VERSION ""

NS_ :

BS_:

BU_: ETH

BO_ 1469 IBST_alertLog: 8 Vector__XXX
 SG_ IBST_alertID : 0|8@1+ (1,0) [0|0] "" Vector__XXX
 SG_ IBST_alertState : 15|1@1+ (1,0) [0|0] "" Vector__XXX

BO_ 1481 APS_alertLog: 8 Vector__XXX
 SG_ APS_alertID M : 0|14@1+ (1,0) [0|0] "" Vector__XXX
 SG_ APS_alertSource : 14|1@1+ (1,0) [0|0] "" Vector__XXX
 SG_ APS_alertState : 15|1@1+ (1,0) [0|0] "" Vector__XXX
 SG_ APS_sw001_APS_alertDataW0 m1 : 16|16@1+ (1,0) [0|0] "" Vector__XXX
 SG_ APS_sw004_radIssue m4 : 16|1@1+ (1,0) [0|0] "" Vector__XXX
 SG_ APS_sw005_AutofixOutOfCalib m5 : 16|1@1+ (1,0) [0|0] "" Vector__XXX
 SG_ APS_sw006_RadarLowVisibility m6 : 16|1@1+ (1,0) [0|0] "" Vector__XXX
 SG_ APS_sw009_DIaebState_fault m9 : 16|1@1+ (1,0) [0|0] "" Vector__XXX
 SG_ APS_sw010_a04calibNotDone m10 : 16|1@1+ (1,0) [0|0] "" Vector__XXX
 SG_ APS_sw011_scaState m11 : 16|3@1+ (1,0) [0|0] "" Vector__XXX
 SG_ APS_sw012_bootTestResults m12 : 16|16@1+ (1,0) [0|0] "" Vector__XXX
 SG_ APS_sw013_stateBeforeWatchdog m13 : 16|5@1+ (1,0) [0|0] "" Vector__XXX
 SG_ APS_sw014_fileNameHash m14 : 16|16@1+ (1,0) [0|0] "" Vector__XXX
 SG_ APS_sw015_RadarLowVisibility m15 : 16|2@1+ (1,0) [0|0] "" Vector__XXX
 SG_ APS_sw016_targetDist m16 : 16|9@1+ (0.2,0) [0|0] "" Vector__XXX
 SG_ APS_sw017_Camera_Msg_Lanes_MIA m17 : 16|1@1+ (1,0) [0|0] "" Vector__XXX
 SG_ APS_sw018_minThreshold m18 : 16|13@1+ (1,0) [0|0] "" Vector__XXX
 SG_ APS_sw019_taskId m19 : 16|8@1+ (1,0) [0|0] "" Vector__XXX
 SG_ APS_sw020_unusedW0 m20 : 16|16@1+ (1,0) [0|0] "" Vector__XXX
 SG_ APS_sw021_tempSensorId m21 : 16|8@1+ (1,0) [0|0] "" Vector__XXX
 SG_ APS_sw022_operation m22 : 16|4@1+ (1,0) [0|0] "" Vector__XXX
 SG_ APS_sw024_Task_ID m24 : 16|4@1+ (1,0) [0|0] "" Vector__XXX
 SG_ APS_sw025_state_before_override m25 : 16|4@1+ (1,0) [0|0] "" Vector__XXX
 SG_ APS_sw026_task_id m26 : 16|2@1+ (1,0) [0|0] "" Vector__XXX
 SG_ APS_sw027_JTAG_Reset m27 : 16|1@1+ (1,0) [0|0] "" Vector__XXX
 SG_ APS_sw028_rx_buffer_full m28 : 16|1@1+ (1,0) [0|0] "" Vector__XXX
 SG_ APS_sw029_tx_buffer_full m29 : 16|1@1+ (1,0) [0|0] "" Vector__XXX
 SG_ APS_sw030_heaterState m30 : 16|8@1+ (1,0) [0|0] "" Vector__XXX
 SG_ APS_sw031_canBus m31 : 16|4@1+ (1,0) [0|0] "" Vector__XXX
 SG_ APS_sw032_canBus m32 : 16|4@1+ (1,0) [0|0] "" Vector__XXX
 SG_ APS_sw033_carConfig m33 : 16|1@1+ (1,0) [0|0] "" Vector__XXX
 SG_ APS_sw034_sccmMia m34 : 16|8@1+ (1,0) [0|0] "" Vector__XXX
 SG_ APS_sw035_wheelSpeeds m35 : 16|1@1+ (1,0) [0|0] "" Vector__XXX
 SG_ APS_sw036_bdyMia m36 : 16|8@1+ (1,0) [0|0] "" Vector__XXX
 SG_ APS_sw037_camera m37 : 16|8@1+ (1,0) [0|0] "" Vector__XXX
 SG_ APS_sw038_RadarMisalignment m38 : 16|1@1+ (1,0) [0|0] "" Vector__XXX
 SG_ APS_sw039_sdm_rcm_Mia m39 : 16|8@1+ (1,0) [0|0] "" Vector__XXX
 SG_ APS_sw040_accel_pedal_pos m40 : 16|8@1+ (0.5,0) [0|0] "" Vector__XXX
 SG_ APS_sw041_rate m41 : 16|10@1- (1,0) [0|0] "" Vector__XXX
 SG_ APS_sw042_health_state m42 : 16|3@1+ (1,0) [0|0] "" Vector__XXX
 SG_ APS_sw043_mobileye_status m43 : 16|16@1+ (1,0) [0|0] "" Vector__XXX
 SG_ APS_sw044_countLSB m44 : 16|8@1+ (1,0) [0|0] "" Vector__XXX
 SG_ APS_sw045_radMia m45 : 16|8@1+ (1,0) [0|0] "" Vector__XXX
 SG_ APS_sw046_recordId m46 : 16|16@1+ (1,0) [0|0] "" Vector__XXX
 SG_ APS_sw047_edrStatus m47 : 16|4@1+ (1,0) [0|0] "" Vector__XXX
 SG_ APS_sw048_swAssert m48 : 16|1@1+ (1,0) [0|0] "" Vector__XXX
 SG_ APS_sw049_boot_version_msw m49 : 16|16@1+ (1,0) [0|0] "" Vector__XXX
 SG_ APS_sw050_targetDist m50 : 16|9@1+ (0.2,0) [0|0] "" Vector__XXX
 SG_ APS_sw051_a01ecuInternalPerf m51 : 16|1@1+ (1,0) [0|0] "" Vector__XXX
 SG_ APS_sw052_a07sensorBlinded m52 : 16|1@1+ (1,0) [0|0] "" Vector__XXX
 SG_ APS_sw053_a10canBusOff m53 : 16|1@1+ (1,0) [0|0] "" Vector__XXX
 SG_ APS_sw054_Autofix_cnvrgnceStatus m54 : 16|8@1+ (1,0) [0|0] "" Vector__XXX
 SG_ APS_sw055_detectedRadcVersion m55 : 16|32@1+ (1,0) [0|0] "" Vector__XXX
 SG_ APS_sw056_diMia m56 : 16|8@1+ (1,0) [0|0] "" Vector__XXX
 SG_ APS_sw057_driverAssistMapData m57 : 16|1@1+ (1,0) [0|0] "" Vector__XXX
 SG_ APS_sw058_epbMia m58 : 16|8@1+ (1,0) [0|0] "" Vector__XXX
 SG_ APS_sw059_sdiFront m59 : 16|1@1+ (1,0) [0|0] "" Vector__XXX
 SG_ APS_sw060_targetDist m60 : 16|9@1+ (0.2,0) [0|0] "" Vector__XXX
 SG_ APS_sw061_states m61 : 16|1@1+ (1,0) [0|0] "" Vector__XXX
 SG_ APS_sw062_HorizontalMisalignment m62 : 16|16@1+ (0.00137332,-45) [0|0] "" Vector__XXX
 SG_ APS_sw063_expectedMajorVer m63 : 16|8@1+ (1,0) [0|0] "" Vector__XXX
 SG_ APS_sw064_sysStatus m64 : 16|1@1+ (1,0) [0|0] "" Vector__XXX
 SG_ APS_sw065_app_mobileye_status m65 : 16|8@1+ (1,0) [0|0] "" Vector__XXX
 SG_ APS_sw066_app_mobileye_status m66 : 16|8@1+ (1,0) [0|0] "" Vector__XXX
 SG_ APS_sw067_sccmSTW m67 : 16|14@1+ (0.1,-819.2) [0|0] "" Vector__XXX
 SG_ APS_sw068_percentConsistency m68 : 16|10@1+ (0.1,0) [0|0] "" Vector__XXX
 SG_ APS_sw069_epasMia m69 : 16|1@1+ (1,0) [0|0] "" Vector__XXX
 SG_ APS_sw070_currTireFitment m70 : 16|3@1+ (1,0) [0|0] "" Vector__XXX
 SG_ APS_sw071_selfParkType m71 : 16|4@1+ (1,0) [0|0] "" Vector__XXX
 SG_ APS_sw072_vehicleX m72 : 16|10@1+ (0.05,-25.6) [0|0] "" Vector__XXX
 SG_ APS_sw073_escalateLDWs m73 : 16|1@1+ (1,0) [0|0] "" Vector__XXX
 SG_ APS_sw074_ipsoDx m74 : 16|6@1+ (2,0) [0|0] "" Vector__XXX
 SG_ APS_sw075_scMia m75 : 16|8@1+ (1,0) [0|0] "" Vector__XXX
 SG_ APS_sw076_targetDist m76 : 16|9@1+ (0.2,0) [0|0] "" Vector__XXX
 SG_ APS_sw077_oocDistance m77 : 16|9@1+ (1,0) [0|0] "" Vector__XXX
 SG_ APS_sw078_camCipv_dx m78 : 16|8@1+ (0.2,0) [0|0] "" Vector__XXX
 SG_ APS_sw080_sensors_healty_check m80 : 16|1@1+ (1,0) [0|0] "" Vector__XXX
 SG_ APS_sw081_radarDistance m81 : 16|8@1+ (0.0625,0) [0|0] "" Vector__XXX
 SG_ APS_sw082_L_VL m82 : 16|8@1+ (0.05,-6.4) [0|0] "" Vector__XXX
 SG_ APS_sw083_Targ5_RCS m83 : 16|16@1+ (0.0039063096,0) [0|0] "" Vector__XXX
 SG_ APS_sw084_ipsoTTC m84 : 16|8@1+ (0.02,0) [0|0] "" Vector__XXX
 SG_ APS_sw085_radarDistance m85 : 16|8@1+ (0.0625,0) [0|0] "" Vector__XXX
 SG_ APS_sw086_distanceException m86 : 16|8@1+ (1,90) [0|0] "" Vector__XXX
 SG_ APS_sw103_objectDx m103 : 16|8@1+ (0.5,0) [0|0] "" Vector__XXX
 SG_ APS_sw106_torsionBarOffset m106 : 16|8@1+ (0.005,-0.64) [0|0] "" Vector__XXX
 SG_ APS_sw129_currentVoltage m129 : 16|14@1+ (1,0) [0|0] "" Vector__XXX
 SG_ APS_sw130_currentTemperature m130 : 16|8@1- (1,0) [0|0] "" Vector__XXX
 SG_ APS_sw131_trapAddr m131 : 16|32@1+ (1,0) [0|0] "" Vector__XXX
 SG_ APS_sw132_mismatchType m132 : 16|1@1+ (1,0) [0|0] "" Vector__XXX
 SG_ APS_sw133_failedInitStep m133 : 16|8@1+ (1,0) [0|0] "" Vector__XXX
 SG_ APS_sw134_appCamCalibStatus m134 : 16|1@1+ (1,0) [0|0] "" Vector__XXX
 SG_ APS_sw135_appCriticalReason m135 : 16|4@1+ (1,0) [0|0] "" Vector__XXX
 SG_ APS_sw136_gpsCommIrrecoverable m136 : 16|1@1+ (1,0) [0|0] "" Vector__XXX
 SG_ APS_sw137_gpsCommMissing m137 : 16|1@1+ (1,0) [0|0] "" Vector__XXX
 SG_ APS_sw138_cfgBufNull m138 : 16|1@1+ (1,0) [0|0] "" Vector__XXX
 SG_ APS_sw139_numMessagesRx m139 : 16|8@1+ (1,0) [0|0] "" Vector__XXX
 SG_ APS_sw140_lvPowerState m140 : 16|1@1+ (1,0) [0|0] "" Vector__XXX
 SG_ APS_sw141_inertial1 m141 : 16|1@1+ (1,0) [0|0] "" Vector__XXX
 SG_ APS_sw142_speed m142 : 16|1@1+ (1,0) [0|0] "" Vector__XXX
 SG_ APS_sw143_status m143 : 16|1@1+ (1,0) [0|0] "" Vector__XXX
 SG_ APS_sw144_restraintStatus m144 : 16|1@1+ (1,0) [0|0] "" Vector__XXX
 SG_ APS_sw145_restraintStatus m145 : 16|1@1+ (1,0) [0|0] "" Vector__XXX
 SG_ APS_sw146_sysStatus m146 : 16|1@1+ (1,0) [0|0] "" Vector__XXX
 SG_ APS_sw147_doorStatus m147 : 16|1@1+ (1,0) [0|0] "" Vector__XXX
 SG_ APS_sw148_doorStatus m148 : 16|1@1+ (1,0) [0|0] "" Vector__XXX
 SG_ APS_sw149_status m149 : 16|1@1+ (1,0) [0|0] "" Vector__XXX
 SG_ APS_sw150_steeringAngleSensor m150 : 16|1@1+ (1,0) [0|0] "" Vector__XXX
 SG_ APS_sw151_apGpioState m151 : 16|2@1+ (1,0) [0|0] "" Vector__XXX
 SG_ APS_sw152_fusionStatus m152 : 16|2@1+ (1,0) [0|0] "" Vector__XXX
 SG_ APS_sw153_eacInhibitReason m153 : 16|4@1+ (1,0) [0|0] "" Vector__XXX
 SG_ APS_sw155_InUnicastError m155 : 16|1@1+ (1,0) [0|0] "" Vector__XXX
 SG_ APS_sw156_LWIPAssertLine m156 : 16|16@1+ (1,0) [0|0] "" Vector__XXX
 SG_ APS_sw158_apbInfo m158 : 16|1@1+ (1,0) [0|0] "" Vector__XXX
 SG_ APS_sw159_apbCriticalReason m159 : 16|4@1+ (1,0) [0|0] "" Vector__XXX
 SG_ APS_sw160_mismatchType m160 : 16|1@1+ (1,0) [0|0] "" Vector__XXX
 SG_ APS_sw161_antennaDisconnected m161 : 16|1@1+ (1,0) [0|0] "" Vector__XXX
 SG_ APS_sw162_disRegPgoodFail m162 : 16|1@1+ (1,0) [0|0] "" Vector__XXX
 SG_ APS_sw171_1HzTask m171 : 16|1@1+ (1,0) [0|0] "" Vector__XXX
 SG_ APS_sw172_prolongedUiMia m172 : 16|1@1+ (1,0) [0|0] "" Vector__XXX
 SG_ APS_sw187_1HzTask m187 : 16|1@1+ (1,0) [0|0] "" Vector__XXX
 SG_ APS_sw188_otherTurbo m188 : 16|2@1+ (1,0) [0|0] "" Vector__XXX
 SG_ APS_sw189_AP_vehicleState10Hz m189 : 16|1@1+ (1,0) [0|0] "" Vector__XXX
 SG_ APS_sw190_IBST_status m190 : 16|1@1+ (1,0) [0|0] "" Vector__XXX
 SG_ APS_sw191_a72Uninitialized m191 : 16|1@1+ (1,0) [0|0] "" Vector__XXX
 SG_ APS_sw192_CANbus m192 : 16|3@1+ (1,0) [0|0] "" Vector__XXX
 SG_ APS_sw193_blurredImage m193 : 16|1@1+ (1,0) [0|0] "" Vector__XXX
 SG_ APS_sw194_leadAx m194 : 16|6@1- (0.2,0) [0|0] "" Vector__XXX
 SG_ APS_sw195_s1Blocked m195 : 16|1@1+ (1,0) [0|0] "" Vector__XXX
 SG_ APS_sw198_fullBlockage m198 : 16|1@1+ (1,0) [0|0] "" Vector__XXX
 SG_ APS_sw199_abortCodeDas m199 : 16|6@1+ (1,0) [0|0] "" Vector__XXX
 SG_ APS_sw200_autopilotIntState m200 : 16|4@1+ (1,0) [0|0] "" Vector__XXX
 SG_ APS_sw201_virtualLaneInputOAL m201 : 16|3@1+ (1,0) [0|0] "" Vector__XXX
 SG_ APS_sw202_s1Blocked m202 : 16|1@1+ (1,0) [0|0] "" Vector__XXX
 SG_ APS_sw203_controlType m203 : 16|4@1+ (1,0) [0|0] "" Vector__XXX
 SG_ APS_sw204_frLeft m204 : 16|8@1+ (1,0) [0|0] "" Vector__XXX
 SG_ APS_sw205_oocDistance m205 : 16|8@1+ (1,0) [0|0] "" Vector__XXX
 SG_ APS_sw207_appMobileyeStatus m207 : 16|8@1+ (1,0) [0|0] "" Vector__XXX
 SG_ APS_sw213_autopilotIntState m213 : 16|4@1+ (1,0) [0|0] "" Vector__XXX
 SG_ APS_sw218_cipvDist m218 : 16|8@1+ (0.2,0) [0|0] "" Vector__XXX
 SG_ APS_sw219_controlledAccess m219 : 16|1@1+ (1,0) [0|0] "" Vector__XXX
 SG_ APS_sw220_controlledAccess m220 : 16|1@1+ (1,0) [0|0] "" Vector__XXX
 SG_ APS_sw227_sensorSide m227 : 16|1@1+ (1,0) [0|0] "" Vector__XXX
 SG_ APS_sw230_sensor1Blocked m230 : 16|1@1+ (1,0) [0|0] "" Vector__XXX
 SG_ APS_sw231_timeToImpact m231 : 16|9@1+ (1,0) [0|0] "" Vector__XXX
 SG_ APS_sw235_resetOrigin m235 : 16|2@1+ (1,0) [0|0] "" Vector__XXX
 SG_ APS_sw236_fifoSizeInvalid m236 : 16|1@1+ (1,0) [0|0] "" Vector__XXX
 SG_ APS_sw237_faultSource m237 : 16|7@1+ (1,0) [0|0] "" Vector__XXX
 SG_ APS_sw238_shutdownPin m238 : 16|1@1+ (1,0) [0|0] "" Vector__XXX
 SG_ APS_sw241_unknownVendorOnResume m241 : 16|1@1+ (1,0) [0|0] "" Vector__XXX
 SG_ APS_sw242_instance m242 : 16|3@1+ (1,0) [0|0] "" Vector__XXX
 SG_ APS_sw243_instance m243 : 16|3@1+ (1,0) [0|0] "" Vector__XXX
 SG_ APS_sw244_instance m244 : 16|3@1+ (1,0) [0|0] "" Vector__XXX
 SG_ APS_sw245_unknownMACAddrByte0 m245 : 16|8@1+ (1,0) [0|0] "" Vector__XXX
 SG_ APS_sw246_ethloopSwitchPort0 m246 : 16|1@1+ (1,0) [0|0] "" Vector__XXX
 SG_ APS_sw247_crcError m247 : 16|1@1+ (1,0) [0|0] "" Vector__XXX
 SG_ APS_sw248_ethloopSwitchPort2Sqi m248 : 16|3@1+ (1,0) [0|0] "" Vector__XXX
 SG_ APS_sw249_ufsInitFailureReason m249 : 16|3@1+ (1,0) [0|0] "" Vector__XXX
 SG_ APS_sw250_rxPacketDrop m250 : 16|12@1+ (1,0) [0|0] "" Vector__XXX
 SG_ APS_sw251_rxPacketDrop m251 : 16|12@1+ (1,0) [0|0] "" Vector__XXX
 SG_ APS_sw252_ethSwitchPort2 m252 : 16|1@1+ (1,0) [0|0] "" Vector__XXX
 SG_ APS_sw253_apWaitForShutdownTimeout m253 : 16|1@1+ (1,0) [0|0] "" Vector__XXX
 SG_ APS_sw254_waitForBusSilenceTimeout m254 : 16|1@1+ (1,0) [0|0] "" Vector__XXX
 SG_ APS_sw255_unknownBootError m255 : 16|1@1+ (1,0) [0|0] "" Vector__XXX
 SG_ APS_sw257_assertAddress m257 : 16|32@1+ (1,0) [0|0] "" Vector__XXX
 SG_ APS_sw258_actualValue m258 : 16|32@1+ (1,0) [0|0] "" Vector__XXX
 SG_ APS_sw259_qspiProgramError m259 : 16|1@1+ (1,0) [0|0] "" Vector__XXX
 SG_ APS_sw260_pgoodTripSramStatus m260 : 16|8@1+ (1,0) [0|0] "" Vector__XXX
 SG_ APS_sw261_vrmPublicFaultValues m261 : 16|16@1+ (1,0) [0|0] "" Vector__XXX
 SG_ APS_sw262_vrmPublicFaultValues m262 : 16|16@1+ (1,0) [0|0] "" Vector__XXX
 SG_ APS_sw263_vrmPublicFaultValues m263 : 16|16@1+ (1,0) [0|0] "" Vector__XXX
 SG_ APS_sw264_rdlvl_bitlock m264 : 16|1@1+ (1,0) [0|0] "" Vector__XXX
 SG_ APS_sw265_rdlvl_bitlock m265 : 16|1@1+ (1,0) [0|0] "" Vector__XXX
 SG_ APS_sw266_rdlvl_bitlock m266 : 16|1@1+ (1,0) [0|0] "" Vector__XXX
 SG_ APS_sw267_rdlvl_bitlock m267 : 16|1@1+ (1,0) [0|0] "" Vector__XXX
 SG_ APS_sw268_rd_uncorrectable_crc0 m268 : 16|1@1+ (1,0) [0|0] "" Vector__XXX
 SG_ APS_sw269_RxPageCountPort0 m269 : 16|12@1+ (1,0) [0|0] "" Vector__XXX
 SG_ APS_sw270_RxPageCountPort4 m270 : 16|12@1+ (1,0) [0|0] "" Vector__XXX
 SG_ APS_sw271_wrUncorrectableErrInBufferToDram m271 : 16|1@1+ (1,0) [0|0] "" Vector__XXX
 SG_ APS_sw272_wrUncorrectableErrInBufferToDram m272 : 16|1@1+ (1,0) [0|0] "" Vector__XXX
 SG_ APS_sw273_wrUncorrectableErrInBufferToDram m273 : 16|1@1+ (1,0) [0|0] "" Vector__XXX
 SG_ APS_sw274_wrUncorrectableErrInBufferToDram m274 : 16|1@1+ (1,0) [0|0] "" Vector__XXX
 SG_ APS_sw275_wrUncorrectableErrInBufferToDram m275 : 16|1@1+ (1,0) [0|0] "" Vector__XXX
 SG_ APS_sw276_wrUncorrectableErrInBufferToDram m276 : 16|1@1+ (1,0) [0|0] "" Vector__XXX
 SG_ APS_sw277_wrUncorrectableErrInBufferToDram m277 : 16|1@1+ (1,0) [0|0] "" Vector__XXX
 SG_ APS_sw278_wrUncorrectableErrInBufferToDram m278 : 16|1@1+ (1,0) [0|0] "" Vector__XXX
 SG_ APS_sw279_corruptDirectorySource m279 : 16|3@1+ (1,0) [0|0] "" Vector__XXX
 SG_ APS_sw280_pepsStatus m280 : 16|1@1+ (1,0) [0|0] "" Vector__XXX
 SG_ APS_sw281_rearSteerStatus m281 : 16|1@1+ (1,0) [0|0] "" Vector__XXX
 SG_ APS_sw282_smmuErrorId m282 : 16|3@1+ (1,0) [0|0] "" Vector__XXX
 SG_ APS_sw283_psfaStatus m283 : 16|1@1+ (1,0) [0|0] "" Vector__XXX
 SG_ APS_sw288_status m288 : 16|1@1+ (1,0) [0|0] "" Vector__XXX
 SG_ APS_sw289_turboTemperature m289 : 16|8@1- (1,0) [0|0] "" Vector__XXX
 SG_ APS_sw291_fifoError m291 : 16|1@1+ (1,0) [0|0] "" Vector__XXX
 SG_ APS_sw292_warningErrorCount m292 : 16|8@1+ (1,0) [0|0] "" Vector__XXX
 SG_ APS_sw293_warningErrorCount m293 : 16|8@1+ (1,0) [0|0] "" Vector__XXX
 SG_ APS_sw294_warningErrorCount m294 : 16|8@1+ (1,0) [0|0] "" Vector__XXX
 SG_ APS_sw295_warningErrorCount m295 : 16|8@1+ (1,0) [0|0] "" Vector__XXX
 SG_ APS_sw296_wdogMonTaskID m296 : 16|5@1+ (1,0) [0|0] "" Vector__XXX
 SG_ APS_sw297_earlyWDog m297 : 16|1@1+ (1,0) [0|0] "" Vector__XXX
 SG_ APS_sw298_cpuToApFailedCount m298 : 16|8@1+ (1,0) [0|0] "" Vector__XXX
 SG_ APS_sw299_apToCpuFailedCount m299 : 16|8@1+ (1,0) [0|0] "" Vector__XXX
 SG_ APS_sw300_messageRingMagicValue m300 : 16|32@1+ (1,0) [0|0] "" Vector__XXX
 SG_ APS_sw301_nocType m301 : 16|4@1+ (1,0) [0|0] "" Vector__XXX
 SG_ APS_sw302_cpuToApFifoFullCount m302 : 16|8@1+ (1,0) [0|0] "" Vector__XXX
 SG_ APS_sw303_apToCpuFifoEmptyCount m303 : 16|8@1+ (1,0) [0|0] "" Vector__XXX
 SG_ APS_sw304_exceptionCode m304 : 16|5@1+ (1,0) [0|0] "" Vector__XXX
 SG_ APS_sw307_secEvent m307 : 16|8@1+ (1,0) [0|0] "" Vector__XXX
 SG_ APS_sw308_pmicWatchDogFeedError m308 : 16|1@1+ (1,0) [0|0] "" Vector__XXX
 SG_ APS_sw310_sysStatus m310 : 16|1@1+ (1,0) [0|0] "" Vector__XXX
 SG_ APS_sw311_dasAutonomyControl m311 : 16|1@1+ (1,0) [0|0] "" Vector__XXX
 SG_ APS_sw312_appStatus m312 : 16|1@1+ (1,0) [0|0] "" Vector__XXX
 SG_ APS_sw313_warningErrorCount m313 : 16|8@1+ (1,0) [0|0] "" Vector__XXX
 SG_ APS_sw315_sysStatus m315 : 16|1@1+ (1,0) [0|0] "" Vector__XXX
 SG_ APS_sw316_powerCameraTimeout m316 : 16|1@1+ (1,0) [0|0] "" Vector__XXX
 SG_ APS_sw004_radHWFailure m4 : 17|1@1+ (1,0) [0|0] "" Vector__XXX
 SG_ APS_sw005_AutofixOutOfCalibYaw m5 : 17|1@1+ (1,0) [0|0] "" Vector__XXX
 SG_ APS_sw006_RadarMisaligned m6 : 17|1@1+ (1,0) [0|0] "" Vector__XXX
 SG_ APS_sw009_DI_aeb_unresponsive m9 : 17|1@1+ (1,0) [0|0] "" Vector__XXX
 SG_ APS_sw010_a05calibReqd m10 : 17|1@1+ (1,0) [0|0] "" Vector__XXX
 SG_ APS_sw017_Camera_Msg_Objects_MIA m17 : 17|1@1+ (1,0) [0|0] "" Vector__XXX
 SG_ APS_sw027_Core_Reset m27 : 17|1@1+ (1,0) [0|0] "" Vector__XXX
 SG_ APS_sw028_rx_inv_len m28 : 17|1@1+ (1,0) [0|0] "" Vector__XXX
 SG_ APS_sw029_unusedBits m29 : 17|15@1+ (1,0) [0|0] "" Vector__XXX
 SG_ APS_sw033_chNm m33 : 17|1@1+ (1,0) [0|0] "" Vector__XXX
 SG_ APS_sw035_status m35 : 17|1@1+ (1,0) [0|0] "" Vector__XXX
 SG_ APS_sw038_OutOfFocusImage m38 : 17|1@1+ (1,0) [0|0] "" Vector__XXX
 SG_ APS_sw048_thermalIssue m48 : 17|1@1+ (1,0) [0|0] "" Vector__XXX
 SG_ APS_sw051_a02flashPerformance m51 : 17|1@1+ (1,0) [0|0] "" Vector__XXX
 SG_ APS_sw052_sensorDirty m52 : 17|1@1+ (1,0) [0|0] "" Vector__XXX
 SG_ APS_sw053_a11bdyMIA m53 : 17|1@1+ (1,0) [0|0] "" Vector__XXX
 SG_ APS_sw057_locationStatus m57 : 17|1@1+ (1,0) [0|0] "" Vector__XXX
 SG_ APS_sw059_sdiRear m59 : 17|1@1+ (1,0) [0|0] "" Vector__XXX
 SG_ APS_sw064_status m64 : 17|1@1+ (1,0) [0|0] "" Vector__XXX
 SG_ APS_sw069_espMia m69 : 17|1@1+ (1,0) [0|0] "" Vector__XXX
 SG_ APS_sw073_silentEscalatedLDW m73 : 17|1@1+ (1,0) [0|0] "" Vector__XXX
 SG_ APS_sw080_dist_travelled_check m80 : 17|1@1+ (1,0) [0|0] "" Vector__XXX
 SG_ APS_sw134_appCameraLux m134 : 17|1@1+ (1,0) [0|0] "" Vector__XXX
 SG_ APS_sw136_fusionIrrecoverable m136 : 17|1@1+ (1,0) [0|0] "" Vector__XXX
 SG_ APS_sw137_gpsJunkData m137 : 17|1@1+ (1,0) [0|0] "" Vector__XXX
 SG_ APS_sw138_invalidID m138 : 17|1@1+ (1,0) [0|0] "" Vector__XXX
 SG_ APS_sw140_vehicleStatus m140 : 17|1@1+ (1,0) [0|0] "" Vector__XXX
 SG_ APS_sw141_inertial2 m141 : 17|1@1+ (1,0) [0|0] "" Vector__XXX
 SG_ APS_sw142_locStatus m142 : 17|1@1+ (1,0) [0|0] "" Vector__XXX
 SG_ APS_sw143_wheelRotation m143 : 17|1@1+ (1,0) [0|0] "" Vector__XXX
 SG_ APS_sw146_status m146 : 17|1@1+ (1,0) [0|0] "" Vector__XXX
 SG_ APS_sw147_switchStatus m147 : 17|1@1+ (1,0) [0|0] "" Vector__XXX
 SG_ APS_sw148_hvacStatus m148 : 17|1@1+ (1,0) [0|0] "" Vector__XXX
 SG_ APS_sw150_rightStalk m150 : 17|1@1+ (1,0) [0|0] "" Vector__XXX
 SG_ APS_sw155_UDPRecvError m155 : 17|1@1+ (1,0) [0|0] "" Vector__XXX
 SG_ APS_sw158_apbStatus m158 : 17|1@1+ (1,0) [0|0] "" Vector__XXX
 SG_ APS_sw162_disRegPgoodDbnFail m162 : 17|1@1+ (1,0) [0|0] "" Vector__XXX
 SG_ APS_sw171_1kHzTask m171 : 17|1@1+ (1,0) [0|0] "" Vector__XXX
 SG_ APS_sw172_uiMiaAtBootup m172 : 17|1@1+ (1,0) [0|0] "" Vector__XXX
 SG_ APS_sw187_1kHzTask m187 : 17|1@1+ (1,0) [0|0] "" Vector__XXX
 SG_ APS_sw189_AP_vehicleState1Hz m189 : 17|1@1+ (1,0) [0|0] "" Vector__XXX
 SG_ APS_sw191_a72PhaseError m191 : 17|1@1+ (1,0) [0|0] "" Vector__XXX
 SG_ APS_sw193_fullBlockage m193 : 17|1@1+ (1,0) [0|0] "" Vector__XXX
 SG_ APS_sw195_s6Blocked m195 : 17|1@1+ (1,0) [0|0] "" Vector__XXX
 SG_ APS_sw198_partialBlockage m198 : 17|1@1+ (1,0) [0|0] "" Vector__XXX
 SG_ APS_sw202_s6Blocked m202 : 17|1@1+ (1,0) [0|0] "" Vector__XXX
 SG_ APS_sw219_roadClass m219 : 17|3@1+ (1,0) [0|0] "" Vector__XXX
 SG_ APS_sw220_roadClass m220 : 17|3@1+ (1,0) [0|0] "" Vector__XXX
 SG_ APS_sw227_sensorNumber m227 : 17|1@1+ (1,0) [0|0] "" Vector__XXX
 SG_ APS_sw230_sensor2Blocked m230 : 17|1@1+ (1,0) [0|0] "" Vector__XXX
 SG_ APS_sw236_nocRemapInvalid m236 : 17|1@1+ (1,0) [0|0] "" Vector__XXX
 SG_ APS_sw238_externalWatchdog m238 : 17|1@1+ (1,0) [0|0] "" Vector__XXX
 SG_ APS_sw241_unknownVendorOnNonResume m241 : 17|1@1+ (1,0) [0|0] "" Vector__XXX
 SG_ APS_sw246_ethloopSwitchPort1 m246 : 17|1@1+ (1,0) [0|0] "" Vector__XXX
 SG_ APS_sw247_dribbleError m247 : 17|1@1+ (1,0) [0|0] "" Vector__XXX
 SG_ APS_sw253_apOffPrepareTimeout m253 : 17|1@1+ (1,0) [0|0] "" Vector__XXX
 SG_ APS_sw254_sleepReadyTimeout m254 : 17|1@1+ (1,0) [0|0] "" Vector__XXX
 SG_ APS_sw255_adcWrapperInitBootError m255 : 17|1@1+ (1,0) [0|0] "" Vector__XXX
 SG_ APS_sw259_qspiEraseError m259 : 17|1@1+ (1,0) [0|0] "" Vector__XXX
 SG_ APS_sw264_rdlvl_vref_not_in_range m264 : 17|1@1+ (1,0) [0|0] "" Vector__XXX
 SG_ APS_sw265_rdlvl_vref_not_in_range m265 : 17|1@1+ (1,0) [0|0] "" Vector__XXX
 SG_ APS_sw266_rdlvl_vref_not_in_range m266 : 17|1@1+ (1,0) [0|0] "" Vector__XXX
 SG_ APS_sw267_rdlvl_vref_not_in_range m267 : 17|1@1+ (1,0) [0|0] "" Vector__XXX
 SG_ APS_sw268_rd_correctable_crc0 m268 : 17|1@1+ (1,0) [0|0] "" Vector__XXX
 SG_ APS_sw271_rdUncorrectableErrFromBuffer m271 : 17|1@1+ (1,0) [0|0] "" Vector__XXX
 SG_ APS_sw272_rdUncorrectableErrFromBuffer m272 : 17|1@1+ (1,0) [0|0] "" Vector__XXX
 SG_ APS_sw273_rdUncorrectableErrFromBuffer m273 : 17|1@1+ (1,0) [0|0] "" Vector__XXX
 SG_ APS_sw274_rdUncorrectableErrFromBuffer m274 : 17|1@1+ (1,0) [0|0] "" Vector__XXX
 SG_ APS_sw275_rdUncorrectableErrFromBuffer m275 : 17|1@1+ (1,0) [0|0] "" Vector__XXX
 SG_ APS_sw276_rdUncorrectableErrFromBuffer m276 : 17|1@1+ (1,0) [0|0] "" Vector__XXX
 SG_ APS_sw277_rdUncorrectableErrFromBuffer m277 : 17|1@1+ (1,0) [0|0] "" Vector__XXX
 SG_ APS_sw278_rdUncorrectableErrFromBuffer m278 : 17|1@1+ (1,0) [0|0] "" Vector__XXX
 SG_ APS_sw291_crcError m291 : 17|1@1+ (1,0) [0|0] "" Vector__XXX
 SG_ APS_sw297_wdogMonStatus m297 : 17|4@1+ (1,0) [0|0] "" Vector__XXX
 SG_ APS_sw310_status m310 : 17|1@1+ (1,0) [0|0] "" Vector__XXX
 SG_ APS_sw311_dasControl m311 : 17|1@1+ (1,0) [0|0] "" Vector__XXX
 SG_ APS_sw312_apbStatus m312 : 17|1@1+ (1,0) [0|0] "" Vector__XXX
 SG_ APS_sw315_status m315 : 17|1@1+ (1,0) [0|0] "" Vector__XXX
 SG_ APS_sw004_radSensorBlind m4 : 18|1@1+ (1,0) [0|0] "" Vector__XXX
 SG_ APS_sw005_RadarMisalignment m5 : 18|1@1+ (1,0) [0|0] "" Vector__XXX
 SG_ APS_sw006_radCalibration m6 : 18|1@1+ (1,0) [0|0] "" Vector__XXX
 SG_ APS_sw009_DI_MIA m9 : 18|1@1+ (1,0) [0|0] "" Vector__XXX
 SG_ APS_sw010_a06calibNotOK m10 : 18|1@1+ (1,0) [0|0] "" Vector__XXX
 SG_ APS_sw015_RadarMisalignment m15 : 18|2@1+ (1,0) [0|0] "" Vector__XXX
 SG_ APS_sw017_Camera_Msg_Tsr_MIA m17 : 18|1@1+ (1,0) [0|0] "" Vector__XXX
 SG_ APS_sw026_tardiness m26 : 18|9@1+ (0.25,0) [0|0] "" Vector__XXX
 SG_ APS_sw027_Unused_Bit_0 m27 : 18|1@1+ (1,0) [0|0] "" Vector__XXX
 SG_ APS_sw028_inv_multifrm_1st m28 : 18|1@1+ (1,0) [0|0] "" Vector__XXX
 SG_ APS_sw033_vin m33 : 18|1@1+ (1,0) [0|0] "" Vector__XXX
 SG_ APS_sw035_wheelRotation m35 : 18|1@1+ (1,0) [0|0] "" Vector__XXX
 SG_ APS_sw038_AutofixOutOfCalib m38 : 18|1@1+ (1,0) [0|0] "" Vector__XXX
 SG_ APS_sw048_powerIssue m48 : 18|1@1+ (1,0) [0|0] "" Vector__XXX
 SG_ APS_sw051_a03vBatHigh m51 : 18|1@1+ (1,0) [0|0] "" Vector__XXX
 SG_ APS_sw052_HWFail m52 : 18|1@1+ (1,0) [0|0] "" Vector__XXX
 SG_ APS_sw053_a12espMIA m53 : 18|1@1+ (1,0) [0|0] "" Vector__XXX
 SG_ APS_sw057_gpsVehicleSpeed m57 : 18|1@1+ (1,0) [0|0] "" Vector__XXX
 SG_ APS_sw059_status m59 : 18|1@1+ (1,0) [0|0] "" Vector__XXX
 SG_ APS_sw069_parkMia m69 : 18|1@1+ (1,0) [0|0] "" Vector__XXX
 SG_ APS_sw073_escalateLDWreason m73 : 18|3@1+ (1,0) [0|0] "" Vector__XXX
 SG_ APS_sw080_road_class_check m80 : 18|1@1+ (1,0) [0|0] "" Vector__XXX
 SG_ APS_sw134_appInfo m134 : 18|1@1+ (1,0) [0|0] "" Vector__XXX
 SG_ APS_sw136_antennaUnplugged m136 : 18|1@1+ (1,0) [0|0] "" Vector__XXX
 SG_ APS_sw137_gpsNMEAmissing m137 : 18|1@1+ (1,0) [0|0] "" Vector__XXX
 SG_ APS_sw138_gpsBufferOverflow m138 : 18|1@1+ (1,0) [0|0] "" Vector__XXX
 SG_ APS_sw140_status m140 : 18|1@1+ (1,0) [0|0] "" Vector__XXX
 SG_ APS_sw142_locStatus2 m142 : 18|1@1+ (1,0) [0|0] "" Vector__XXX
 SG_ APS_sw143_wheelSpeeds m143 : 18|1@1+ (1,0) [0|0] "" Vector__XXX
 SG_ APS_sw150_leftStalk m150 : 18|1@1+ (1,0) [0|0] "" Vector__XXX
 SG_ APS_sw151_apWatchDogState m151 : 18|3@1+ (1,0) [0|0] "" Vector__XXX
 SG_ APS_sw155_UDPMiscError m155 : 18|1@1+ (1,0) [0|0] "" Vector__XXX
 SG_ APS_sw158_dasAutonomyControlParty m158 : 18|1@1+ (1,0) [0|0] "" Vector__XXX
 SG_ APS_sw162_pwrPgoodFail m162 : 18|1@1+ (1,0) [0|0] "" Vector__XXX
 SG_ APS_sw188_arbUartMiaState m188 : 18|1@1+ (1,0) [0|0] "" Vector__XXX
 SG_ APS_sw191_smsPhaseError m191 : 18|1@1+ (1,0) [0|0] "" Vector__XXX
 SG_ APS_sw193_impairedVD m193 : 18|1@1+ (1,0) [0|0] "" Vector__XXX
 SG_ APS_sw195_s7Blocked m195 : 18|1@1+ (1,0) [0|0] "" Vector__XXX
 SG_ APS_sw198_tflMsgInvalid m198 : 18|1@1+ (1,0) [0|0] "" Vector__XXX
 SG_ APS_sw202_s7Blocked m202 : 18|1@1+ (1,0) [0|0] "" Vector__XXX
 SG_ APS_sw227_vehicleSpeed m227 : 18|12@1+ (0.05,-25) [0|0] "" Vector__XXX
 SG_ APS_sw230_sensor3Blocked m230 : 18|1@1+ (1,0) [0|0] "" Vector__XXX
 SG_ APS_sw235_generalUnrecoverable m235 : 18|1@1+ (1,0) [0|0] "" Vector__XXX
 SG_ APS_sw236_txFifoInvalid m236 : 18|1@1+ (1,0) [0|0] "" Vector__XXX
 SG_ APS_sw238_hardReset m238 : 18|1@1+ (1,0) [0|0] "" Vector__XXX
 SG_ APS_sw241_phyReinitFailedOnResume m241 : 18|1@1+ (1,0) [0|0] "" Vector__XXX
 SG_ APS_sw246_ethloopSwitchPort2 m246 : 18|1@1+ (1,0) [0|0] "" Vector__XXX
 SG_ APS_sw247_receiveError m247 : 18|1@1+ (1,0) [0|0] "" Vector__XXX
 SG_ APS_sw253_apSuspendedTimeout m253 : 18|1@1+ (1,0) [0|0] "" Vector__XXX
 SG_ APS_sw254_sleepingTimeout m254 : 18|1@1+ (1,0) [0|0] "" Vector__XXX
 SG_ APS_sw255_boardRevisionInitBootError m255 : 18|1@1+ (1,0) [0|0] "" Vector__XXX
 SG_ APS_sw264_rdlvl_vref_training m264 : 18|1@1+ (1,0) [0|0] "" Vector__XXX
 SG_ APS_sw265_rdlvl_vref_training m265 : 18|1@1+ (1,0) [0|0] "" Vector__XXX
 SG_ APS_sw266_rdlvl_vref_training m266 : 18|1@1+ (1,0) [0|0] "" Vector__XXX
 SG_ APS_sw267_rdlvl_vref_training m267 : 18|1@1+ (1,0) [0|0] "" Vector__XXX
 SG_ APS_sw268_wr_uncorrectable_crc0 m268 : 18|1@1+ (1,0) [0|0] "" Vector__XXX
 SG_ APS_sw271_rdCorrectableErrFromMemory m271 : 18|1@1+ (1,0) [0|0] "" Vector__XXX
 SG_ APS_sw272_rdCorrectableErrFromMemory m272 : 18|1@1+ (1,0) [0|0] "" Vector__XXX
 SG_ APS_sw273_rdCorrectableErrFromMemory m273 : 18|1@1+ (1,0) [0|0] "" Vector__XXX
 SG_ APS_sw274_rdCorrectableErrFromMemory m274 : 18|1@1+ (1,0) [0|0] "" Vector__XXX
 SG_ APS_sw275_rdCorrectableErrFromMemory m275 : 18|1@1+ (1,0) [0|0] "" Vector__XXX
 SG_ APS_sw276_rdCorrectableErrFromMemory m276 : 18|1@1+ (1,0) [0|0] "" Vector__XXX
 SG_ APS_sw277_rdCorrectableErrFromMemory m277 : 18|1@1+ (1,0) [0|0] "" Vector__XXX
 SG_ APS_sw278_rdCorrectableErrFromMemory m278 : 18|1@1+ (1,0) [0|0] "" Vector__XXX
 SG_ APS_sw291_invalidDiscretizationTime m291 : 18|1@1+ (1,0) [0|0] "" Vector__XXX
 SG_ APS_sw311_dasLongControl m311 : 18|1@1+ (1,0) [0|0] "" Vector__XXX
 SG_ APS_sw004_radSGUFailure m4 : 19|1@1+ (1,0) [0|0] "" Vector__XXX
 SG_ APS_sw005_partialBlockage m5 : 19|1@1+ (1,0) [0|0] "" Vector__XXX
 SG_ APS_sw006_OutOfFocusImage m6 : 19|1@1+ (1,0) [0|0] "" Vector__XXX
 SG_ APS_sw010_a08PlantMode m10 : 19|1@1+ (1,0) [0|0] "" Vector__XXX
 SG_ APS_sw011_scaLeft m11 : 19|1@1+ (1,0) [0|0] "" Vector__XXX
 SG_ APS_sw017_Camera_Msg_Hlb_MIA m17 : 19|1@1+ (1,0) [0|0] "" Vector__XXX
 SG_ APS_sw027_CPU_Checkstop_Error m27 : 19|1@1+ (1,0) [0|0] "" Vector__XXX
 SG_ APS_sw028_inv_multifrm_id m28 : 19|1@1+ (1,0) [0|0] "" Vector__XXX
 SG_ APS_sw033_carState m33 : 19|1@1+ (1,0) [0|0] "" Vector__XXX
 SG_ APS_sw035_redundantBrakingStatus m35 : 19|1@1+ (1,0) [0|0] "" Vector__XXX
 SG_ APS_sw038_AutofixOutOfCalibHorzn m38 : 19|1@1+ (1,0) [0|0] "" Vector__XXX
 SG_ APS_sw042_abort_reason m42 : 19|5@1+ (1,0) [0|0] "" Vector__XXX
 SG_ APS_sw048_stackOverflow m48 : 19|1@1+ (1,0) [0|0] "" Vector__XXX
 SG_ APS_sw051_a09configMismatch m51 : 19|1@1+ (1,0) [0|0] "" Vector__XXX
 SG_ APS_sw052_overTemperature m52 : 19|1@1+ (1,0) [0|0] "" Vector__XXX
 SG_ APS_sw053_a13gtwMIA m53 : 19|1@1+ (1,0) [0|0] "" Vector__XXX
 SG_ APS_sw057_autopilotControl m57 : 19|1@1+ (1,0) [0|0] "" Vector__XXX
 SG_ APS_sw059_sensorStatusFront m59 : 19|1@1+ (1,0) [0|0] "" Vector__XXX
 SG_ APS_sw069_sccmMia m69 : 19|1@1+ (1,0) [0|0] "" Vector__XXX
 SG_ APS_sw070_lastTireFitment m70 : 19|3@1+ (1,0) [0|0] "" Vector__XXX
 SG_ APS_sw080_stw_angle_check m80 : 19|1@1+ (1,0) [0|0] "" Vector__XXX
 SG_ APS_sw134_appStatus m134 : 19|1@1+ (1,0) [0|0] "" Vector__XXX
 SG_ APS_sw136_badgpsfix m136 : 19|1@1+ (1,0) [0|0] "" Vector__XXX
 SG_ APS_sw137_gpsUBXmissing m137 : 19|1@1+ (1,0) [0|0] "" Vector__XXX
 SG_ APS_sw138_navx5CfgFailed m138 : 19|1@1+ (1,0) [0|0] "" Vector__XXX
 SG_ APS_sw140_lighting m140 : 19|1@1+ (1,0) [0|0] "" Vector__XXX
 SG_ APS_sw142_systemStatus m142 : 19|1@1+ (1,0) [0|0] "" Vector__XXX
 SG_ APS_sw143_redundantBrakingStatus m143 : 19|1@1+ (1,0) [0|0] "" Vector__XXX
 SG_ APS_sw155_UDPRTEError m155 : 19|1@1+ (1,0) [0|0] "" Vector__XXX
 SG_ APS_sw158_dasAutonomyControlVeh m158 : 19|1@1+ (1,0) [0|0] "" Vector__XXX
 SG_ APS_sw162_pwrPgoodDbnFail m162 : 19|1@1+ (1,0) [0|0] "" Vector__XXX
 SG_ APS_sw188_powerUartMiaState m188 : 19|1@1+ (1,0) [0|0] "" Vector__XXX
 SG_ APS_sw191_a72Timeout m191 : 19|1@1+ (1,0) [0|0] "" Vector__XXX
 SG_ APS_sw192_SWTxQueueFull m192 : 19|1@1+ (1,0) [0|0] "" Vector__XXX
 SG_ APS_sw193_outOfFocusImage m193 : 19|1@1+ (1,0) [0|0] "" Vector__XXX
 SG_ APS_sw195_s8Blocked m195 : 19|1@1+ (1,0) [0|0] "" Vector__XXX
 SG_ APS_sw198_tsrMsgInvalid m198 : 19|1@1+ (1,0) [0|0] "" Vector__XXX
 SG_ APS_sw201_steeringErrorOAL m201 : 19|3@1+ (1,0) [0|0] "" Vector__XXX
 SG_ APS_sw202_s8Blocked m202 : 19|1@1+ (1,0) [0|0] "" Vector__XXX
 SG_ APS_sw230_sensor4Blocked m230 : 19|1@1+ (1,0) [0|0] "" Vector__XXX
 SG_ APS_sw235_pgoodUnrecoverable m235 : 19|1@1+ (1,0) [0|0] "" Vector__XXX
 SG_ APS_sw236_rxFifoInvalid m236 : 19|1@1+ (1,0) [0|0] "" Vector__XXX
 SG_ APS_sw238_junctionTemperature m238 : 19|1@1+ (1,0) [0|0] "" Vector__XXX
 SG_ APS_sw241_phyReinitFailedOnNonResume m241 : 19|1@1+ (1,0) [0|0] "" Vector__XXX
 SG_ APS_sw242_clusterSRAMMBISTFailed m242 : 19|1@1+ (1,0) [0|0] "" Vector__XXX
 SG_ APS_sw246_ethloopSwitchPort3 m246 : 19|1@1+ (1,0) [0|0] "" Vector__XXX
 SG_ APS_sw247_wdogTimeout m247 : 19|1@1+ (1,0) [0|0] "" Vector__XXX
 SG_ APS_sw248_ethloopSwitchPort3Sqi m248 : 19|3@1+ (1,0) [0|0] "" Vector__XXX
 SG_ APS_sw253_socOffReadyTimeout m253 : 19|1@1+ (1,0) [0|0] "" Vector__XXX
 SG_ APS_sw255_i2cInitBootError m255 : 19|1@1+ (1,0) [0|0] "" Vector__XXX
 SG_ APS_sw264_rdlvl_byte_misalignment m264 : 19|1@1+ (1,0) [0|0] "" Vector__XXX
 SG_ APS_sw265_rdlvl_byte_misalignment m265 : 19|1@1+ (1,0) [0|0] "" Vector__XXX
 SG_ APS_sw266_rdlvl_byte_misalignment m266 : 19|1@1+ (1,0) [0|0] "" Vector__XXX
 SG_ APS_sw267_rdlvl_byte_misalignment m267 : 19|1@1+ (1,0) [0|0] "" Vector__XXX
 SG_ APS_sw268_wr_correctable_crc0 m268 : 19|1@1+ (1,0) [0|0] "" Vector__XXX
 SG_ APS_sw271_ddrRdCorrectableErrThreshold m271 : 19|1@1+ (1,0) [0|0] "" Vector__XXX
 SG_ APS_sw272_ddrRdCorrectableErrThreshold m272 : 19|1@1+ (1,0) [0|0] "" Vector__XXX
 SG_ APS_sw273_ddrRdCorrectableErrThreshold m273 : 19|1@1+ (1,0) [0|0] "" Vector__XXX
 SG_ APS_sw274_ddrRdCorrectableErrThreshold m274 : 19|1@1+ (1,0) [0|0] "" Vector__XXX
 SG_ APS_sw275_ddrRdCorrectableErrThreshold m275 : 19|1@1+ (1,0) [0|0] "" Vector__XXX
 SG_ APS_sw276_ddrRdCorrectableErrThreshold m276 : 19|1@1+ (1,0) [0|0] "" Vector__XXX
 SG_ APS_sw277_ddrRdCorrectableErrThreshold m277 : 19|1@1+ (1,0) [0|0] "" Vector__XXX
 SG_ APS_sw278_ddrRdCorrectableErrThreshold m278 : 19|1@1+ (1,0) [0|0] "" Vector__XXX
 SG_ APS_sw291_pingPongBufferError m291 : 19|1@1+ (1,0) [0|0] "" Vector__XXX
 SG_ APS_sw311_dasSmartShift m311 : 19|1@1+ (1,0) [0|0] "" Vector__XXX
 SG_ APS_sw004_radMia m4 : 20|1@1+ (1,0) [0|0] "" Vector__XXX
 SG_ APS_sw005_fullBlockage m5 : 20|1@1+ (1,0) [0|0] "" Vector__XXX
 SG_ APS_sw006_SunRay m6 : 20|1@1+ (1,0) [0|0] "" Vector__XXX
 SG_ APS_sw010_HorizontalMisalignment m10 : 20|16@1+ (0.00137332,-45) [0|0] "" Vector__XXX
 SG_ APS_sw011_scaRight m11 : 20|1@1+ (1,0) [0|0] "" Vector__XXX
 SG_ APS_sw015_LowSun m15 : 20|2@1+ (1,0) [0|0] "" Vector__XXX
 SG_ APS_sw017_Camera_Msg_Common_MIA m17 : 20|1@1+ (1,0) [0|0] "" Vector__XXX
 SG_ APS_sw022_recordId m22 : 20|12@1+ (1,0) [0|0] "" Vector__XXX
 SG_ APS_sw024_numVirtualLaneVeh m24 : 20|4@1+ (1,0) [0|0] "" Vector__XXX
 SG_ APS_sw025_road_class m25 : 20|3@1+ (1,0) [0|0] "" Vector__XXX
 SG_ APS_sw027_PLL_0_Failure m27 : 20|1@1+ (1,0) [0|0] "" Vector__XXX
 SG_ APS_sw028_inv_multifrm_next m28 : 20|1@1+ (1,0) [0|0] "" Vector__XXX
 SG_ APS_sw038_AutofixOutOfCalibYaw m38 : 20|1@1+ (1,0) [0|0] "" Vector__XXX
 SG_ APS_sw047_roadClass m47 : 20|3@1+ (1,0) [0|0] "" Vector__XXX
 SG_ APS_sw048_checkStop m48 : 20|1@1+ (1,0) [0|0] "" Vector__XXX
 SG_ APS_sw051_a52radomeHtrInop m51 : 20|1@1+ (1,0) [0|0] "" Vector__XXX
 SG_ APS_sw052_underTemperature m52 : 20|1@1+ (1,0) [0|0] "" Vector__XXX
 SG_ APS_sw053_a14sccmMIA m53 : 20|1@1+ (1,0) [0|0] "" Vector__XXX
 SG_ APS_sw057_driverAssistControl m57 : 20|1@1+ (1,0) [0|0] "" Vector__XXX
 SG_ APS_sw059_pasFrontMiddle m59 : 20|1@1+ (1,0) [0|0] "" Vector__XXX
 SG_ APS_sw069_parkMismatch m69 : 20|1@1+ (1,0) [0|0] "" Vector__XXX
 SG_ APS_sw071_endPosX m71 : 20|10@1+ (0.05,-25.6) [0|0] "" Vector__XXX
 SG_ APS_sw080_rad_tar_5_check m80 : 20|1@1+ (1,0) [0|0] "" Vector__XXX
 SG_ APS_sw134_dasAutonomyControlParty m134 : 20|1@1+ (1,0) [0|0] "" Vector__XXX
 SG_ APS_sw137_fusionModeDisabled m137 : 20|1@1+ (1,0) [0|0] "" Vector__XXX
 SG_ APS_sw138_mcuNMEAmsgUDPinvalid m138 : 20|1@1+ (1,0) [0|0] "" Vector__XXX
 SG_ APS_sw140_sensors m140 : 20|1@1+ (1,0) [0|0] "" Vector__XXX
 SG_ APS_sw142_chassisControl m142 : 20|1@1+ (1,0) [0|0] "" Vector__XXX
 SG_ APS_sw153_eacInternalState m153 : 20|3@1+ (1,0) [0|0] "" Vector__XXX
 SG_ APS_sw155_UDPCheckError m155 : 20|1@1+ (1,0) [0|0] "" Vector__XXX
 SG_ APS_sw158_dasBodyControlsVEH m158 : 20|1@1+ (1,0) [0|0] "" Vector__XXX
 SG_ APS_sw188_faultsUartMiaState m188 : 20|1@1+ (1,0) [0|0] "" Vector__XXX
 SG_ APS_sw191_smsPeerMissing m191 : 20|1@1+ (1,0) [0|0] "" Vector__XXX
 SG_ APS_sw192_Busoff m192 : 20|1@1+ (1,0) [0|0] "" Vector__XXX
 SG_ APS_sw193_partialBlockage m193 : 20|1@1+ (1,0) [0|0] "" Vector__XXX
 SG_ APS_sw195_s11Blocked m195 : 20|1@1+ (1,0) [0|0] "" Vector__XXX
 SG_ APS_sw200_autopilotRestricted m200 : 20|1@1+ (1,0) [0|0] "" Vector__XXX
 SG_ APS_sw202_s11Blocked m202 : 20|1@1+ (1,0) [0|0] "" Vector__XXX
 SG_ APS_sw203_curbType m203 : 20|2@1+ (1,0) [0|0] "" Vector__XXX
 SG_ APS_sw213_autopilotRestricted m213 : 20|1@1+ (1,0) [0|0] "" Vector__XXX
 SG_ APS_sw219_vehicleSpeed m219 : 20|12@1+ (0.05,-25) [0|0] "" Vector__XXX
 SG_ APS_sw220_vehicleSpeed m220 : 20|12@1+ (0.05,-25) [0|0] "" Vector__XXX
 SG_ APS_sw230_sensor5Blocked m230 : 20|1@1+ (1,0) [0|0] "" Vector__XXX
 SG_ APS_sw235_faultUnrecoverable m235 : 20|1@1+ (1,0) [0|0] "" Vector__XXX
 SG_ APS_sw238_overVoltage m238 : 20|1@1+ (1,0) [0|0] "" Vector__XXX
 SG_ APS_sw241_illTestFailed m241 : 20|1@1+ (1,0) [0|0] "" Vector__XXX
 SG_ APS_sw242_SRAMBankMBISTFailed m242 : 20|1@1+ (1,0) [0|0] "" Vector__XXX
 SG_ APS_sw246_ethloopSwitchPort4 m246 : 20|1@1+ (1,0) [0|0] "" Vector__XXX
 SG_ APS_sw247_overflowError m247 : 20|1@1+ (1,0) [0|0] "" Vector__XXX
 SG_ APS_sw253_apInLinuxTimeout m253 : 20|1@1+ (1,0) [0|0] "" Vector__XXX
 SG_ APS_sw255_provisionInitBootError m255 : 20|1@1+ (1,0) [0|0] "" Vector__XXX
 SG_ APS_sw264_rdlvl_read_gate_offset_filter m264 : 20|1@1+ (1,0) [0|0] "" Vector__XXX
 SG_ APS_sw265_rdlvl_read_gate_offset_filter m265 : 20|1@1+ (1,0) [0|0] "" Vector__XXX
 SG_ APS_sw266_rdlvl_read_gate_offset_filter m266 : 20|1@1+ (1,0) [0|0] "" Vector__XXX
 SG_ APS_sw267_rdlvl_read_gate_offset_filter m267 : 20|1@1+ (1,0) [0|0] "" Vector__XXX
 SG_ APS_sw268_vendorIdMismatchMIF0 m268 : 20|1@1+ (1,0) [0|0] "" Vector__XXX
 SG_ APS_sw271_bufferRdCorrectableErrThreshold m271 : 20|1@1+ (1,0) [0|0] "" Vector__XXX
 SG_ APS_sw272_bufferRdCorrectableErrThreshold m272 : 20|1@1+ (1,0) [0|0] "" Vector__XXX
 SG_ APS_sw273_bufferRdCorrectableErrThreshold m273 : 20|1@1+ (1,0) [0|0] "" Vector__XXX
 SG_ APS_sw274_bufferRdCorrectableErrThreshold m274 : 20|1@1+ (1,0) [0|0] "" Vector__XXX
 SG_ APS_sw275_bufferRdCorrectableErrThreshold m275 : 20|1@1+ (1,0) [0|0] "" Vector__XXX
 SG_ APS_sw276_bufferRdCorrectableErrThreshold m276 : 20|1@1+ (1,0) [0|0] "" Vector__XXX
 SG_ APS_sw277_bufferRdCorrectableErrThreshold m277 : 20|1@1+ (1,0) [0|0] "" Vector__XXX
 SG_ APS_sw278_bufferRdCorrectableErrThreshold m278 : 20|1@1+ (1,0) [0|0] "" Vector__XXX
 SG_ APS_sw301_nocIrqId m301 : 20|9@1+ (1,0) [0|0] "" Vector__XXX
 SG_ APS_sw311_dasStatus m311 : 20|1@1+ (1,0) [0|0] "" Vector__XXX
 SG_ APS_sw004_radDynamicsError m4 : 21|1@1+ (1,0) [0|0] "" Vector__XXX
 SG_ APS_sw005_camObjHeader m5 : 21|1@1+ (1,0) [0|0] "" Vector__XXX
 SG_ APS_sw006_Splashes m6 : 21|1@1+ (1,0) [0|0] "" Vector__XXX
 SG_ APS_sw011_scaBlinker m11 : 21|2@1+ (1,0) [0|0] "" Vector__XXX
 SG_ APS_sw013_numEyeqResets m13 : 21|3@1+ (1,0) [0|0] "" Vector__XXX
 SG_ APS_sw017_Camera_Msg_FCW_PCW_MIA m17 : 21|1@1+ (1,0) [0|0] "" Vector__XXX
 SG_ APS_sw027_Clock_Monitor_0_Low m27 : 21|1@1+ (1,0) [0|0] "" Vector__XXX
 SG_ APS_sw028_unusedBits m28 : 21|11@1+ (1,0) [0|0] "" Vector__XXX
 SG_ APS_sw038_FullBlockage m38 : 21|1@1+ (1,0) [0|0] "" Vector__XXX
 SG_ APS_sw048_ecuWatchdog m48 : 21|1@1+ (1,0) [0|0] "" Vector__XXX
 SG_ APS_sw051_unused m51 : 21|3@1+ (1,0) [0|0] "" Vector__XXX
 SG_ APS_sw052_chirpError m52 : 21|1@1+ (1,0) [0|0] "" Vector__XXX
 SG_ APS_sw053_a15adasMIA m53 : 21|1@1+ (1,0) [0|0] "" Vector__XXX
 SG_ APS_sw057_telemetryControl m57 : 21|1@1+ (1,0) [0|0] "" Vector__XXX
 SG_ APS_sw059_sensorStatusRear m59 : 21|1@1+ (1,0) [0|0] "" Vector__XXX
 SG_ APS_sw069_eacStatus m69 : 21|4@1+ (1,0) [0|0] "" Vector__XXX
 SG_ APS_sw073_rawMobileyeLDW m73 : 21|2@1+ (1,0) [0|0] "" Vector__XXX
 SG_ APS_sw080_ultrasonic_obs_check m80 : 21|1@1+ (1,0) [0|0] "" Vector__XXX
 SG_ APS_sw134_dasAutonomyControlVeh m134 : 21|1@1+ (1,0) [0|0] "" Vector__XXX
 SG_ APS_sw137_gpsCfgFail m137 : 21|1@1+ (1,0) [0|0] "" Vector__XXX
 SG_ APS_sw138_mcuDbgMsgInvalid m138 : 21|1@1+ (1,0) [0|0] "" Vector__XXX
 SG_ APS_sw140_coolant m140 : 21|1@1+ (1,0) [0|0] "" Vector__XXX
 SG_ APS_sw151_diGear m151 : 21|3@1+ (1,0) [0|0] "" Vector__XXX
 SG_ APS_sw155_UDPDropError m155 : 21|1@1+ (1,0) [0|0] "" Vector__XXX
 SG_ APS_sw158_dasControl m158 : 21|1@1+ (1,0) [0|0] "" Vector__XXX
 SG_ APS_sw188_sleepUartMiaState m188 : 21|1@1+ (1,0) [0|0] "" Vector__XXX
 SG_ APS_sw192_UncorrectedBitError m192 : 21|1@1+ (1,0) [0|0] "" Vector__XXX
 SG_ APS_sw193_smearedHalos m193 : 21|1@1+ (1,0) [0|0] "" Vector__XXX
 SG_ APS_sw195_s12Blocked m195 : 21|1@1+ (1,0) [0|0] "" Vector__XXX
 SG_ APS_sw200_endSpeed m200 : 21|10@1+ (0.1,-10) [0|0] "" Vector__XXX
 SG_ APS_sw202_s12Blocked m202 : 21|1@1+ (1,0) [0|0] "" Vector__XXX
 SG_ APS_sw213_endSpeed m213 : 21|10@1+ (0.1,-10) [0|0] "" Vector__XXX
 SG_ APS_sw230_sensor6Blocked m230 : 21|1@1+ (1,0) [0|0] "" Vector__XXX
 SG_ APS_sw235_12VFuseUnrecoverable m235 : 21|1@1+ (1,0) [0|0] "" Vector__XXX
 SG_ APS_sw238_underVoltage m238 : 21|1@1+ (1,0) [0|0] "" Vector__XXX
 SG_ APS_sw241_memTestFailed m241 : 21|1@1+ (1,0) [0|0] "" Vector__XXX
 SG_ APS_sw246_ethloopSwitchPort5 m246 : 21|1@1+ (1,0) [0|0] "" Vector__XXX
 SG_ APS_sw247_giantPacket m247 : 21|1@1+ (1,0) [0|0] "" Vector__XXX
 SG_ APS_sw253_apInCorebootTimeout m253 : 21|1@1+ (1,0) [0|0] "" Vector__XXX
 SG_ APS_sw255_rtcInitBootError m255 : 21|1@1+ (1,0) [0|0] "" Vector__XXX
 SG_ APS_sw264_rdlvl_vref_convergence m264 : 21|1@1+ (1,0) [0|0] "" Vector__XXX
 SG_ APS_sw265_rdlvl_vref_convergence m265 : 21|1@1+ (1,0) [0|0] "" Vector__XXX
 SG_ APS_sw266_rdlvl_vref_convergence m266 : 21|1@1+ (1,0) [0|0] "" Vector__XXX
 SG_ APS_sw267_rdlvl_vref_convergence m267 : 21|1@1+ (1,0) [0|0] "" Vector__XXX
 SG_ APS_sw268_rd_uncorrectable_crc1 m268 : 21|1@1+ (1,0) [0|0] "" Vector__XXX
 SG_ APS_sw271_csrParity m271 : 21|1@1+ (1,0) [0|0] "" Vector__XXX
 SG_ APS_sw272_csrParity m272 : 21|1@1+ (1,0) [0|0] "" Vector__XXX
 SG_ APS_sw273_csrParity m273 : 21|1@1+ (1,0) [0|0] "" Vector__XXX
 SG_ APS_sw274_csrParity m274 : 21|1@1+ (1,0) [0|0] "" Vector__XXX
 SG_ APS_sw275_csrParity m275 : 21|1@1+ (1,0) [0|0] "" Vector__XXX
 SG_ APS_sw276_csrParity m276 : 21|1@1+ (1,0) [0|0] "" Vector__XXX
 SG_ APS_sw277_csrParity m277 : 21|1@1+ (1,0) [0|0] "" Vector__XXX
 SG_ APS_sw278_csrParity m278 : 21|1@1+ (1,0) [0|0] "" Vector__XXX
 SG_ APS_sw297_wdogMonTaskID m297 : 21|5@1+ (1,0) [0|0] "" Vector__XXX
 SG_ APS_sw304_addrType m304 : 21|1@1+ (1,0) [0|0] "" Vector__XXX
 SG_ APS_sw311_dasSteeringControl m311 : 21|1@1+ (1,0) [0|0] "" Vector__XXX
 SG_ APS_sw004_espMIA m4 : 22|1@1+ (1,0) [0|0] "" Vector__XXX
 SG_ APS_sw005_camCommonMsg m5 : 22|1@1+ (1,0) [0|0] "" Vector__XXX
 SG_ APS_sw006_BlurredImage m6 : 22|1@1+ (1,0) [0|0] "" Vector__XXX
 SG_ APS_sw015_BlurredImage m15 : 22|2@1+ (1,0) [0|0] "" Vector__XXX
 SG_ APS_sw017_Camera_Msg_TFL_MIA m17 : 22|1@1+ (1,0) [0|0] "" Vector__XXX
 SG_ APS_sw027_Clock_Monitor_0_Off m27 : 22|1@1+ (1,0) [0|0] "" Vector__XXX
 SG_ APS_sw038_TooManyResets m38 : 22|1@1+ (1,0) [0|0] "" Vector__XXX
 SG_ APS_sw048_ecuReset m48 : 22|1@1+ (1,0) [0|0] "" Vector__XXX
 SG_ APS_sw052_rspError m52 : 22|1@1+ (1,0) [0|0] "" Vector__XXX
 SG_ APS_sw053_a16bdyInvalidCount m53 : 22|1@1+ (1,0) [0|0] "" Vector__XXX
 SG_ APS_sw057_chassisControl m57 : 22|1@1+ (1,0) [0|0] "" Vector__XXX
 SG_ APS_sw059_pasRearMiddle m59 : 22|1@1+ (1,0) [0|0] "" Vector__XXX
 SG_ APS_sw080_freespace_check m80 : 22|1@1+ (1,0) [0|0] "" Vector__XXX
 SG_ APS_sw134_dasBodyControlsVEH m134 : 22|1@1+ (1,0) [0|0] "" Vector__XXX
 SG_ APS_sw137_esfStatusMsgMIA m137 : 22|1@1+ (1,0) [0|0] "" Vector__XXX
 SG_ APS_sw138_mcuDbgMsgTooBig m138 : 22|1@1+ (1,0) [0|0] "" Vector__XXX
 SG_ APS_sw140_okToUseHighPower m140 : 22|1@1+ (1,0) [0|0] "" Vector__XXX
 SG_ APS_sw155_UDPMemError m155 : 22|1@1+ (1,0) [0|0] "" Vector__XXX
 SG_ APS_sw158_dasControlPty m158 : 22|1@1+ (1,0) [0|0] "" Vector__XXX
 SG_ APS_sw188_resetUartMiaState m188 : 22|1@1+ (1,0) [0|0] "" Vector__XXX
 SG_ APS_sw192_CorrectedBitError m192 : 22|1@1+ (1,0) [0|0] "" Vector__XXX
 SG_ APS_sw193_smearedSpots m193 : 22|1@1+ (1,0) [0|0] "" Vector__XXX
 SG_ APS_sw194_leadDx m194 : 22|8@1+ (0.1,0) [0|0] "" Vector__XXX
 SG_ APS_sw199_abortCodePARK m199 : 22|5@1+ (1,0) [0|0] "" Vector__XXX
 SG_ APS_sw203_roadClass m203 : 22|3@1+ (1,0) [0|0] "" Vector__XXX
 SG_ APS_sw230_sensor7Blocked m230 : 22|1@1+ (1,0) [0|0] "" Vector__XXX
 SG_ APS_sw235_pgoodLevelUnrcvrble m235 : 22|1@1+ (1,0) [0|0] "" Vector__XXX
 SG_ APS_sw238_resetInput m238 : 22|1@1+ (1,0) [0|0] "" Vector__XXX
 SG_ APS_sw241_dfiInitCompleteTimeout m241 : 22|1@1+ (1,0) [0|0] "" Vector__XXX
 SG_ APS_sw246_ethloopSwitchPort6 m246 : 22|1@1+ (1,0) [0|0] "" Vector__XXX
 SG_ APS_sw247_destAddrFilterFail m247 : 22|1@1+ (1,0) [0|0] "" Vector__XXX
 SG_ APS_sw253_apBootingTimeout m253 : 22|1@1+ (1,0) [0|0] "" Vector__XXX
 SG_ APS_sw255_vrmInitConfigBootError m255 : 22|1@1+ (1,0) [0|0] "" Vector__XXX
 SG_ APS_sw264_rdlvl_cdr_convergence m264 : 22|1@1+ (1,0) [0|0] "" Vector__XXX
 SG_ APS_sw265_rdlvl_cdr_convergence m265 : 22|1@1+ (1,0) [0|0] "" Vector__XXX
 SG_ APS_sw266_rdlvl_cdr_convergence m266 : 22|1@1+ (1,0) [0|0] "" Vector__XXX
 SG_ APS_sw267_rdlvl_cdr_convergence m267 : 22|1@1+ (1,0) [0|0] "" Vector__XXX
 SG_ APS_sw268_rd_correctable_crc1 m268 : 22|1@1+ (1,0) [0|0] "" Vector__XXX
 SG_ APS_sw271_fifoParity0 m271 : 22|1@1+ (1,0) [0|0] "" Vector__XXX
 SG_ APS_sw272_fifoParity0 m272 : 22|1@1+ (1,0) [0|0] "" Vector__XXX
 SG_ APS_sw273_fifoParity0 m273 : 22|1@1+ (1,0) [0|0] "" Vector__XXX
 SG_ APS_sw274_fifoParity0 m274 : 22|1@1+ (1,0) [0|0] "" Vector__XXX
 SG_ APS_sw275_fifoParity0 m275 : 22|1@1+ (1,0) [0|0] "" Vector__XXX
 SG_ APS_sw276_fifoParity0 m276 : 22|1@1+ (1,0) [0|0] "" Vector__XXX
 SG_ APS_sw277_fifoParity0 m277 : 22|1@1+ (1,0) [0|0] "" Vector__XXX
 SG_ APS_sw278_fifoParity0 m278 : 22|1@1+ (1,0) [0|0] "" Vector__XXX
 SG_ APS_sw311_dasRedundantBrakingControl m311 : 22|1@1+ (1,0) [0|0] "" Vector__XXX
 SG_ APS_sw005_camFcwPcwMsg m5 : 23|1@1+ (1,0) [0|0] "" Vector__XXX
 SG_ APS_sw006_LowSun m6 : 23|1@1+ (1,0) [0|0] "" Vector__XXX
 SG_ APS_sw011_scaThreshold m11 : 23|1@1+ (1,0) [0|0] "" Vector__XXX
 SG_ APS_sw017_Any_Lanes_Msg_Recd m17 : 23|1@1+ (1,0) [0|0] "" Vector__XXX
 SG_ APS_sw025_road_match m25 : 23|1@1+ (1,0) [0|0] "" Vector__XXX
 SG_ APS_sw027_LVD_4v5 m27 : 23|1@1+ (1,0) [0|0] "" Vector__XXX
 SG_ APS_sw047_controlledAccess m47 : 23|1@1+ (1,0) [0|0] "" Vector__XXX
 SG_ APS_sw048_radcVersionMismatch m48 : 23|1@1+ (1,0) [0|0] "" Vector__XXX
 SG_ APS_sw052_sensorBlocked m52 : 23|1@1+ (1,0) [0|0] "" Vector__XXX
 SG_ APS_sw053_a17adasInvalidCount m53 : 23|1@1+ (1,0) [0|0] "" Vector__XXX
 SG_ APS_sw057_solarData m57 : 23|1@1+ (1,0) [0|0] "" Vector__XXX
 SG_ APS_sw059_pscStatus m59 : 23|1@1+ (1,0) [0|0] "" Vector__XXX
 SG_ APS_sw080_pedestrian_check m80 : 23|1@1+ (1,0) [0|0] "" Vector__XXX
 SG_ APS_sw134_dasControl m134 : 23|1@1+ (1,0) [0|0] "" Vector__XXX
 SG_ APS_sw137_wheelTickCfgMissmatch m137 : 23|1@1+ (1,0) [0|0] "" Vector__XXX
 SG_ APS_sw138_mcuFwdNMEAfail m138 : 23|1@1+ (1,0) [0|0] "" Vector__XXX
 SG_ APS_sw155_UDPProtoError m155 : 23|1@1+ (1,0) [0|0] "" Vector__XXX
 SG_ APS_sw158_dasIntSafetyFrontPty m158 : 23|1@1+ (1,0) [0|0] "" Vector__XXX
 SG_ APS_sw188_statMonUartMiaState m188 : 23|1@1+ (1,0) [0|0] "" Vector__XXX
 SG_ APS_sw192_ErrorPassive m192 : 23|1@1+ (1,0) [0|0] "" Vector__XXX
 SG_ APS_sw230_sensor8Blocked m230 : 23|1@1+ (1,0) [0|0] "" Vector__XXX
 SG_ APS_sw235_faultLevelUnrcvrble m235 : 23|1@1+ (1,0) [0|0] "" Vector__XXX
 SG_ APS_sw237_peerSoCFaulted m237 : 23|1@1+ (1,0) [0|0] "" Vector__XXX
 SG_ APS_sw241_phy0TimeoutWaitingForInterrupts m241 : 23|1@1+ (1,0) [0|0] "" Vector__XXX
 SG_ APS_sw246_ethloopSwitchPort7 m246 : 23|1@1+ (1,0) [0|0] "" Vector__XXX
 SG_ APS_sw247_saAddressFilterFail m247 : 23|1@1+ (1,0) [0|0] "" Vector__XXX
 SG_ APS_sw253_apOnTimeout m253 : 23|1@1+ (1,0) [0|0] "" Vector__XXX
 SG_ APS_sw255_powerAonIoBootError m255 : 23|1@1+ (1,0) [0|0] "" Vector__XXX
 SG_ APS_sw264_rdlvl_dfe_convergence m264 : 23|1@1+ (1,0) [0|0] "" Vector__XXX
 SG_ APS_sw265_rdlvl_dfe_convergence m265 : 23|1@1+ (1,0) [0|0] "" Vector__XXX
 SG_ APS_sw266_rdlvl_dfe_convergence m266 : 23|1@1+ (1,0) [0|0] "" Vector__XXX
 SG_ APS_sw267_rdlvl_dfe_convergence m267 : 23|1@1+ (1,0) [0|0] "" Vector__XXX
 SG_ APS_sw268_wr_uncorrectable_crc1 m268 : 23|1@1+ (1,0) [0|0] "" Vector__XXX
 SG_ APS_sw271_fifoParity1 m271 : 23|1@1+ (1,0) [0|0] "" Vector__XXX
 SG_ APS_sw272_fifoParity1 m272 : 23|1@1+ (1,0) [0|0] "" Vector__XXX
 SG_ APS_sw273_fifoParity1 m273 : 23|1@1+ (1,0) [0|0] "" Vector__XXX
 SG_ APS_sw274_fifoParity1 m274 : 23|1@1+ (1,0) [0|0] "" Vector__XXX
 SG_ APS_sw275_fifoParity1 m275 : 23|1@1+ (1,0) [0|0] "" Vector__XXX
 SG_ APS_sw276_fifoParity1 m276 : 23|1@1+ (1,0) [0|0] "" Vector__XXX
 SG_ APS_sw277_fifoParity1 m277 : 23|1@1+ (1,0) [0|0] "" Vector__XXX
 SG_ APS_sw278_fifoParity1 m278 : 23|1@1+ (1,0) [0|0] "" Vector__XXX
 SG_ APS_sw004_accState m4 : 24|4@1+ (1,0) [0|0] "" Vector__XXX
 SG_ APS_sw005_radHWFailure m5 : 24|1@1+ (1,0) [0|0] "" Vector__XXX
 SG_ APS_sw006_SmearedSpots m6 : 24|1@1+ (1,0) [0|0] "" Vector__XXX
 SG_ APS_sw011_scaSpeed m11 : 24|7@1+ (1,0) [0|0] "" Vector__XXX
 SG_ APS_sw013_numCrcErrors m13 : 24|8@1+ (1,0) [0|0] "" Vector__XXX
 SG_ APS_sw015_FullBlockage m15 : 24|2@1+ (1,0) [0|0] "" Vector__XXX
 SG_ APS_sw017_Any_Objects_Msg_Recd m17 : 24|1@1+ (1,0) [0|0] "" Vector__XXX
 SG_ APS_sw019_numFreeBytes m19 : 24|8@1+ (1,-191) [0|0] "" Vector__XXX
 SG_ APS_sw021_minThreshold m21 : 24|8@1- (1,0) [0|0] "" Vector__XXX
 SG_ APS_sw024_currentVehicleApp m24 : 24|8@1+ (1,0) [0|0] "" Vector__XXX
 SG_ APS_sw025_controlled_access m25 : 24|1@1+ (1,0) [0|0] "" Vector__XXX
 SG_ APS_sw027_Flash_Fatal_Error m27 : 24|1@1+ (1,0) [0|0] "" Vector__XXX
 SG_ APS_sw030_unusedByte m30 : 24|8@1+ (1,0) [0|0] "" Vector__XXX
 SG_ APS_sw031_errorType m31 : 24|8@1+ (1,0) [0|0] "" Vector__XXX
 SG_ APS_sw032_errorType m32 : 24|8@1+ (1,0) [0|0] "" Vector__XXX
 SG_ APS_sw034_unusedByte m34 : 24|8@1+ (1,0) [0|0] "" Vector__XXX
 SG_ APS_sw036_unusedByte m36 : 24|8@1+ (1,0) [0|0] "" Vector__XXX
 SG_ APS_sw037_issue m37 : 24|8@1+ (1,0) [0|0] "" Vector__XXX
 SG_ APS_sw039_unusedByte m39 : 24|8@1+ (1,0) [0|0] "" Vector__XXX
 SG_ APS_sw040_ego_veh_speed m40 : 24|8@1+ (0.2,0) [0|0] "" Vector__XXX
 SG_ APS_sw042_view_range m42 : 24|8@1+ (1,0) [0|0] "" Vector__XXX
 SG_ APS_sw044_appStatus m44 : 24|4@1+ (1,0) [0|0] "" Vector__XXX
 SG_ APS_sw045_unusedByte m45 : 24|8@1+ (1,0) [0|0] "" Vector__XXX
 SG_ APS_sw047_edrType m47 : 24|6@1+ (1,0) [0|0] "" Vector__XXX
 SG_ APS_sw048_radcCalibration m48 : 24|1@1+ (1,0) [0|0] "" Vector__XXX
 SG_ APS_sw051_SCUTemperature m51 : 24|8@1- (1,0) [0|0] "" Vector__XXX
 SG_ APS_sw053_a18espInvalidCount m53 : 24|1@1+ (1,0) [0|0] "" Vector__XXX
 SG_ APS_sw054_Autofix_horizon m54 : 24|8@1+ (1,0) [0|0] "" Vector__XXX
 SG_ APS_sw056_unusedByte m56 : 24|8@1+ (1,0) [0|0] "" Vector__XXX
 SG_ APS_sw057_vehicleModes m57 : 24|1@1+ (1,0) [0|0] "" Vector__XXX
 SG_ APS_sw058_unusedByte m58 : 24|8@1+ (1,0) [0|0] "" Vector__XXX
 SG_ APS_sw059_pscVehSlot m59 : 24|1@1+ (1,0) [0|0] "" Vector__XXX
 SG_ APS_sw063_detectedMajorVer m63 : 24|8@1+ (1,0) [0|0] "" Vector__XXX
 SG_ APS_sw065_mobileye_main_state m65 : 24|8@1+ (1,0) [0|0] "" Vector__XXX
 SG_ APS_sw066_mobileye_main_state m66 : 24|8@1+ (1,0) [0|0] "" Vector__XXX
 SG_ APS_sw070_diGear m70 : 24|3@1+ (1,0) [0|0] "" Vector__XXX
 SG_ APS_sw073_freespaceLDW m73 : 24|2@1+ (1,0) [0|0] "" Vector__XXX
 SG_ APS_sw074_ipsoDy m74 : 24|6@1+ (0.1,-3.2) [0|0] "" Vector__XXX
 SG_ APS_sw075_unusedByte m75 : 24|8@1+ (1,0) [0|0] "" Vector__XXX
 SG_ APS_sw078_ttc m78 : 24|8@1+ (0.02,0) [0|0] "" Vector__XXX
 SG_ APS_sw080_rad_tar_5_dist m80 : 24|6@1+ (1,0) [0|0] "" Vector__XXX
 SG_ APS_sw081_radarTTC m81 : 24|8@1+ (0.02,0) [0|0] "" Vector__XXX
 SG_ APS_sw082_R_VL m82 : 24|8@1+ (0.05,-6.4) [0|0] "" Vector__XXX
 SG_ APS_sw084_ipsoRCS m84 : 24|8@1+ (1,0) [0|0] "" Vector__XXX
 SG_ APS_sw085_radarTTC m85 : 24|8@1+ (0.02,0) [0|0] "" Vector__XXX
 SG_ APS_sw086_distanceEllipse m86 : 24|8@1+ (0.5,0) [0|0] "" Vector__XXX
 SG_ APS_sw103_objectRCS m103 : 24|8@1+ (1,0) [0|0] "" Vector__XXX
 SG_ APS_sw130_maxThreshold m130 : 24|8@1- (1,0) [0|0] "" Vector__XXX
 SG_ APS_sw132_actualHash m132 : 24|24@1+ (1,0) [0|0] "" Vector__XXX
 SG_ APS_sw133_switchInReset m133 : 24|1@1+ (1,0) [0|0] "" Vector__XXX
 SG_ APS_sw134_dasControlPty m134 : 24|1@1+ (1,0) [0|0] "" Vector__XXX
 SG_ APS_sw135_appTimesyncStatus m135 : 24|32@1+ (1,0) [0|0] "" Vector__XXX
 SG_ APS_sw137_exitTransportMode m137 : 24|1@1+ (1,0) [0|0] "" Vector__XXX
 SG_ APS_sw138_NMEAinvalidChecksum m138 : 24|1@1+ (1,0) [0|0] "" Vector__XXX
 SG_ APS_sw139_numMessagesDropped m139 : 24|8@1+ (1,0) [0|0] "" Vector__XXX
 SG_ APS_sw151_recoveryPathway m151 : 24|2@1+ (1,0) [0|0] "" Vector__XXX
 SG_ APS_sw155_IPRecvError m155 : 24|1@1+ (1,0) [0|0] "" Vector__XXX
 SG_ APS_sw158_dasLanes m158 : 24|1@1+ (1,0) [0|0] "" Vector__XXX
 SG_ APS_sw159_apbTimesyncStatus m159 : 24|32@1+ (1,0) [0|0] "" Vector__XXX
 SG_ APS_sw160_actualHash m160 : 24|24@1+ (1,0) [0|0] "" Vector__XXX
 SG_ APS_sw171_taskUtilizationPercent m171 : 24|8@1+ (1,0) [0|0] "" Vector__XXX
 SG_ APS_sw187_taskUtilizationPercent m187 : 24|8@1+ (1,0) [0|0] "" Vector__XXX
 SG_ APS_sw188_wdogStateUartMiaState m188 : 24|1@1+ (1,0) [0|0] "" Vector__XXX
 SG_ APS_sw192_RamAccessFailed m192 : 24|1@1+ (1,0) [0|0] "" Vector__XXX
 SG_ APS_sw195_sdiFrontCC m195 : 24|5@1+ (1,0) [0|0] "" Vector__XXX
 SG_ APS_sw201_stwAngleReq m201 : 24|8@1- (1,0) [0|0] "" Vector__XXX
 SG_ APS_sw202_sdiFrontCC m202 : 24|5@1+ (1,0) [0|0] "" Vector__XXX
 SG_ APS_sw204_frLeftMiddle m204 : 24|8@1+ (1,0) [0|0] "" Vector__XXX
 SG_ APS_sw205_rrLeft m205 : 24|8@1+ (1,0) [0|0] "" Vector__XXX
 SG_ APS_sw207_eyeq3MainState m207 : 24|8@1+ (1,0) [0|0] "" Vector__XXX
 SG_ APS_sw218_drivingOnHighway m218 : 24|1@1+ (1,0) [0|0] "" Vector__XXX
 SG_ APS_sw230_sensor9Blocked m230 : 24|1@1+ (1,0) [0|0] "" Vector__XXX
 SG_ APS_sw235_12VFuseLvlUnrcvrble m235 : 24|1@1+ (1,0) [0|0] "" Vector__XXX
 SG_ APS_sw236_fifoCurSize m236 : 24|7@1+ (1,0) [0|0] "" Vector__XXX
 SG_ APS_sw238_swResetReason m238 : 24|5@1+ (1,0) [0|0] "" Vector__XXX
 SG_ APS_sw241_phy0Ch0ReadGateOffsetBug m241 : 24|1@1+ (1,0) [0|0] "" Vector__XXX
 SG_ APS_sw243_errorStatus m243 : 24|8@1+ (1,0) [0|0] "" Vector__XXX
 SG_ APS_sw244_exceptionCode m244 : 24|8@1+ (1,0) [0|0] "" Vector__XXX
 SG_ APS_sw245_unknownMACAddrByte1 m245 : 24|8@1+ (1,0) [0|0] "" Vector__XXX
 SG_ APS_sw255_bl1TocInitBootError m255 : 24|1@1+ (1,0) [0|0] "" Vector__XXX
 SG_ APS_sw260_pgoodPmicFaultSd0 m260 : 24|1@1+ (1,0) [0|0] "" Vector__XXX
 SG_ APS_sw264_wdqlvl_phase_margin_error m264 : 24|1@1+ (1,0) [0|0] "" Vector__XXX
 SG_ APS_sw265_rdlvl_reinit_tier1 m265 : 24|1@1+ (1,0) [0|0] "" Vector__XXX
 SG_ APS_sw266_rdlvl_reinit_tier1 m266 : 24|1@1+ (1,0) [0|0] "" Vector__XXX
 SG_ APS_sw267_rdlvl_reinit_tier1 m267 : 24|1@1+ (1,0) [0|0] "" Vector__XXX
 SG_ APS_sw268_wr_correctable_crc1 m268 : 24|1@1+ (1,0) [0|0] "" Vector__XXX
 SG_ APS_sw271_bufferUE m271 : 24|1@1+ (1,0) [0|0] "" Vector__XXX
 SG_ APS_sw272_bufferUE m272 : 24|1@1+ (1,0) [0|0] "" Vector__XXX
 SG_ APS_sw273_bufferUE m273 : 24|1@1+ (1,0) [0|0] "" Vector__XXX
 SG_ APS_sw274_bufferUE m274 : 24|1@1+ (1,0) [0|0] "" Vector__XXX
 SG_ APS_sw275_bufferUE m275 : 24|1@1+ (1,0) [0|0] "" Vector__XXX
 SG_ APS_sw276_bufferUE m276 : 24|1@1+ (1,0) [0|0] "" Vector__XXX
 SG_ APS_sw277_bufferUE m277 : 24|1@1+ (1,0) [0|0] "" Vector__XXX
 SG_ APS_sw278_bufferUE m278 : 24|1@1+ (1,0) [0|0] "" Vector__XXX
 SG_ APS_sw279_errorCode m279 : 24|8@1+ (1,0) [0|0] "" Vector__XXX
 SG_ APS_sw289_turboProbe m289 : 24|6@1+ (1,0) [0|0] "" Vector__XXX
 SG_ APS_sw292_passiveErrorCount m292 : 24|8@1+ (1,0) [0|0] "" Vector__XXX
 SG_ APS_sw293_passiveErrorCount m293 : 24|8@1+ (1,0) [0|0] "" Vector__XXX
 SG_ APS_sw294_passiveErrorCount m294 : 24|8@1+ (1,0) [0|0] "" Vector__XXX
 SG_ APS_sw295_passiveErrorCount m295 : 24|8@1+ (1,0) [0|0] "" Vector__XXX
 SG_ APS_sw296_wdogMonTaskCurrCheckinCount m296 : 24|7@1+ (1,0) [0|0] "" Vector__XXX
 SG_ APS_sw298_cpuToApInvalidAddressCount m298 : 24|8@1+ (1,0) [0|0] "" Vector__XXX
 SG_ APS_sw299_apToCpuInvalidAddressCount m299 : 24|8@1+ (1,0) [0|0] "" Vector__XXX
 SG_ APS_sw304_faultingAddr m304 : 24|32@1+ (1,0) [0|0] "" Vector__XXX
 SG_ APS_sw307_dedEvent m307 : 24|8@1+ (1,0) [0|0] "" Vector__XXX
 SG_ APS_sw313_passiveErrorCount m313 : 24|8@1+ (1,0) [0|0] "" Vector__XXX
 SG_ APS_sw005_radSensorBlind m5 : 25|1@1+ (1,0) [0|0] "" Vector__XXX
 SG_ APS_sw006_PartialBlockage m6 : 25|1@1+ (1,0) [0|0] "" Vector__XXX
 SG_ APS_sw016_targetRelSpeed m16 : 25|9@1+ (0.0625,-31) [0|0] "" Vector__XXX
 SG_ APS_sw017_Any_TFL_Msg_Recd m17 : 25|1@1+ (1,0) [0|0] "" Vector__XXX
 SG_ APS_sw025_leftLaneUsage m25 : 25|2@1+ (1,0) [0|0] "" Vector__XXX
 SG_ APS_sw027_PLL_1_Failure m27 : 25|1@1+ (1,0) [0|0] "" Vector__XXX
 SG_ APS_sw048_radcMia m48 : 25|1@1+ (1,0) [0|0] "" Vector__XXX
 SG_ APS_sw050_targetRelSpeed m50 : 25|9@1+ (0.0625,-31) [0|0] "" Vector__XXX
 SG_ APS_sw053_a19sccmInvalidCount m53 : 25|1@1+ (1,0) [0|0] "" Vector__XXX
 SG_ APS_sw057_cruiseControl m57 : 25|1@1+ (1,0) [0|0] "" Vector__XXX
 SG_ APS_sw059_status2 m59 : 25|1@1+ (1,0) [0|0] "" Vector__XXX
 SG_ APS_sw060_targetRelSpeed m60 : 25|9@1+ (0.0625,-31) [0|0] "" Vector__XXX
 SG_ APS_sw069_diAPState m69 : 25|4@1+ (1,0) [0|0] "" Vector__XXX
 SG_ APS_sw076_targetRelSpeed m76 : 25|9@1+ (0.0625,-31) [0|0] "" Vector__XXX
 SG_ APS_sw077_oocConfidence m77 : 25|7@1+ (1,0) [0|0] "" Vector__XXX
 SG_ APS_sw133_phyIsNotRMIIMode m133 : 25|1@1+ (1,0) [0|0] "" Vector__XXX
 SG_ APS_sw134_dasIntSafetyFrontPty m134 : 25|1@1+ (1,0) [0|0] "" Vector__XXX
 SG_ APS_sw137_satRejectionTimeout m137 : 25|1@1+ (1,0) [0|0] "" Vector__XXX
 SG_ APS_sw138_unexpectedNMEAmsg m138 : 25|1@1+ (1,0) [0|0] "" Vector__XXX
 SG_ APS_sw155_IPMiscError m155 : 25|1@1+ (1,0) [0|0] "" Vector__XXX
 SG_ APS_sw158_dasObject m158 : 25|1@1+ (1,0) [0|0] "" Vector__XXX
 SG_ APS_sw188_critReasUartMiaState m188 : 25|1@1+ (1,0) [0|0] "" Vector__XXX
 SG_ APS_sw192_RxMsgLost m192 : 25|1@1+ (1,0) [0|0] "" Vector__XXX
 SG_ APS_sw203_slotSizeX m203 : 25|8@1+ (4,0) [0|0] "" Vector__XXX
 SG_ APS_sw218_handsOnState m218 : 25|4@1+ (1,0) [0|0] "" Vector__XXX
 SG_ APS_sw230_sensor10Blocked m230 : 25|1@1+ (1,0) [0|0] "" Vector__XXX
 SG_ APS_sw231_predImpactVelocity m231 : 25|7@1+ (0.5,0) [0|0] "" Vector__XXX
 SG_ APS_sw235_localSoftwareFault m235 : 25|1@1+ (1,0) [0|0] "" Vector__XXX
 SG_ APS_sw241_phy0Ch1ReadGateOffsetBug m241 : 25|1@1+ (1,0) [0|0] "" Vector__XXX
 SG_ APS_sw255_tmuInitBootError m255 : 25|1@1+ (1,0) [0|0] "" Vector__XXX
 SG_ APS_sw260_pgoodPmicFaultSd1 m260 : 25|1@1+ (1,0) [0|0] "" Vector__XXX
 SG_ APS_sw264_rdlvl_reinit_tier1 m264 : 25|1@1+ (1,0) [0|0] "" Vector__XXX
 SG_ APS_sw265_rdlvl_reinit_tier2 m265 : 25|1@1+ (1,0) [0|0] "" Vector__XXX
 SG_ APS_sw266_rdlvl_reinit_tier2 m266 : 25|1@1+ (1,0) [0|0] "" Vector__XXX
 SG_ APS_sw267_rdlvl_reinit_tier2 m267 : 25|1@1+ (1,0) [0|0] "" Vector__XXX
 SG_ APS_sw268_vendorIdMismatchMIF1 m268 : 25|1@1+ (1,0) [0|0] "" Vector__XXX
 SG_ APS_sw271_fifoParity3 m271 : 25|1@1+ (1,0) [0|0] "" Vector__XXX
 SG_ APS_sw272_fifoParity3 m272 : 25|1@1+ (1,0) [0|0] "" Vector__XXX
 SG_ APS_sw273_fifoParity3 m273 : 25|1@1+ (1,0) [0|0] "" Vector__XXX
 SG_ APS_sw274_fifoParity3 m274 : 25|1@1+ (1,0) [0|0] "" Vector__XXX
 SG_ APS_sw275_fifoParity3 m275 : 25|1@1+ (1,0) [0|0] "" Vector__XXX
 SG_ APS_sw276_fifoParity3 m276 : 25|1@1+ (1,0) [0|0] "" Vector__XXX
 SG_ APS_sw277_fifoParity3 m277 : 25|1@1+ (1,0) [0|0] "" Vector__XXX
 SG_ APS_sw278_fifoParity3 m278 : 25|1@1+ (1,0) [0|0] "" Vector__XXX
 SG_ APS_sw005_radSGUFailure m5 : 26|1@1+ (1,0) [0|0] "" Vector__XXX
 SG_ APS_sw006_AutofixOutOfCalib m6 : 26|1@1+ (1,0) [0|0] "" Vector__XXX
 SG_ APS_sw015_PartialBlockage m15 : 26|2@1+ (1,0) [0|0] "" Vector__XXX
 SG_ APS_sw017_numCrcErrors m17 : 26|6@1+ (1,0) [0|0] "" Vector__XXX
 SG_ APS_sw027_Unused_Bit_1 m27 : 26|1@1+ (1,0) [0|0] "" Vector__XXX
 SG_ APS_sw041_max_rate m41 : 26|10@1- (1,0) [0|0] "" Vector__XXX
 SG_ APS_sw048_eyeQVersionMismatch m48 : 26|1@1+ (1,0) [0|0] "" Vector__XXX
 SG_ APS_sw053_a20bdyInvalidChkSm m53 : 26|1@1+ (1,0) [0|0] "" Vector__XXX
 SG_ APS_sw057_odo m57 : 26|1@1+ (1,0) [0|0] "" Vector__XXX
 SG_ APS_sw059_oloDict m59 : 26|1@1+ (1,0) [0|0] "" Vector__XXX
 SG_ APS_sw068_virtualLaneSTW m68 : 26|14@1+ (0.1,-819.2) [0|0] "" Vector__XXX
 SG_ APS_sw072_vehicleY m72 : 26|10@1+ (0.05,-25.6) [0|0] "" Vector__XXX
 SG_ APS_sw073_freespaceLeftC0 m73 : 26|7@1+ (0.2,-12.8) [0|0] "" Vector__XXX
 SG_ APS_sw133_phyInterruptStorm m133 : 26|1@1+ (1,0) [0|0] "" Vector__XXX
 SG_ APS_sw134_dasLanes m134 : 26|1@1+ (1,0) [0|0] "" Vector__XXX
 SG_ APS_sw137_gpsPPSMissing m137 : 26|1@1+ (1,0) [0|0] "" Vector__XXX
 SG_ APS_sw138_UARTbusFull m138 : 26|1@1+ (1,0) [0|0] "" Vector__XXX
 SG_ APS_sw151_parkerType m151 : 26|1@1+ (1,0) [0|0] "" Vector__XXX
 SG_ APS_sw155_IPRTEError m155 : 26|1@1+ (1,0) [0|0] "" Vector__XXX
 SG_ APS_sw158_dasPscControl m158 : 26|1@1+ (1,0) [0|0] "" Vector__XXX
 SG_ APS_sw192_msgIo m192 : 26|2@1+ (1,0) [0|0] "" Vector__XXX
 SG_ APS_sw230_sensor11Blocked m230 : 26|1@1+ (1,0) [0|0] "" Vector__XXX
 SG_ APS_sw235_unrecoverableFailReset m235 : 26|1@1+ (1,0) [0|0] "" Vector__XXX
 SG_ APS_sw241_phy0RdlvlReinitTrainingTimeout m241 : 26|1@1+ (1,0) [0|0] "" Vector__XXX
 SG_ APS_sw255_udpInitBootError m255 : 26|1@1+ (1,0) [0|0] "" Vector__XXX
 SG_ APS_sw260_pgoodPmicFaultSd2 m260 : 26|1@1+ (1,0) [0|0] "" Vector__XXX
 SG_ APS_sw264_rdlvl_reinit_tier2 m264 : 26|1@1+ (1,0) [0|0] "" Vector__XXX
 SG_ APS_sw265_rdlvl_reinit_tier3 m265 : 26|1@1+ (1,0) [0|0] "" Vector__XXX
 SG_ APS_sw266_rdlvl_reinit_tier3 m266 : 26|1@1+ (1,0) [0|0] "" Vector__XXX
 SG_ APS_sw267_rdlvl_reinit_tier3 m267 : 26|1@1+ (1,0) [0|0] "" Vector__XXX
 SG_ APS_sw268_rd_uncorrectable_crc2 m268 : 26|1@1+ (1,0) [0|0] "" Vector__XXX
 SG_ APS_sw271_fifoParity4 m271 : 26|1@1+ (1,0) [0|0] "" Vector__XXX
 SG_ APS_sw272_fifoParity4 m272 : 26|1@1+ (1,0) [0|0] "" Vector__XXX
 SG_ APS_sw273_fifoParity4 m273 : 26|1@1+ (1,0) [0|0] "" Vector__XXX
 SG_ APS_sw274_fifoParity4 m274 : 26|1@1+ (1,0) [0|0] "" Vector__XXX
 SG_ APS_sw275_fifoParity4 m275 : 26|1@1+ (1,0) [0|0] "" Vector__XXX
 SG_ APS_sw276_fifoParity4 m276 : 26|1@1+ (1,0) [0|0] "" Vector__XXX
 SG_ APS_sw277_fifoParity4 m277 : 26|1@1+ (1,0) [0|0] "" Vector__XXX
 SG_ APS_sw278_fifoParity4 m278 : 26|1@1+ (1,0) [0|0] "" Vector__XXX
 SG_ APS_sw297_wdogMonTaskCurrCheckinMisses m297 : 26|7@1+ (1,0) [0|0] "" Vector__XXX
 SG_ APS_sw005_radMia m5 : 27|1@1+ (1,0) [0|0] "" Vector__XXX
 SG_ APS_sw006_AutofixOutOfCalibHorzn m6 : 27|1@1+ (1,0) [0|0] "" Vector__XXX
 SG_ APS_sw025_rightLaneUsage m25 : 27|2@1+ (1,0) [0|0] "" Vector__XXX
 SG_ APS_sw026_execution_time m26 : 27|9@1+ (0.125,0) [0|0] "" Vector__XXX
 SG_ APS_sw027_f_PLL_1_Off m27 : 27|1@1+ (1,0) [0|0] "" Vector__XXX
 SG_ APS_sw048_camIssue m48 : 27|1@1+ (1,0) [0|0] "" Vector__XXX
 SG_ APS_sw053_a21espInvalidChkSm m53 : 27|1@1+ (1,0) [0|0] "" Vector__XXX
 SG_ APS_sw057_hvacRequest m57 : 27|1@1+ (1,0) [0|0] "" Vector__XXX
 SG_ APS_sw059_oocStatus m59 : 27|1@1+ (1,0) [0|0] "" Vector__XXX
 SG_ APS_sw070_driveRail m70 : 27|1@1+ (1,0) [0|0] "" Vector__XXX
 SG_ APS_sw133_switchEthernetInterLinkDown m133 : 27|1@1+ (1,0) [0|0] "" Vector__XXX
 SG_ APS_sw134_dasObject m134 : 27|1@1+ (1,0) [0|0] "" Vector__XXX
 SG_ APS_sw138_UARTframeError m138 : 27|1@1+ (1,0) [0|0] "" Vector__XXX
 SG_ APS_sw155_IPCheckError m155 : 27|1@1+ (1,0) [0|0] "" Vector__XXX
 SG_ APS_sw158_dasStatus m158 : 27|1@1+ (1,0) [0|0] "" Vector__XXX
 SG_ APS_sw199_currentSTW m199 : 27|14@1+ (0.1,-819.2) [0|0] "" Vector__XXX
 SG_ APS_sw230_sensor12Blocked m230 : 27|1@1+ (1,0) [0|0] "" Vector__XXX
 SG_ APS_sw235_generalGic m235 : 27|1@1+ (1,0) [0|0] "" Vector__XXX
 SG_ APS_sw241_phy0RdlvlReinitFailed m241 : 27|1@1+ (1,0) [0|0] "" Vector__XXX
 SG_ APS_sw255_gpsInitBootError m255 : 27|1@1+ (1,0) [0|0] "" Vector__XXX
 SG_ APS_sw260_pgoodPmicFaultSd3 m260 : 27|1@1+ (1,0) [0|0] "" Vector__XXX
 SG_ APS_sw264_rdlvl_reinit_tier3 m264 : 27|1@1+ (1,0) [0|0] "" Vector__XXX
 SG_ APS_sw265_wdqlvl_phase_margin_error m265 : 27|1@1+ (1,0) [0|0] "" Vector__XXX
 SG_ APS_sw266_wdqlvl_phase_margin_error m266 : 27|1@1+ (1,0) [0|0] "" Vector__XXX
 SG_ APS_sw267_wdqlvl_phase_margin_error m267 : 27|1@1+ (1,0) [0|0] "" Vector__XXX
 SG_ APS_sw268_rd_correctable_crc2 m268 : 27|1@1+ (1,0) [0|0] "" Vector__XXX
 SG_ APS_sw271_fifoParity5 m271 : 27|1@1+ (1,0) [0|0] "" Vector__XXX
 SG_ APS_sw272_fifoParity5 m272 : 27|1@1+ (1,0) [0|0] "" Vector__XXX
 SG_ APS_sw273_fifoParity5 m273 : 27|1@1+ (1,0) [0|0] "" Vector__XXX
 SG_ APS_sw274_fifoParity5 m274 : 27|1@1+ (1,0) [0|0] "" Vector__XXX
 SG_ APS_sw275_fifoParity5 m275 : 27|1@1+ (1,0) [0|0] "" Vector__XXX
 SG_ APS_sw276_fifoParity5 m276 : 27|1@1+ (1,0) [0|0] "" Vector__XXX
 SG_ APS_sw277_fifoParity5 m277 : 27|1@1+ (1,0) [0|0] "" Vector__XXX
 SG_ APS_sw278_fifoParity5 m278 : 27|1@1+ (1,0) [0|0] "" Vector__XXX
 SG_ APS_sw004_appMobileyeStatus m4 : 28|5@1+ (1,0) [0|0] "" Vector__XXX
 SG_ APS_sw005_radCalibration m5 : 28|1@1+ (1,0) [0|0] "" Vector__XXX
 SG_ APS_sw006_AutofixOutOfCalibYaw m6 : 28|1@1+ (1,0) [0|0] "" Vector__XXX
 SG_ APS_sw015_AutofixOutOfCalib m15 : 28|2@1+ (1,0) [0|0] "" Vector__XXX
 SG_ APS_sw027_Unused_Nibble m27 : 28|4@1+ (1,0) [0|0] "" Vector__XXX
 SG_ APS_sw044_meMainState m44 : 28|4@1+ (1,0) [0|0] "" Vector__XXX
 SG_ APS_sw048_parkerIssue m48 : 28|1@1+ (1,0) [0|0] "" Vector__XXX
 SG_ APS_sw053_a22sccmInvalidChkSm m53 : 28|1@1+ (1,0) [0|0] "" Vector__XXX
 SG_ APS_sw057_phoneLocStatusMia m57 : 28|1@1+ (1,0) [0|0] "" Vector__XXX
 SG_ APS_sw070_accRail m70 : 28|1@1+ (1,0) [0|0] "" Vector__XXX
 SG_ APS_sw133_ethSwitchReadFwVerFailed m133 : 28|1@1+ (1,0) [0|0] "" Vector__XXX
 SG_ APS_sw134_dasPscControl m134 : 28|1@1+ (1,0) [0|0] "" Vector__XXX
 SG_ APS_sw138_UBXrxFrameTooBig m138 : 28|1@1+ (1,0) [0|0] "" Vector__XXX
 SG_ APS_sw155_IPMemError m155 : 28|1@1+ (1,0) [0|0] "" Vector__XXX
 SG_ APS_sw158_dasStatus2 m158 : 28|1@1+ (1,0) [0|0] "" Vector__XXX
 SG_ APS_sw192_queueFailure m192 : 28|2@1+ (1,0) [0|0] "" Vector__XXX
 SG_ APS_sw235_a72WdtTimeout m235 : 28|1@1+ (1,0) [0|0] "" Vector__XXX
 SG_ APS_sw241_phy0WdqlvlReinitTrainingTimeout m241 : 28|1@1+ (1,0) [0|0] "" Vector__XXX
 SG_ APS_sw250_txPacketDrop m250 : 28|12@1+ (1,0) [0|0] "" Vector__XXX
 SG_ APS_sw251_txPacketDrop m251 : 28|12@1+ (1,0) [0|0] "" Vector__XXX
 SG_ APS_sw255_canInitBootError m255 : 28|1@1+ (1,0) [0|0] "" Vector__XXX
 SG_ APS_sw260_pgoodPmicFaultSd4 m260 : 28|1@1+ (1,0) [0|0] "" Vector__XXX
 SG_ APS_sw264_wdqlvl_reinit_tier1 m264 : 28|1@1+ (1,0) [0|0] "" Vector__XXX
 SG_ APS_sw265_wdqlvl_reinit_tier1 m265 : 28|1@1+ (1,0) [0|0] "" Vector__XXX
 SG_ APS_sw266_wdqlvl_reinit_tier1 m266 : 28|1@1+ (1,0) [0|0] "" Vector__XXX
 SG_ APS_sw267_wdqlvl_reinit_tier1 m267 : 28|1@1+ (1,0) [0|0] "" Vector__XXX
 SG_ APS_sw268_wr_uncorrectable_crc2 m268 : 28|1@1+ (1,0) [0|0] "" Vector__XXX
 SG_ APS_sw269_RxPageCountPort1 m269 : 28|12@1+ (1,0) [0|0] "" Vector__XXX
 SG_ APS_sw270_RxPageCountPort5 m270 : 28|12@1+ (1,0) [0|0] "" Vector__XXX
 SG_ APS_sw271_fifoParity6 m271 : 28|1@1+ (1,0) [0|0] "" Vector__XXX
 SG_ APS_sw272_fifoParity6 m272 : 28|1@1+ (1,0) [0|0] "" Vector__XXX
 SG_ APS_sw273_fifoParity6 m273 : 28|1@1+ (1,0) [0|0] "" Vector__XXX
 SG_ APS_sw274_fifoParity6 m274 : 28|1@1+ (1,0) [0|0] "" Vector__XXX
 SG_ APS_sw275_fifoParity6 m275 : 28|1@1+ (1,0) [0|0] "" Vector__XXX
 SG_ APS_sw276_fifoParity6 m276 : 28|1@1+ (1,0) [0|0] "" Vector__XXX
 SG_ APS_sw277_fifoParity6 m277 : 28|1@1+ (1,0) [0|0] "" Vector__XXX
 SG_ APS_sw278_fifoParity6 m278 : 28|1@1+ (1,0) [0|0] "" Vector__XXX
 SG_ APS_sw005_brakePedal m5 : 29|1@1+ (1,0) [0|0] "" Vector__XXX
 SG_ APS_sw006_FullBlockage m6 : 29|1@1+ (1,0) [0|0] "" Vector__XXX
 SG_ APS_sw018_railID m18 : 29|2@1+ (1,0) [0|0] "" Vector__XXX
 SG_ APS_sw025_vehiclesUsage m25 : 29|2@1+ (1,0) [0|0] "" Vector__XXX
 SG_ APS_sw048_prolongedUiMia m48 : 29|1@1+ (1,0) [0|0] "" Vector__XXX
 SG_ APS_sw053_a23sccmInvalidChkSm m53 : 29|1@1+ (1,0) [0|0] "" Vector__XXX
 SG_ APS_sw069_parkCal m69 : 29|1@1+ (1,0) [0|0] "" Vector__XXX
 SG_ APS_sw133_ethSwitchFailedToBoot m133 : 29|1@1+ (1,0) [0|0] "" Vector__XXX
 SG_ APS_sw134_dasStatus m134 : 29|1@1+ (1,0) [0|0] "" Vector__XXX
 SG_ APS_sw138_emptyValidNMEA m138 : 29|1@1+ (1,0) [0|0] "" Vector__XXX
 SG_ APS_sw155_IPDropError m155 : 29|1@1+ (1,0) [0|0] "" Vector__XXX
 SG_ APS_sw158_dasSteeringControl m158 : 29|1@1+ (1,0) [0|0] "" Vector__XXX
 SG_ APS_sw218_mcuAutosteerRestricted m218 : 29|1@1+ (1,0) [0|0] "" Vector__XXX
 SG_ APS_sw235_generalScs m235 : 29|1@1+ (1,0) [0|0] "" Vector__XXX
 SG_ APS_sw241_phy0WdqlvlPhaseMarginOutOfRange m241 : 29|1@1+ (1,0) [0|0] "" Vector__XXX
 SG_ APS_sw255_dfuCheckinSubsystemBootError m255 : 29|1@1+ (1,0) [0|0] "" Vector__XXX
 SG_ APS_sw260_pgoodPmicFaultLdo0 m260 : 29|1@1+ (1,0) [0|0] "" Vector__XXX
 SG_ APS_sw264_wdqlvl_reinit_tier2 m264 : 29|1@1+ (1,0) [0|0] "" Vector__XXX
 SG_ APS_sw265_wdqlvl_reinit_tier2 m265 : 29|1@1+ (1,0) [0|0] "" Vector__XXX
 SG_ APS_sw266_wdqlvl_reinit_tier2 m266 : 29|1@1+ (1,0) [0|0] "" Vector__XXX
 SG_ APS_sw267_wdqlvl_reinit_tier2 m267 : 29|1@1+ (1,0) [0|0] "" Vector__XXX
 SG_ APS_sw268_wr_correctable_crc2 m268 : 29|1@1+ (1,0) [0|0] "" Vector__XXX
 SG_ APS_sw271_fifoParity7 m271 : 29|1@1+ (1,0) [0|0] "" Vector__XXX
 SG_ APS_sw272_fifoParity7 m272 : 29|1@1+ (1,0) [0|0] "" Vector__XXX
 SG_ APS_sw273_fifoParity7 m273 : 29|1@1+ (1,0) [0|0] "" Vector__XXX
 SG_ APS_sw274_fifoParity7 m274 : 29|1@1+ (1,0) [0|0] "" Vector__XXX
 SG_ APS_sw275_fifoParity7 m275 : 29|1@1+ (1,0) [0|0] "" Vector__XXX
 SG_ APS_sw276_fifoParity7 m276 : 29|1@1+ (1,0) [0|0] "" Vector__XXX
 SG_ APS_sw277_fifoParity7 m277 : 29|1@1+ (1,0) [0|0] "" Vector__XXX
 SG_ APS_sw278_fifoParity7 m278 : 29|1@1+ (1,0) [0|0] "" Vector__XXX
 SG_ APS_sw005_steeringAngle m5 : 30|1@1+ (1,0) [0|0] "" Vector__XXX
 SG_ APS_sw006_SmearedHalos m6 : 30|1@1+ (1,0) [0|0] "" Vector__XXX
 SG_ APS_sw015_AutofixOutOfCalibYaw m15 : 30|2@1+ (1,0) [0|0] "" Vector__XXX
 SG_ APS_sw047_edrBlackBox m47 : 30|2@1+ (1,0) [0|0] "" Vector__XXX
 SG_ APS_sw048_uiMiaAtBootup m48 : 30|1@1+ (1,0) [0|0] "" Vector__XXX
 SG_ APS_sw053_a24absValidity m53 : 30|1@1+ (1,0) [0|0] "" Vector__XXX
 SG_ APS_sw067_epasSTW m67 : 30|14@1+ (0.1,-819.2) [0|0] "" Vector__XXX
 SG_ APS_sw069_torsionBar m69 : 30|12@1+ (0.01,-20.5) [0|0] "" Vector__XXX
 SG_ APS_sw071_endPosY m71 : 30|10@1+ (0.05,-25.6) [0|0] "" Vector__XXX
 SG_ APS_sw129_maxThreshold m129 : 30|13@1+ (1,50) [0|0] "" Vector__XXX
 SG_ APS_sw133_ethSwitchTimedoutUpdate m133 : 30|1@1+ (1,0) [0|0] "" Vector__XXX
 SG_ APS_sw134_dasStatus2 m134 : 30|1@1+ (1,0) [0|0] "" Vector__XXX
 SG_ APS_sw138_invalidAsciiNMEA m138 : 30|1@1+ (1,0) [0|0] "" Vector__XXX
 SG_ APS_sw155_IPProtoError m155 : 30|1@1+ (1,0) [0|0] "" Vector__XXX
 SG_ APS_sw158_dasVisualDebug m158 : 30|1@1+ (1,0) [0|0] "" Vector__XXX
 SG_ APS_sw194_leadVx m194 : 30|6@1- (0.2,0) [0|0] "" Vector__XXX
 SG_ APS_sw227_sensorMeasurement m227 : 30|9@1+ (1,0) [0|0] "" Vector__XXX
 SG_ APS_sw235_generalUnexpected m235 : 30|1@1+ (1,0) [0|0] "" Vector__XXX
 SG_ APS_sw241_phy0WdqlvlReinitFailed m241 : 30|1@1+ (1,0) [0|0] "" Vector__XXX
 SG_ APS_sw255_sectorProtectionBootError m255 : 30|1@1+ (1,0) [0|0] "" Vector__XXX
 SG_ APS_sw260_pgoodPmicFaultLdo1 m260 : 30|1@1+ (1,0) [0|0] "" Vector__XXX
 SG_ APS_sw264_wdqlvl_reinit_tier3 m264 : 30|1@1+ (1,0) [0|0] "" Vector__XXX
 SG_ APS_sw265_wdqlvl_reinit_tier3 m265 : 30|1@1+ (1,0) [0|0] "" Vector__XXX
 SG_ APS_sw266_wdqlvl_reinit_tier3 m266 : 30|1@1+ (1,0) [0|0] "" Vector__XXX
 SG_ APS_sw267_wdqlvl_reinit_tier3 m267 : 30|1@1+ (1,0) [0|0] "" Vector__XXX
 SG_ APS_sw268_vendorIdMismatchMIF2 m268 : 30|1@1+ (1,0) [0|0] "" Vector__XXX
 SG_ APS_sw271_fifoParity8 m271 : 30|1@1+ (1,0) [0|0] "" Vector__XXX
 SG_ APS_sw272_fifoParity8 m272 : 30|1@1+ (1,0) [0|0] "" Vector__XXX
 SG_ APS_sw273_fifoParity8 m273 : 30|1@1+ (1,0) [0|0] "" Vector__XXX
 SG_ APS_sw274_fifoParity8 m274 : 30|1@1+ (1,0) [0|0] "" Vector__XXX
 SG_ APS_sw275_fifoParity8 m275 : 30|1@1+ (1,0) [0|0] "" Vector__XXX
 SG_ APS_sw276_fifoParity8 m276 : 30|1@1+ (1,0) [0|0] "" Vector__XXX
 SG_ APS_sw277_fifoParity8 m277 : 30|1@1+ (1,0) [0|0] "" Vector__XXX
 SG_ APS_sw278_fifoParity8 m278 : 30|1@1+ (1,0) [0|0] "" Vector__XXX
 SG_ APS_sw005_steeringAngleRate m5 : 31|1@1+ (1,0) [0|0] "" Vector__XXX
 SG_ APS_sw006_FoggyLights m6 : 31|1@1+ (1,0) [0|0] "" Vector__XXX
 SG_ APS_sw018_powerSequnceError m18 : 31|1@1+ (1,0) [0|0] "" Vector__XXX
 SG_ APS_sw053_a25ambTValidity m53 : 31|1@1+ (1,0) [0|0] "" Vector__XXX
 SG_ APS_sw133_ethSwitchMcuLinkFailover m133 : 31|1@1+ (1,0) [0|0] "" Vector__XXX
 SG_ APS_sw134_dasSteeringControl m134 : 31|1@1+ (1,0) [0|0] "" Vector__XXX
 SG_ APS_sw138_wheeltickUARTfault m138 : 31|1@1+ (1,0) [0|0] "" Vector__XXX
 SG_ APS_sw158_dasSteeringControlPty m158 : 31|1@1+ (1,0) [0|0] "" Vector__XXX
 SG_ APS_sw200_epasHandsOnDetected m200 : 31|1@1+ (1,0) [0|0] "" Vector__XXX
 SG_ APS_sw213_epasHandsOnDetected m213 : 31|1@1+ (1,0) [0|0] "" Vector__XXX
 SG_ APS_sw235_canUncorrectedBitError m235 : 31|1@1+ (1,0) [0|0] "" Vector__XXX
 SG_ APS_sw241_phy1TimeoutWaitingForInterrupts m241 : 31|1@1+ (1,0) [0|0] "" Vector__XXX
 SG_ APS_sw255_flashOpBootError m255 : 31|1@1+ (1,0) [0|0] "" Vector__XXX
 SG_ APS_sw260_pgoodPmicFaultLdo2 m260 : 31|1@1+ (1,0) [0|0] "" Vector__XXX
 SG_ APS_sw264_mcbist_fail_ch0 m264 : 31|1@1+ (1,0) [0|0] "" Vector__XXX
 SG_ APS_sw265_mcbist_fail_ch0 m265 : 31|1@1+ (1,0) [0|0] "" Vector__XXX
 SG_ APS_sw266_mcbist_fail_ch0 m266 : 31|1@1+ (1,0) [0|0] "" Vector__XXX
 SG_ APS_sw267_mcbist_fail_ch0 m267 : 31|1@1+ (1,0) [0|0] "" Vector__XXX
 SG_ APS_sw268_rd_uncorrectable_crc3 m268 : 31|1@1+ (1,0) [0|0] "" Vector__XXX
 SG_ APS_sw271_rdCrcErr m271 : 31|1@1+ (1,0) [0|0] "" Vector__XXX
 SG_ APS_sw272_rdCrcErr m272 : 31|1@1+ (1,0) [0|0] "" Vector__XXX
 SG_ APS_sw273_rdCrcErr m273 : 31|1@1+ (1,0) [0|0] "" Vector__XXX
 SG_ APS_sw274_rdCrcErr m274 : 31|1@1+ (1,0) [0|0] "" Vector__XXX
 SG_ APS_sw275_rdCrcErr m275 : 31|1@1+ (1,0) [0|0] "" Vector__XXX
 SG_ APS_sw276_rdCrcErr m276 : 31|1@1+ (1,0) [0|0] "" Vector__XXX
 SG_ APS_sw277_rdCrcErr m277 : 31|1@1+ (1,0) [0|0] "" Vector__XXX
 SG_ APS_sw278_rdCrcErr m278 : 31|1@1+ (1,0) [0|0] "" Vector__XXX
 SG_ APS_sw001_APS_alertDataW1 m1 : 32|16@1+ (1,0) [0|0] "" Vector__XXX
 SG_ APS_sw005_speed m5 : 32|1@1+ (1,0) [0|0] "" Vector__XXX
 SG_ APS_sw006_SelfGlare m6 : 32|1@1+ (1,0) [0|0] "" Vector__XXX
 SG_ APS_sw011_scaSonicDist m11 : 32|5@1+ (0.05,0) [0|0] "" Vector__XXX
 SG_ APS_sw012_bootDDRTempStatus m12 : 32|2@1+ (1,0) [0|0] "" Vector__XXX
 SG_ APS_sw013_numSeqErrors m13 : 32|8@1+ (1,0) [0|0] "" Vector__XXX
 SG_ APS_sw014_lineNumberInCode m14 : 32|16@1+ (1,0) [0|0] "" Vector__XXX
 SG_ APS_sw015_AutofixOOfCalibHorizon m15 : 32|2@1+ (1,0) [0|0] "" Vector__XXX
 SG_ APS_sw017_numSeqErrors m17 : 32|8@1+ (1,0) [0|0] "" Vector__XXX
 SG_ APS_sw018_maxThreshold m18 : 32|15@1+ (1,50) [0|0] "" Vector__XXX
 SG_ APS_sw019_timeStamp m19 : 32|32@1+ (1,0) [0|0] "" Vector__XXX
 SG_ APS_sw020_unusedW1 m20 : 32|16@1+ (1,0) [0|0] "" Vector__XXX
 SG_ APS_sw021_maxThreshold m21 : 32|8@1- (1,0) [0|0] "" Vector__XXX
 SG_ APS_sw022_errorCode m22 : 32|32@1+ (1,0) [0|0] "" Vector__XXX
 SG_ APS_sw024_taskProgramCounter m24 : 32|32@1+ (1,0) [0|0] "" Vector__XXX
 SG_ APS_sw025_hppUsage m25 : 32|2@1+ (1,0) [0|0] "" Vector__XXX
 SG_ APS_sw027_LVD_1v2 m27 : 32|1@1+ (1,0) [0|0] "" Vector__XXX
 SG_ APS_sw028_highestSeqRcvd m28 : 32|16@1+ (1,0) [0|0] "" Vector__XXX
 SG_ APS_sw029_highestSeqRcvd m29 : 32|16@1+ (1,0) [0|0] "" Vector__XXX
 SG_ APS_sw030_unusedW0 m30 : 32|16@1+ (1,0) [0|0] "" Vector__XXX
 SG_ APS_sw031_errorData1 m31 : 32|16@1+ (1,0) [0|0] "" Vector__XXX
 SG_ APS_sw032_errorData1 m32 : 32|16@1+ (1,0) [0|0] "" Vector__XXX
 SG_ APS_sw034_unusedW0 m34 : 32|16@1+ (1,0) [0|0] "" Vector__XXX
 SG_ APS_sw036_unusedW0 m36 : 32|16@1+ (1,0) [0|0] "" Vector__XXX
 SG_ APS_sw037_unusedW0 m37 : 32|16@1+ (1,0) [0|0] "" Vector__XXX
 SG_ APS_sw039_unusedW0 m39 : 32|16@1+ (1,0) [0|0] "" Vector__XXX
 SG_ APS_sw040_das_steering_req m40 : 32|8@1+ (1,-128) [0|0] "" Vector__XXX
 SG_ APS_sw042_state_before_abort m42 : 32|4@1+ (1,0) [0|0] "" Vector__XXX
 SG_ APS_sw043_mesp_health_main_state m43 : 32|16@1+ (1,0) [0|0] "" Vector__XXX
 SG_ APS_sw044_timestampms m44 : 32|32@1+ (1,0) [0|0] "" Vector__XXX
 SG_ APS_sw045_unusedW0 m45 : 32|16@1+ (1,0) [0|0] "" Vector__XXX
 SG_ APS_sw046_errorCode m46 : 32|32@1+ (1,0) [0|0] "" Vector__XXX
 SG_ APS_sw047_edrReturn m47 : 32|16@1+ (1,0) [0|0] "" Vector__XXX
 SG_ APS_sw049_app_version_msw m49 : 32|16@1+ (1,0) [0|0] "" Vector__XXX
 SG_ APS_sw051_HWFail m51 : 32|1@1+ (1,0) [0|0] "" Vector__XXX
 SG_ APS_sw053_a26brakeValidity m53 : 32|1@1+ (1,0) [0|0] "" Vector__XXX
 SG_ APS_sw054_Autofix_yaw m54 : 32|8@1+ (1,0) [0|0] "" Vector__XXX
 SG_ APS_sw056_unusedW0 m56 : 32|16@1+ (1,0) [0|0] "" Vector__XXX
 SG_ APS_sw058_unusedW0 m58 : 32|16@1+ (1,0) [0|0] "" Vector__XXX
 SG_ APS_sw062_VerticalMisalignment m62 : 32|10@1+ (0.087977,-45) [0|0] "" Vector__XXX
 SG_ APS_sw063_expectedMinorVer m63 : 32|8@1+ (1,0) [0|0] "" Vector__XXX
 SG_ APS_sw065_unusedW0 m65 : 32|16@1+ (1,0) [0|0] "" Vector__XXX
 SG_ APS_sw066_unusedW0 m66 : 32|16@1+ (1,0) [0|0] "" Vector__XXX
 SG_ APS_sw070_temperature m70 : 32|8@1+ (0.5,-40) [0|0] "" Vector__XXX
 SG_ APS_sw074_ipsoDz m74 : 32|6@1+ (0.2,-6.4) [0|0] "" Vector__XXX
 SG_ APS_sw075_unusedW0 m75 : 32|16@1+ (1,0) [0|0] "" Vector__XXX
 SG_ APS_sw077_oocCollisionSide m77 : 32|3@1+ (1,0) [0|0] "" Vector__XXX
 SG_ APS_sw078_radarTarg5_dx m78 : 32|8@1+ (0.0625,0) [0|0] "" Vector__XXX
 SG_ APS_sw080_stw_angle_deg m80 : 32|8@1+ (1,0) [0|0] "" Vector__XXX
 SG_ APS_sw081_cameraDistance m81 : 32|8@1+ (0.0625,0) [0|0] "" Vector__XXX
 SG_ APS_sw082_L_Lane m82 : 32|8@1+ (0.05,-6.4) [0|0] "" Vector__XXX
 SG_ APS_sw083_Targ5_dx m83 : 32|12@1+ (0.0625,0) [0|0] "" Vector__XXX
 SG_ APS_sw084_ipsoDx m84 : 32|8@1+ (0.1,0) [0|0] "" Vector__XXX
 SG_ APS_sw085_roadClass m85 : 32|3@1+ (1,0) [0|0] "" Vector__XXX
 SG_ APS_sw086_ellipseWidth m86 : 32|8@1+ (0.1,0) [0|0] "" Vector__XXX
 SG_ APS_sw103_objectDy m103 : 32|8@1+ (0.5,-15.5) [0|0] "" Vector__XXX
 SG_ APS_sw130_minThreshold m130 : 32|8@1- (1,0) [0|0] "" Vector__XXX
 SG_ APS_sw133_ethSwitchMcuLinkDuplicated m133 : 32|1@1+ (1,0) [0|0] "" Vector__XXX
 SG_ APS_sw134_dasVisualDebug m134 : 32|1@1+ (1,0) [0|0] "" Vector__XXX
 SG_ APS_sw138_baudrateMismatch m138 : 32|1@1+ (1,0) [0|0] "" Vector__XXX
 SG_ APS_sw139_overflowBus m139 : 32|3@1+ (1,0) [0|0] "" Vector__XXX
 SG_ APS_sw158_dasChNm m158 : 32|1@1+ (1,0) [0|0] "" Vector__XXX
 SG_ APS_sw171_taskDeviatePercent m171 : 32|8@1+ (1,0) [0|0] "" Vector__XXX
 SG_ APS_sw187_taskDeviatePercent m187 : 32|8@1+ (1,0) [0|0] "" Vector__XXX
 SG_ APS_sw192_msgId m192 : 32|11@1+ (1,0) [0|0] "" Vector__XXX
 SG_ APS_sw195_sdiRearCC m195 : 32|5@1+ (1,0) [0|0] "" Vector__XXX
 SG_ APS_sw200_startSpeed m200 : 32|10@1+ (0.1,-10) [0|0] "" Vector__XXX
 SG_ APS_sw201_timeHorizon m201 : 32|8@1+ (0.1,0) [0|0] "" Vector__XXX
 SG_ APS_sw202_sdiRearCC m202 : 32|5@1+ (1,0) [0|0] "" Vector__XXX
 SG_ APS_sw204_frMiddle m204 : 32|8@1+ (1,0) [0|0] "" Vector__XXX
 SG_ APS_sw205_rrLeftMiddle m205 : 32|8@1+ (1,0) [0|0] "" Vector__XXX
 SG_ APS_sw207_lcUnavailableReason m207 : 32|8@1+ (1,0) [0|0] "" Vector__XXX
 SG_ APS_sw213_startSpeed m213 : 32|10@1+ (0.1,-10) [0|0] "" Vector__XXX
 SG_ APS_sw218_pedalPosition m218 : 32|7@1+ (1,0) [0|0] "" Vector__XXX
 SG_ APS_sw231_targetDistance m231 : 32|7@1+ (0.1,0) [0|0] "" Vector__XXX
 SG_ APS_sw235_canExitBusoffFailed m235 : 32|1@1+ (1,0) [0|0] "" Vector__XXX
 SG_ APS_sw238_assertLineNumber m238 : 32|16@1+ (1,0) [0|0] "" Vector__XXX
 SG_ APS_sw241_phy1Ch0ReadGateOffsetBug m241 : 32|1@1+ (1,0) [0|0] "" Vector__XXX
 SG_ APS_sw243_extendedErrorStatus m243 : 32|24@1+ (1,0) [0|0] "" Vector__XXX
 SG_ APS_sw245_unknownMACAddrByte2 m245 : 32|8@1+ (1,0) [0|0] "" Vector__XXX
 SG_ APS_sw255_socIdInitBootError m255 : 32|1@1+ (1,0) [0|0] "" Vector__XXX
 SG_ APS_sw260_pgoodPmicFaultLdo3 m260 : 32|1@1+ (1,0) [0|0] "" Vector__XXX
 SG_ APS_sw261_vrmRail1FaultValues m261 : 32|8@1+ (1,0) [0|0] "" Vector__XXX
 SG_ APS_sw262_vrmRail1FaultValues m262 : 32|8@1+ (1,0) [0|0] "" Vector__XXX
 SG_ APS_sw263_vrmRail1FaultValues m263 : 32|8@1+ (1,0) [0|0] "" Vector__XXX
 SG_ APS_sw264_mcbist_fail_ch1 m264 : 32|1@1+ (1,0) [0|0] "" Vector__XXX
 SG_ APS_sw265_mcbist_fail_ch1 m265 : 32|1@1+ (1,0) [0|0] "" Vector__XXX
 SG_ APS_sw266_mcbist_fail_ch1 m266 : 32|1@1+ (1,0) [0|0] "" Vector__XXX
 SG_ APS_sw267_mcbist_fail_ch1 m267 : 32|1@1+ (1,0) [0|0] "" Vector__XXX
 SG_ APS_sw268_rd_correctable_crc3 m268 : 32|1@1+ (1,0) [0|0] "" Vector__XXX
 SG_ APS_sw271_reqAddrParityErr m271 : 32|1@1+ (1,0) [0|0] "" Vector__XXX
 SG_ APS_sw272_reqAddrParityErr m272 : 32|1@1+ (1,0) [0|0] "" Vector__XXX
 SG_ APS_sw273_reqAddrParityErr m273 : 32|1@1+ (1,0) [0|0] "" Vector__XXX
 SG_ APS_sw274_reqAddrParityErr m274 : 32|1@1+ (1,0) [0|0] "" Vector__XXX
 SG_ APS_sw275_reqAddrParityErr m275 : 32|1@1+ (1,0) [0|0] "" Vector__XXX
 SG_ APS_sw276_reqAddrParityErr m276 : 32|1@1+ (1,0) [0|0] "" Vector__XXX
 SG_ APS_sw277_reqAddrParityErr m277 : 32|1@1+ (1,0) [0|0] "" Vector__XXX
 SG_ APS_sw278_reqAddrParityErr m278 : 32|1@1+ (1,0) [0|0] "" Vector__XXX
 SG_ APS_sw289_peer_turboTemperature m289 : 32|8@1- (1,0) [0|0] "" Vector__XXX
 SG_ APS_sw292_bitErrorUncorrectedCount m292 : 32|8@1+ (1,0) [0|0] "" Vector__XXX
 SG_ APS_sw293_bitErrorUncorrectedCount m293 : 32|8@1+ (1,0) [0|0] "" Vector__XXX
 SG_ APS_sw294_bitErrorUncorrectedCount m294 : 32|8@1+ (1,0) [0|0] "" Vector__XXX
 SG_ APS_sw295_bitErrorUncorrectedCount m295 : 32|8@1+ (1,0) [0|0] "" Vector__XXX
 SG_ APS_sw296_wdogMonTaskCurrCheckinMisses m296 : 32|7@1+ (1,0) [0|0] "" Vector__XXX
 SG_ APS_sw298_cpuToApInvalidPtrCount m298 : 32|8@1+ (1,0) [0|0] "" Vector__XXX
 SG_ APS_sw299_apToCpuInvalidPtrCount m299 : 32|8@1+ (1,0) [0|0] "" Vector__XXX
 SG_ APS_sw313_bitErrorUncorrectedCount m313 : 32|8@1+ (1,0) [0|0] "" Vector__XXX
 SG_ APS_sw004_diCruiseStateFault m4 : 33|1@1+ (1,0) [0|0] "" Vector__XXX
 SG_ APS_sw005_gear m5 : 33|1@1+ (1,0) [0|0] "" Vector__XXX
 SG_ APS_sw006_blinkers m6 : 33|1@1+ (1,0) [0|0] "" Vector__XXX
 SG_ APS_sw027_Unused_Bit_2 m27 : 33|1@1+ (1,0) [0|0] "" Vector__XXX
 SG_ APS_sw051_SGUFail m51 : 33|1@1+ (1,0) [0|0] "" Vector__XXX
 SG_ APS_sw053_a27CntryCdValidity m53 : 33|1@1+ (1,0) [0|0] "" Vector__XXX
 SG_ APS_sw073_freespaceRightC0 m73 : 33|7@1+ (0.2,-12.8) [0|0] "" Vector__XXX
 SG_ APS_sw133_ethSwitchMcuLinkDisconnected m133 : 33|1@1+ (1,0) [0|0] "" Vector__XXX
 SG_ APS_sw134_dasSteeringControlPty m134 : 33|1@1+ (1,0) [0|0] "" Vector__XXX
 SG_ APS_sw138_wheelTickInvalidSrc m138 : 33|1@1+ (1,0) [0|0] "" Vector__XXX
 SG_ APS_sw158_dasStatusPty m158 : 33|1@1+ (1,0) [0|0] "" Vector__XXX
 SG_ APS_sw203_slotSizeY m203 : 33|8@1+ (4,0) [0|0] "" Vector__XXX
 SG_ APS_sw235_txEnFdbckNotExpected m235 : 33|1@1+ (1,0) [0|0] "" Vector__XXX
 SG_ APS_sw241_phy1Ch1ReadGateOffsetBug m241 : 33|1@1+ (1,0) [0|0] "" Vector__XXX
 SG_ APS_sw260_pgoodPmicFaultLdo4 m260 : 33|1@1+ (1,0) [0|0] "" Vector__XXX
 SG_ APS_sw268_wr_uncorrectable_crc3 m268 : 33|1@1+ (1,0) [0|0] "" Vector__XXX
 SG_ APS_sw271_rdUncorrectableErrFromMemory m271 : 33|1@1+ (1,0) [0|0] "" Vector__XXX
 SG_ APS_sw272_rdUncorrectableErrFromMemory m272 : 33|1@1+ (1,0) [0|0] "" Vector__XXX
 SG_ APS_sw273_rdUncorrectableErrFromMemory m273 : 33|1@1+ (1,0) [0|0] "" Vector__XXX
 SG_ APS_sw274_rdUncorrectableErrFromMemory m274 : 33|1@1+ (1,0) [0|0] "" Vector__XXX
 SG_ APS_sw275_rdUncorrectableErrFromMemory m275 : 33|1@1+ (1,0) [0|0] "" Vector__XXX
 SG_ APS_sw276_rdUncorrectableErrFromMemory m276 : 33|1@1+ (1,0) [0|0] "" Vector__XXX
 SG_ APS_sw277_rdUncorrectableErrFromMemory m277 : 33|1@1+ (1,0) [0|0] "" Vector__XXX
 SG_ APS_sw278_rdUncorrectableErrFromMemory m278 : 33|1@1+ (1,0) [0|0] "" Vector__XXX
 SG_ APS_sw297_wdogMonTaskCurrRecoveryInterval m297 : 33|11@1+ (1,0) [0|0] "" Vector__XXX
 SG_ APS_sw004_diMIA m4 : 34|1@1+ (1,0) [0|0] "" Vector__XXX
 SG_ APS_sw005_stabilityControl m5 : 34|1@1+ (1,0) [0|0] "" Vector__XXX
 SG_ APS_sw006_seatbelt m6 : 34|1@1+ (1,0) [0|0] "" Vector__XXX
 SG_ APS_sw012_mespFatalErrCode m12 : 34|8@1+ (1,0) [0|0] "" Vector__XXX
 SG_ APS_sw015_Splashes m15 : 34|2@1+ (1,0) [0|0] "" Vector__XXX
 SG_ APS_sw016_targetOverlap m16 : 34|6@1+ (0.1,0) [0|0] "" Vector__XXX
 SG_ APS_sw025_navigationUsage m25 : 34|2@1+ (1,0) [0|0] "" Vector__XXX
 SG_ APS_sw027_Watchdog m27 : 34|1@1+ (1,0) [0|0] "" Vector__XXX
 SG_ APS_sw050_targetOverlap m50 : 34|6@1+ (0.1,0) [0|0] "" Vector__XXX
 SG_ APS_sw051_unusedBits m51 : 34|6@1+ (1,0) [0|0] "" Vector__XXX
 SG_ APS_sw053_a28espValidity m53 : 34|1@1+ (1,0) [0|0] "" Vector__XXX
 SG_ APS_sw060_targetOverlap m60 : 34|6@1+ (0.1,0) [0|0] "" Vector__XXX
 SG_ APS_sw076_targetOverlap m76 : 34|6@1+ (0.1,0) [0|0] "" Vector__XXX
 SG_ APS_sw133_unused m133 : 34|30@1+ (1,0) [0|0] "" Vector__XXX
 SG_ APS_sw134_dasChNm m134 : 34|1@1+ (1,0) [0|0] "" Vector__XXX
 SG_ APS_sw138_UARTparityError m138 : 34|1@1+ (1,0) [0|0] "" Vector__XXX
 SG_ APS_sw158_dasStatus2Pty m158 : 34|1@1+ (1,0) [0|0] "" Vector__XXX
 SG_ APS_sw235_nocSmsFailed m235 : 34|1@1+ (1,0) [0|0] "" Vector__XXX
 SG_ APS_sw241_phy1RdlvlReinitTrainingTimeout m241 : 34|1@1+ (1,0) [0|0] "" Vector__XXX
 SG_ APS_sw260_pgoodPmicFaultLdo5 m260 : 34|1@1+ (1,0) [0|0] "" Vector__XXX
 SG_ APS_sw268_wr_correctable_crc3 m268 : 34|1@1+ (1,0) [0|0] "" Vector__XXX
 SG_ APS_sw271_rdCorrectableErrFromBuffer m271 : 34|1@1+ (1,0) [0|0] "" Vector__XXX
 SG_ APS_sw272_rdCorrectableErrFromBuffer m272 : 34|1@1+ (1,0) [0|0] "" Vector__XXX
 SG_ APS_sw273_rdCorrectableErrFromBuffer m273 : 34|1@1+ (1,0) [0|0] "" Vector__XXX
 SG_ APS_sw274_rdCorrectableErrFromBuffer m274 : 34|1@1+ (1,0) [0|0] "" Vector__XXX
 SG_ APS_sw275_rdCorrectableErrFromBuffer m275 : 34|1@1+ (1,0) [0|0] "" Vector__XXX
 SG_ APS_sw276_rdCorrectableErrFromBuffer m276 : 34|1@1+ (1,0) [0|0] "" Vector__XXX
 SG_ APS_sw277_rdCorrectableErrFromBuffer m277 : 34|1@1+ (1,0) [0|0] "" Vector__XXX
 SG_ APS_sw278_rdCorrectableErrFromBuffer m278 : 34|1@1+ (1,0) [0|0] "" Vector__XXX
 SG_ APS_sw004_accelPedalInvalid m4 : 35|1@1+ (1,0) [0|0] "" Vector__XXX
 SG_ APS_sw005_blinkers m5 : 35|1@1+ (1,0) [0|0] "" Vector__XXX
 SG_ APS_sw006_accelPedal m6 : 35|1@1+ (1,0) [0|0] "" Vector__XXX
 SG_ APS_sw027_Unused_Bit_3 m27 : 35|1@1+ (1,0) [0|0] "" Vector__XXX
 SG_ APS_sw053_a29longAccOffValidity m53 : 35|1@1+ (1,0) [0|0] "" Vector__XXX
 SG_ APS_sw077_oocHeight m77 : 35|2@1+ (1,0) [0|0] "" Vector__XXX
 SG_ APS_sw085_leftLaneExist m85 : 35|6@1+ (2,0) [0|0] "" Vector__XXX
 SG_ APS_sw134_appSummon m134 : 35|1@1+ (1,0) [0|0] "" Vector__XXX
 SG_ APS_sw138_UARTrxFifoOverflow m138 : 35|1@1+ (1,0) [0|0] "" Vector__XXX
 SG_ APS_sw158_dasMatrixHighBeamRqVEH m158 : 35|1@1+ (1,0) [0|0] "" Vector__XXX
 SG_ APS_sw235_nocCamFailed m235 : 35|1@1+ (1,0) [0|0] "" Vector__XXX
 SG_ APS_sw241_phy1RdlvlReinitFailed m241 : 35|1@1+ (1,0) [0|0] "" Vector__XXX
 SG_ APS_sw260_pgoodPmicFaultLdo6 m260 : 35|1@1+ (1,0) [0|0] "" Vector__XXX
 SG_ APS_sw268_vendorIdMismatchMIF3 m268 : 35|1@1+ (1,0) [0|0] "" Vector__XXX
 SG_ APS_sw271_parityErrFromMemory m271 : 35|1@1+ (1,0) [0|0] "" Vector__XXX
 SG_ APS_sw272_parityErrFromMemory m272 : 35|1@1+ (1,0) [0|0] "" Vector__XXX
 SG_ APS_sw273_parityErrFromMemory m273 : 35|1@1+ (1,0) [0|0] "" Vector__XXX
 SG_ APS_sw274_parityErrFromMemory m274 : 35|1@1+ (1,0) [0|0] "" Vector__XXX
 SG_ APS_sw275_parityErrFromMemory m275 : 35|1@1+ (1,0) [0|0] "" Vector__XXX
 SG_ APS_sw276_parityErrFromMemory m276 : 35|1@1+ (1,0) [0|0] "" Vector__XXX
 SG_ APS_sw277_parityErrFromMemory m277 : 35|1@1+ (1,0) [0|0] "" Vector__XXX
 SG_ APS_sw278_parityErrFromMemory m278 : 35|1@1+ (1,0) [0|0] "" Vector__XXX
 SG_ APS_sw004_stwAngleInvalid m4 : 36|1@1+ (1,0) [0|0] "" Vector__XXX
 SG_ APS_sw005_yaw m5 : 36|1@1+ (1,0) [0|0] "" Vector__XXX
 SG_ APS_sw006_radMia m6 : 36|1@1+ (1,0) [0|0] "" Vector__XXX
 SG_ APS_sw010_VerticalMisalignment m10 : 36|10@1+ (0.087977,-45) [0|0] "" Vector__XXX
 SG_ APS_sw015_SmearedSpots m15 : 36|2@1+ (1,0) [0|0] "" Vector__XXX
 SG_ APS_sw025_modelUsage m25 : 36|2@1+ (1,0) [0|0] "" Vector__XXX
 SG_ APS_sw026_can_mean_utilization m26 : 36|7@1+ (1,0) [0|0] "" Vector__XXX
 SG_ APS_sw027_LVD_2v7_VREG m27 : 36|1@1+ (1,0) [0|0] "" Vector__XXX
 SG_ APS_sw041_ego_speed m41 : 36|10@1+ (0.05,0) [0|0] "" Vector__XXX
 SG_ APS_sw042_epas_error_code m42 : 36|4@1+ (1,0) [0|0] "" Vector__XXX
 SG_ APS_sw053_a30longAccValidity m53 : 36|1@1+ (1,0) [0|0] "" Vector__XXX
 SG_ APS_sw072_vehicleHeading m72 : 36|10@1+ (0.005,-2.56) [0|0] "" Vector__XXX
 SG_ APS_sw134_appEnvironment m134 : 36|1@1+ (1,0) [0|0] "" Vector__XXX
 SG_ APS_sw138_UARTrxFifoUnderflow m138 : 36|1@1+ (1,0) [0|0] "" Vector__XXX
 SG_ APS_sw158_dasMatrixBendAngleRqPty m158 : 36|1@1+ (1,0) [0|0] "" Vector__XXX
 SG_ APS_sw194_numObstacles m194 : 36|4@1+ (1,0) [0|0] "" Vector__XXX
 SG_ APS_sw235_nocCoreFailed m235 : 36|1@1+ (1,0) [0|0] "" Vector__XXX
 SG_ APS_sw241_phy1WdqlvlReinitTrainingTimeout m241 : 36|1@1+ (1,0) [0|0] "" Vector__XXX
 SG_ APS_sw260_pgoodPmicFaultLdo7 m260 : 36|1@1+ (1,0) [0|0] "" Vector__XXX
 SG_ APS_sw268_rd_uncorrectable_crc4 m268 : 36|1@1+ (1,0) [0|0] "" Vector__XXX
 SG_ APS_sw271_wrCorrectableErrInBufferToDram m271 : 36|1@1+ (1,0) [0|0] "" Vector__XXX
 SG_ APS_sw272_wrCorrectableErrInBufferToDram m272 : 36|1@1+ (1,0) [0|0] "" Vector__XXX
 SG_ APS_sw273_wrCorrectableErrInBufferToDram m273 : 36|1@1+ (1,0) [0|0] "" Vector__XXX
 SG_ APS_sw274_wrCorrectableErrInBufferToDram m274 : 36|1@1+ (1,0) [0|0] "" Vector__XXX
 SG_ APS_sw275_wrCorrectableErrInBufferToDram m275 : 36|1@1+ (1,0) [0|0] "" Vector__XXX
 SG_ APS_sw276_wrCorrectableErrInBufferToDram m276 : 36|1@1+ (1,0) [0|0] "" Vector__XXX
 SG_ APS_sw277_wrCorrectableErrInBufferToDram m277 : 36|1@1+ (1,0) [0|0] "" Vector__XXX
 SG_ APS_sw278_wrCorrectableErrInBufferToDram m278 : 36|1@1+ (1,0) [0|0] "" Vector__XXX
 SG_ APS_sw004_accelerationInvalid m4 : 37|1@1+ (1,0) [0|0] "" Vector__XXX
 SG_ APS_sw005_longAccel m5 : 37|1@1+ (1,0) [0|0] "" Vector__XXX
 SG_ APS_sw006_radHWFailure m6 : 37|1@1+ (1,0) [0|0] "" Vector__XXX
 SG_ APS_sw011_scaSteerAngle m11 : 37|10@1+ (0.1,-51.2) [0|0] "" Vector__XXX
 SG_ APS_sw027_LVD_2v7_Flash m27 : 37|1@1+ (1,0) [0|0] "" Vector__XXX
 SG_ APS_sw053_a31odoValidity m53 : 37|1@1+ (1,0) [0|0] "" Vector__XXX
 SG_ APS_sw077_vehicleSpeed m77 : 37|10@1+ (0.05,-25) [0|0] "" Vector__XXX
 SG_ APS_sw134_dasStatusPty m134 : 37|1@1+ (1,0) [0|0] "" Vector__XXX
 SG_ APS_sw138_UARTtxFifoOverflow m138 : 37|1@1+ (1,0) [0|0] "" Vector__XXX
 SG_ APS_sw158_dasBodyControls2VEH m158 : 37|1@1+ (1,0) [0|0] "" Vector__XXX
 SG_ APS_sw195_sdiSystemNoise m195 : 37|2@1+ (1,0) [0|0] "" Vector__XXX
 SG_ APS_sw202_sdiSystemNoise m202 : 37|2@1+ (1,0) [0|0] "" Vector__XXX
 SG_ APS_sw235_nocScsFailed m235 : 37|1@1+ (1,0) [0|0] "" Vector__XXX
 SG_ APS_sw241_phy1WdqlvlPhaseMarginOutOfRange m241 : 37|1@1+ (1,0) [0|0] "" Vector__XXX
 SG_ APS_sw260_pgoodPmicFaultLdo8 m260 : 37|1@1+ (1,0) [0|0] "" Vector__XXX
 SG_ APS_sw268_rd_correctable_crc4 m268 : 37|1@1+ (1,0) [0|0] "" Vector__XXX
 SG_ APS_sw271_parityErrOnEcc m271 : 37|1@1+ (1,0) [0|0] "" Vector__XXX
 SG_ APS_sw272_parityErrOnEcc m272 : 37|1@1+ (1,0) [0|0] "" Vector__XXX
 SG_ APS_sw273_parityErrOnEcc m273 : 37|1@1+ (1,0) [0|0] "" Vector__XXX
 SG_ APS_sw274_parityErrOnEcc m274 : 37|1@1+ (1,0) [0|0] "" Vector__XXX
 SG_ APS_sw275_parityErrOnEcc m275 : 37|1@1+ (1,0) [0|0] "" Vector__XXX
 SG_ APS_sw276_parityErrOnEcc m276 : 37|1@1+ (1,0) [0|0] "" Vector__XXX
 SG_ APS_sw277_parityErrOnEcc m277 : 37|1@1+ (1,0) [0|0] "" Vector__XXX
 SG_ APS_sw278_parityErrOnEcc m278 : 37|1@1+ (1,0) [0|0] "" Vector__XXX
 SG_ APS_sw004_diSpeedInvalid m4 : 38|1@1+ (1,0) [0|0] "" Vector__XXX
 SG_ APS_sw005_accelPedal m5 : 38|1@1+ (1,0) [0|0] "" Vector__XXX
 SG_ APS_sw006_radSensorBlind m6 : 38|1@1+ (1,0) [0|0] "" Vector__XXX
 SG_ APS_sw015_SmearedHalos m15 : 38|2@1+ (1,0) [0|0] "" Vector__XXX
 SG_ APS_sw025_bottsDotsUsage m25 : 38|2@1+ (1,0) [0|0] "" Vector__XXX
 SG_ APS_sw027_LVD_2v7_IO m27 : 38|1@1+ (1,0) [0|0] "" Vector__XXX
 SG_ APS_sw053_a32gearValidity m53 : 38|1@1+ (1,0) [0|0] "" Vector__XXX
 SG_ APS_sw134_dasStatus2Pty m134 : 38|1@1+ (1,0) [0|0] "" Vector__XXX
 SG_ APS_sw138_esfWtMsgTimeout m138 : 38|1@1+ (1,0) [0|0] "" Vector__XXX
 SG_ APS_sw158_dasRedundantBrakingControl m158 : 38|1@1+ (1,0) [0|0] "" Vector__XXX
 SG_ APS_sw235_model3UiReset m235 : 38|1@1+ (1,0) [0|0] "" Vector__XXX
 SG_ APS_sw241_phy1WdqlvlReinitFailed m241 : 38|1@1+ (1,0) [0|0] "" Vector__XXX
 SG_ APS_sw260_pgoodUfs3V3Fail m260 : 38|1@1+ (1,0) [0|0] "" Vector__XXX
 SG_ APS_sw268_wr_uncorrectable_crc4 m268 : 38|1@1+ (1,0) [0|0] "" Vector__XXX
 SG_ APS_sw004_DASFeaturesDisabled m4 : 39|1@1+ (1,0) [0|0] "" Vector__XXX
 SG_ APS_sw005_fcmSensitivity m5 : 39|1@1+ (1,0) [0|0] "" Vector__XXX
 SG_ APS_sw006_radSGUFailure m6 : 39|1@1+ (1,0) [0|0] "" Vector__XXX
 SG_ APS_sw027_Unused_Bit_4 m27 : 39|1@1+ (1,0) [0|0] "" Vector__XXX
 SG_ APS_sw053_a33steerAngValidity m53 : 39|1@1+ (1,0) [0|0] "" Vector__XXX
 SG_ APS_sw134_dasMatrixHighBeamRqVEH m134 : 39|1@1+ (1,0) [0|0] "" Vector__XXX
 SG_ APS_sw138_PFLASHReadError m138 : 39|1@1+ (1,0) [0|0] "" Vector__XXX
 SG_ APS_sw158_dasRedundantBrakingControlPty m158 : 39|1@1+ (1,0) [0|0] "" Vector__XXX
 SG_ APS_sw195_sdiSystemStatus m195 : 39|1@1+ (1,0) [0|0] "" Vector__XXX
 SG_ APS_sw202_sdiSystemStatus m202 : 39|1@1+ (1,0) [0|0] "" Vector__XXX
 SG_ APS_sw231_targetRelVelocity m231 : 39|6@1+ (0.5,0) [0|0] "" Vector__XXX
 SG_ APS_sw235_modelsUiReset m235 : 39|1@1+ (1,0) [0|0] "" Vector__XXX
 SG_ APS_sw241_phy2TimeoutWaitingForInterrupts m241 : 39|1@1+ (1,0) [0|0] "" Vector__XXX
 SG_ APS_sw260_pgoodTripVrmRailFail m260 : 39|1@1+ (1,0) [0|0] "" Vector__XXX
 SG_ APS_sw268_wr_correctable_crc4 m268 : 39|1@1+ (1,0) [0|0] "" Vector__XXX
 SG_ APS_sw004_appMobileyeNotInVision m4 : 40|1@1+ (1,0) [0|0] "" Vector__XXX
 SG_ APS_sw005_dasDisabled m5 : 40|1@1+ (1,0) [0|0] "" Vector__XXX
 SG_ APS_sw006_brakePedal m6 : 40|1@1+ (1,0) [0|0] "" Vector__XXX
 SG_ APS_sw013_numNaksReceived m13 : 40|8@1+ (1,0) [0|0] "" Vector__XXX
 SG_ APS_sw015_FoggyLights m15 : 40|2@1+ (1,0) [0|0] "" Vector__XXX
 SG_ APS_sw016_hostSpeed m16 : 40|8@1+ (1,0) [0|0] "" Vector__XXX
 SG_ APS_sw017_numTransportErrors m17 : 40|8@1+ (1,0) [0|0] "" Vector__XXX
 SG_ APS_sw021_currentTemperature m21 : 40|8@1- (1,0) [0|0] "" Vector__XXX
 SG_ APS_sw025_offsetSide m25 : 40|2@1+ (1,0) [0|0] "" Vector__XXX
 SG_ APS_sw027_Unused_Byte m27 : 40|8@1+ (1,0) [0|0] "" Vector__XXX
 SG_ APS_sw040_epas_internal_sas m40 : 40|8@1+ (1,-128) [0|0] "" Vector__XXX
 SG_ APS_sw042_cam_SunRay m42 : 40|1@1+ (1,0) [0|0] "" Vector__XXX
 SG_ APS_sw050_hostSpeed m50 : 40|8@1+ (1,0) [0|0] "" Vector__XXX
 SG_ APS_sw051_unusedB0 m51 : 40|8@1+ (1,0) [0|0] "" Vector__XXX
 SG_ APS_sw053_a34steerAngSpdValidity m53 : 40|1@1+ (1,0) [0|0] "" Vector__XXX
 SG_ APS_sw054_unusedByte m54 : 40|8@1+ (1,0) [0|0] "" Vector__XXX
 SG_ APS_sw060_hostSpeed m60 : 40|7@1+ (2,0) [0|0] "" Vector__XXX
 SG_ APS_sw063_detectedMinorVer m63 : 40|8@1+ (1,0) [0|0] "" Vector__XXX
 SG_ APS_sw068_navigationSTW m68 : 40|14@1+ (0.1,-819.2) [0|0] "" Vector__XXX
 SG_ APS_sw070_currentSpeed m70 : 40|12@1+ (0.1,-204.7) [0|0] "" Vector__XXX
 SG_ APS_sw071_roadClass m71 : 40|3@1+ (1,0) [0|0] "" Vector__XXX
 SG_ APS_sw073_freespaceLeftC1 m73 : 40|8@1+ (0.0016,-0.2) [0|0] "" Vector__XXX
 SG_ APS_sw074_ipsoRCS m74 : 40|8@1+ (1,0) [0|0] "" Vector__XXX
 SG_ APS_sw076_hostSpeed m76 : 40|8@1+ (1,0) [0|0] "" Vector__XXX
 SG_ APS_sw078_radarTarg5_VxRel m78 : 40|8@1+ (0.2,-25.6) [0|0] "" Vector__XXX
 SG_ APS_sw080_road_class m80 : 40|3@1+ (1,0) [0|0] "" Vector__XXX
 SG_ APS_sw081_cameraTTC m81 : 40|8@1+ (0.02,0) [0|0] "" Vector__XXX
 SG_ APS_sw082_R_Lane m82 : 40|8@1+ (0.05,-6.4) [0|0] "" Vector__XXX
 SG_ APS_sw084_ipsoDy m84 : 40|8@1+ (0.1,-12.6) [0|0] "" Vector__XXX
 SG_ APS_sw086_ellipseOverlap m86 : 40|8@1+ (0.1,-12.5) [0|0] "" Vector__XXX
 SG_ APS_sw103_objectDz m103 : 40|8@1+ (0.25,-5) [0|0] "" Vector__XXX
 SG_ APS_sw130_tempSensorId m130 : 40|6@1+ (1,0) [0|0] "" Vector__XXX
 SG_ APS_sw134_dasMatrixBendAngleRqPty m134 : 40|1@1+ (1,0) [0|0] "" Vector__XXX
 SG_ APS_sw138_PFLASHWriteError m138 : 40|1@1+ (1,0) [0|0] "" Vector__XXX
 SG_ APS_sw158_timeSinceLastMsg m158 : 40|24@1+ (1,0) [0|0] "" Vector__XXX
 SG_ APS_sw194_numPedstrian m194 : 40|4@1+ (1,0) [0|0] "" Vector__XXX
 SG_ APS_sw195_vehicleSpeed m195 : 40|12@1+ (0.1,0) [0|0] "" Vector__XXX
 SG_ APS_sw201_vehSpeed m201 : 40|8@1+ (1,0) [0|0] "" Vector__XXX
 SG_ APS_sw202_vehicleSpeed m202 : 40|12@1+ (0.1,0) [0|0] "" Vector__XXX
 SG_ APS_sw204_frRight m204 : 40|8@1+ (1,0) [0|0] "" Vector__XXX
 SG_ APS_sw205_rrMiddle m205 : 40|8@1+ (1,0) [0|0] "" Vector__XXX
 SG_ APS_sw227_ambientTemperature m227 : 40|8@1+ (0.5,-40) [0|0] "" Vector__XXX
 SG_ APS_sw235_pmicApOnPrpUnrcvrble m235 : 40|1@1+ (1,0) [0|0] "" Vector__XXX
 SG_ APS_sw241_phy2Ch0ReadGateOffsetBug m241 : 40|1@1+ (1,0) [0|0] "" Vector__XXX
 SG_ APS_sw245_unknownMACAddrByte3 m245 : 40|8@1+ (1,0) [0|0] "" Vector__XXX
 SG_ APS_sw250_txQueueMapPageCountTooHigh m250 : 40|8@1+ (1,0) [0|0] "" Vector__XXX
 SG_ APS_sw251_txQueueMapPageCountTooHigh m251 : 40|8@1+ (1,0) [0|0] "" Vector__XXX
 SG_ APS_sw260_pgoodIntVrmRailFail m260 : 40|1@1+ (1,0) [0|0] "" Vector__XXX
 SG_ APS_sw261_vrmRail2FaultValues m261 : 40|8@1+ (1,0) [0|0] "" Vector__XXX
 SG_ APS_sw262_vrmRail2FaultValues m262 : 40|8@1+ (1,0) [0|0] "" Vector__XXX
 SG_ APS_sw263_vrmRail2FaultValues m263 : 40|8@1+ (1,0) [0|0] "" Vector__XXX
 SG_ APS_sw268_vendorIdMismatchMIF4 m268 : 40|1@1+ (1,0) [0|0] "" Vector__XXX
 SG_ APS_sw269_RxPageCountPort2 m269 : 40|12@1+ (1,0) [0|0] "" Vector__XXX
 SG_ APS_sw270_RxPageCountPort6 m270 : 40|12@1+ (1,0) [0|0] "" Vector__XXX
 SG_ APS_sw289_peer_turboProbe m289 : 40|6@1+ (1,0) [0|0] "" Vector__XXX
 SG_ APS_sw292_bitErrorCorrectedCount m292 : 40|8@1+ (1,0) [0|0] "" Vector__XXX
 SG_ APS_sw293_bitErrorCorrectedCount m293 : 40|8@1+ (1,0) [0|0] "" Vector__XXX
 SG_ APS_sw294_bitErrorCorrectedCount m294 : 40|8@1+ (1,0) [0|0] "" Vector__XXX
 SG_ APS_sw295_bitErrorCorrectedCount m295 : 40|8@1+ (1,0) [0|0] "" Vector__XXX
 SG_ APS_sw296_wdogMonTaskNumOfStrikes m296 : 40|7@1+ (1,0) [0|0] "" Vector__XXX
 SG_ APS_sw299_apToCpuCrcErrorCount m299 : 40|8@1+ (1,0) [0|0] "" Vector__XXX
 SG_ APS_sw313_bitErrorCorrectedCount m313 : 40|8@1+ (1,0) [0|0] "" Vector__XXX
 SG_ APS_sw004_CamCommonMIA m4 : 41|1@1+ (1,0) [0|0] "" Vector__XXX
 SG_ APS_sw005_speedDerivative m5 : 41|1@1+ (1,0) [0|0] "" Vector__XXX
 SG_ APS_sw006_steeringAngle m6 : 41|1@1+ (1,0) [0|0] "" Vector__XXX
 SG_ APS_sw042_cam_RoadSpray m42 : 41|1@1+ (1,0) [0|0] "" Vector__XXX
 SG_ APS_sw053_a35indctrValidity m53 : 41|1@1+ (1,0) [0|0] "" Vector__XXX
 SG_ APS_sw085_rightLaneExist m85 : 41|6@1+ (2,0) [0|0] "" Vector__XXX
 SG_ APS_sw134_dasBodyControls2VEH m134 : 41|1@1+ (1,0) [0|0] "" Vector__XXX
 SG_ APS_sw138_gpsCfgNack m138 : 41|1@1+ (1,0) [0|0] "" Vector__XXX
 SG_ APS_sw199_currentSpeed m199 : 41|8@1+ (0.1,-12.2) [0|0] "" Vector__XXX
 SG_ APS_sw203_startDistance m203 : 41|11@1+ (1,0) [0|0] "" Vector__XXX
 SG_ APS_sw235_apOnReadyTimeout m235 : 41|1@1+ (1,0) [0|0] "" Vector__XXX
 SG_ APS_sw241_phy2Ch1ReadGateOffsetBug m241 : 41|1@1+ (1,0) [0|0] "" Vector__XXX
 SG_ APS_sw260_pgoodCpuVrmRailFail m260 : 41|1@1+ (1,0) [0|0] "" Vector__XXX
 SG_ APS_sw268_rd_uncorrectable_crc5 m268 : 41|1@1+ (1,0) [0|0] "" Vector__XXX
 SG_ APS_sw004_CamObjectsMIA m4 : 42|1@1+ (1,0) [0|0] "" Vector__XXX
 SG_ APS_sw005_camWatchdog m5 : 42|1@1+ (1,0) [0|0] "" Vector__XXX
 SG_ APS_sw006_steeringAngleRate m6 : 42|1@1+ (1,0) [0|0] "" Vector__XXX
 SG_ APS_sw012_mespFatalErrDetails m12 : 42|8@1+ (1,0) [0|0] "" Vector__XXX
 SG_ APS_sw015_SunRay m15 : 42|2@1+ (1,0) [0|0] "" Vector__XXX
 SG_ APS_sw042_cam_BlurredImage m42 : 42|1@1+ (1,0) [0|0] "" Vector__XXX
 SG_ APS_sw053_a36vehStndStllValidty m53 : 42|1@1+ (1,0) [0|0] "" Vector__XXX
 SG_ APS_sw062_unusedBits m62 : 42|6@1+ (1,0) [0|0] "" Vector__XXX
 SG_ APS_sw069_roadClass m69 : 42|4@1+ (1,0) [0|0] "" Vector__XXX
 SG_ APS_sw134_dasRedundantBrakingControl m134 : 42|1@1+ (1,0) [0|0] "" Vector__XXX
 SG_ APS_sw138_gpsCfgIdFail m138 : 42|6@1+ (1,0) [0|0] "" Vector__XXX
 SG_ APS_sw235_pmicApOnWaitUnrcvrble m235 : 42|1@1+ (1,0) [0|0] "" Vector__XXX
 SG_ APS_sw241_phy2RdlvlReinitTrainingTimeout m241 : 42|1@1+ (1,0) [0|0] "" Vector__XXX
 SG_ APS_sw260_pgoodGpuVrmRailFail m260 : 42|1@1+ (1,0) [0|0] "" Vector__XXX
 SG_ APS_sw268_rd_correctable_crc5 m268 : 42|1@1+ (1,0) [0|0] "" Vector__XXX
 SG_ APS_sw004_CamWatchdog m4 : 43|1@1+ (1,0) [0|0] "" Vector__XXX
 SG_ APS_sw005_AutofixOutOfCalibHorzn m5 : 43|1@1+ (1,0) [0|0] "" Vector__XXX
 SG_ APS_sw006_speed m6 : 43|1@1+ (1,0) [0|0] "" Vector__XXX
 SG_ APS_sw026_uds_mean_utilization m26 : 43|7@1+ (1,0) [0|0] "" Vector__XXX
 SG_ APS_sw042_cam_LowSun m42 : 43|1@1+ (1,0) [0|0] "" Vector__XXX
 SG_ APS_sw053_a37vinValidity m53 : 43|1@1+ (1,0) [0|0] "" Vector__XXX
 SG_ APS_sw071_driverPresent m71 : 43|1@1+ (1,0) [0|0] "" Vector__XXX
 SG_ APS_sw080_ego_speed m80 : 43|5@1+ (1,0) [0|0] "" Vector__XXX
 SG_ APS_sw129_minThreshold m129 : 43|13@1+ (1,0) [0|0] "" Vector__XXX
 SG_ APS_sw134_dasRedundantBrakingControlPty m134 : 43|1@1+ (1,0) [0|0] "" Vector__XXX
 SG_ APS_sw235_apBootingTimeout m235 : 43|1@1+ (1,0) [0|0] "" Vector__XXX
 SG_ APS_sw241_phy2RdlvlReinitFailed m241 : 43|1@1+ (1,0) [0|0] "" Vector__XXX
 SG_ APS_sw260_pgoodDdr0V75VrmRailFail m260 : 43|1@1+ (1,0) [0|0] "" Vector__XXX
 SG_ APS_sw268_wr_uncorrectable_crc5 m268 : 43|1@1+ (1,0) [0|0] "" Vector__XXX
 SG_ APS_sw004_RadarLowVisibility m4 : 44|1@1+ (1,0) [0|0] "" Vector__XXX
 SG_ APS_sw005_RadarLowVisibility m5 : 44|1@1+ (1,0) [0|0] "" Vector__XXX
 SG_ APS_sw006_gear m6 : 44|1@1+ (1,0) [0|0] "" Vector__XXX
 SG_ APS_sw015_ImpairedVD m15 : 44|2@1+ (1,0) [0|0] "" Vector__XXX
 SG_ APS_sw042_cam_SmearedSpots m42 : 44|1@1+ (1,0) [0|0] "" Vector__XXX
 SG_ APS_sw053_a38whlRotValidity m53 : 44|1@1+ (1,0) [0|0] "" Vector__XXX
 SG_ APS_sw067_vehSpeed m67 : 44|12@1+ (0.1,-50) [0|0] "" Vector__XXX
 SG_ APS_sw071_airSuspension m71 : 44|3@1+ (1,0) [0|0] "" Vector__XXX
 SG_ APS_sw194_reasonForHold m194 : 44|4@1+ (1,0) [0|0] "" Vector__XXX
 SG_ APS_sw235_pmicApOffWaitUnrcvrble m235 : 44|1@1+ (1,0) [0|0] "" Vector__XXX
 SG_ APS_sw241_phy2WdqlvlReinitTrainingTimeout m241 : 44|1@1+ (1,0) [0|0] "" Vector__XXX
 SG_ APS_sw260_pgoodDdr1V25VrmRailFail m260 : 44|1@1+ (1,0) [0|0] "" Vector__XXX
 SG_ APS_sw268_wr_correctable_crc5 m268 : 44|1@1+ (1,0) [0|0] "" Vector__XXX
 SG_ APS_sw297_wdogMonTaskTotalCheckinMisses m297 : 44|7@1+ (1,0) [0|0] "" Vector__XXX
 SG_ APS_sw004_RadarMisalignment m4 : 45|1@1+ (1,0) [0|0] "" Vector__XXX
 SG_ APS_sw006_stabilityControl m6 : 45|1@1+ (1,0) [0|0] "" Vector__XXX
 SG_ APS_sw042_cam_PartialBlock m42 : 45|1@1+ (1,0) [0|0] "" Vector__XXX
 SG_ APS_sw053_a39whlSpdValidity m53 : 45|1@1+ (1,0) [0|0] "" Vector__XXX
 SG_ APS_sw231_targetRelAcceleration m231 : 45|8@1+ (0.1,-12.8) [0|0] "" Vector__XXX
 SG_ APS_sw235_resetBeingSent m235 : 45|1@1+ (1,0) [0|0] "" Vector__XXX
 SG_ APS_sw241_phy2WdqlvlPhaseMarginOutOfRange m241 : 45|1@1+ (1,0) [0|0] "" Vector__XXX
 SG_ APS_sw260_unknownSource m260 : 45|1@1+ (1,0) [0|0] "" Vector__XXX
 SG_ APS_sw268_vendorIdMismatchMIF5 m268 : 45|1@1+ (1,0) [0|0] "" Vector__XXX
 SG_ APS_sw004_OutOfFocusImage m4 : 46|1@1+ (1,0) [0|0] "" Vector__XXX
 SG_ APS_sw006_dasDisabled m6 : 46|1@1+ (1,0) [0|0] "" Vector__XXX
 SG_ APS_sw010_unusedBits m10 : 46|2@1+ (1,0) [0|0] "" Vector__XXX
 SG_ APS_sw015_SelfGlare m15 : 46|2@1+ (1,0) [0|0] "" Vector__XXX
 SG_ APS_sw041_unusedW2 m41 : 46|18@1+ (1,0) [0|0] "" Vector__XXX
 SG_ APS_sw042_cam_Autofix m42 : 46|1@1+ (1,0) [0|0] "" Vector__XXX
 SG_ APS_sw053_a40whlStndStllValidty m53 : 46|1@1+ (1,0) [0|0] "" Vector__XXX
 SG_ APS_sw069_drivingLaneLeft m69 : 46|8@1+ (1,0) [0|0] "" Vector__XXX
 SG_ APS_sw130_shouldForceApPowerOn m130 : 46|1@1+ (1,0) [0|0] "" Vector__XXX
 SG_ APS_sw235_udsResetBeingSent m235 : 46|1@1+ (1,0) [0|0] "" Vector__XXX
 SG_ APS_sw241_phy2WdqlvlReinitFailed m241 : 46|1@1+ (1,0) [0|0] "" Vector__XXX
 SG_ APS_sw268_rd_uncorrectable_crc6 m268 : 46|1@1+ (1,0) [0|0] "" Vector__XXX
 SG_ APS_sw004_ImpairedVD m4 : 47|1@1+ (1,0) [0|0] "" Vector__XXX
 SG_ APS_sw006_speedDerivative m6 : 47|1@1+ (1,0) [0|0] "" Vector__XXX
 SG_ APS_sw011_egoRightOfCenter m11 : 47|1@1+ (1,0) [0|0] "" Vector__XXX
 SG_ APS_sw018_railControl m18 : 47|1@1+ (1,0) [0|0] "" Vector__XXX
 SG_ APS_sw042_cam_AutofixHorizon m42 : 47|1@1+ (1,0) [0|0] "" Vector__XXX
 SG_ APS_sw053_a41wiperValidity m53 : 47|1@1+ (1,0) [0|0] "" Vector__XXX
 SG_ APS_sw060_hostLongAccel m60 : 47|4@1+ (1,-7.5) [0|0] "" Vector__XXX
 SG_ APS_sw085_averageSpeedHist m85 : 47|6@1+ (0.25,0) [0|0] "" Vector__XXX
 SG_ APS_sw130_shouldBlockOkToPowerAp m130 : 47|1@1+ (1,0) [0|0] "" Vector__XXX
 SG_ APS_sw235_smsWdtTimeout m235 : 47|1@1+ (1,0) [0|0] "" Vector__XXX
 SG_ APS_sw241_phy3TimeoutWaitingForInterrupts m241 : 47|1@1+ (1,0) [0|0] "" Vector__XXX
 SG_ APS_sw268_rd_correctable_crc6 m268 : 47|1@1+ (1,0) [0|0] "" Vector__XXX
 SG_ APS_sw001_APS_alertDataW2 m1 : 48|16@1+ (1,0) [0|0] "" Vector__XXX
 SG_ APS_sw004_SunRay m4 : 48|1@1+ (1,0) [0|0] "" Vector__XXX
 SG_ APS_sw006_camWatchdog m6 : 48|1@1+ (1,0) [0|0] "" Vector__XXX
 SG_ APS_sw010_VmaPlausibility m10 : 48|16@1+ (1.52587890625005e-05,0) [0|0] "" Vector__XXX
 SG_ APS_sw011_egoMovingRight m11 : 48|1@1+ (1,0) [0|0] "" Vector__XXX
 SG_ APS_sw013_highestSeqRecd m13 : 48|12@1+ (1,0) [0|0] "" Vector__XXX
 SG_ APS_sw014_assertData m14 : 48|16@1+ (1,0) [0|0] "" Vector__XXX
 SG_ APS_sw015_OutOfFocusImage m15 : 48|2@1+ (1,0) [0|0] "" Vector__XXX
 SG_ APS_sw016_hostLongAccel m16 : 48|7@1+ (0.15625,-10) [0|0] "" Vector__XXX
 SG_ APS_sw017_highestSeqRecd m17 : 48|12@1+ (1,0) [0|0] "" Vector__XXX
 SG_ APS_sw018_currentVoltage m18 : 48|16@1+ (1,0) [0|0] "" Vector__XXX
 SG_ APS_sw020_unusedW2 m20 : 48|16@1+ (1,0) [0|0] "" Vector__XXX
 SG_ APS_sw021_unusedWord m21 : 48|16@1+ (1,0) [0|0] "" Vector__XXX
 SG_ APS_sw025_torsionBarTorque m25 : 48|8@1+ (0.1,-12.8) [0|0] "" Vector__XXX
 SG_ APS_sw027_ESR0 m27 : 48|1@1+ (1,0) [0|0] "" Vector__XXX
 SG_ APS_sw028_multifrm_rx_len m28 : 48|16@1+ (1,0) [0|0] "" Vector__XXX
 SG_ APS_sw029_unusedW1 m29 : 48|16@1+ (1,0) [0|0] "" Vector__XXX
 SG_ APS_sw030_unusedW1 m30 : 48|16@1+ (1,0) [0|0] "" Vector__XXX
 SG_ APS_sw031_errorData2 m31 : 48|16@1+ (1,0) [0|0] "" Vector__XXX
 SG_ APS_sw032_errorData2 m32 : 48|16@1+ (1,0) [0|0] "" Vector__XXX
 SG_ APS_sw034_unusedW1 m34 : 48|16@1+ (1,0) [0|0] "" Vector__XXX
 SG_ APS_sw036_unusedW1 m36 : 48|16@1+ (1,0) [0|0] "" Vector__XXX
 SG_ APS_sw037_unusedW1 m37 : 48|16@1+ (1,0) [0|0] "" Vector__XXX
 SG_ APS_sw039_unusedW1 m39 : 48|16@1+ (1,0) [0|0] "" Vector__XXX
 SG_ APS_sw040_torsion_bar_torque m40 : 48|8@1+ (0.1,-12.8) [0|0] "" Vector__XXX
 SG_ APS_sw042_cam_AutofixYaw m42 : 48|1@1+ (1,0) [0|0] "" Vector__XXX
 SG_ APS_sw043_camLongRunTime_unused m43 : 48|16@1+ (1,0) [0|0] "" Vector__XXX
 SG_ APS_sw045_unusedW1 m45 : 48|16@1+ (1,0) [0|0] "" Vector__XXX
 SG_ APS_sw047_edrStateMachine m47 : 48|8@1+ (1,0) [0|0] "" Vector__XXX
 SG_ APS_sw049_ffs_version_msw m49 : 48|16@1+ (1,0) [0|0] "" Vector__XXX
 SG_ APS_sw050_hostLongAccel m50 : 48|7@1+ (0.15625,-10) [0|0] "" Vector__XXX
 SG_ APS_sw051_unusedW1 m51 : 48|16@1+ (1,0) [0|0] "" Vector__XXX
 SG_ APS_sw053_a42xwdValidity m53 : 48|1@1+ (1,0) [0|0] "" Vector__XXX
 SG_ APS_sw054_unusedW0 m54 : 48|16@1+ (1,0) [0|0] "" Vector__XXX
 SG_ APS_sw055_expectedCrcLsw m55 : 48|16@1+ (1,0) [0|0] "" Vector__XXX
 SG_ APS_sw056_unusedW1 m56 : 48|16@1+ (1,0) [0|0] "" Vector__XXX
 SG_ APS_sw058_unusedW1 m58 : 48|16@1+ (1,0) [0|0] "" Vector__XXX
 SG_ APS_sw062_VmaPlausibility m62 : 48|16@1+ (1.52587890625005e-05,0) [0|0] "" Vector__XXX
 SG_ APS_sw063_expectedSubMinorVer m63 : 48|8@1+ (1,0) [0|0] "" Vector__XXX
 SG_ APS_sw065_unusedW1 m65 : 48|16@1+ (1,0) [0|0] "" Vector__XXX
 SG_ APS_sw066_unusedW1 m66 : 48|16@1+ (1,0) [0|0] "" Vector__XXX
 SG_ APS_sw071_temperature m71 : 48|8@1+ (0.5,-40) [0|0] "" Vector__XXX
 SG_ APS_sw072_endDistance m72 : 48|8@1+ (1,0) [0|0] "" Vector__XXX
 SG_ APS_sw073_freespaceRightC1 m73 : 48|8@1+ (0.0016,-0.2) [0|0] "" Vector__XXX
 SG_ APS_sw074_ipsoConfidence m74 : 48|6@1+ (2,0) [0|0] "" Vector__XXX
 SG_ APS_sw075_unusedW1 m75 : 48|16@1+ (1,0) [0|0] "" Vector__XXX
 SG_ APS_sw076_hostLongAccel m76 : 48|7@1+ (0.15625,-10) [0|0] "" Vector__XXX
 SG_ APS_sw077_oocUntrackedTime m77 : 48|6@1+ (0.1,0) [0|0] "" Vector__XXX
 SG_ APS_sw078_radarTarg1_dx m78 : 48|8@1+ (0.0625,0) [0|0] "" Vector__XXX
 SG_ APS_sw080_cipv_valid m80 : 48|1@1+ (1,0) [0|0] "" Vector__XXX
 SG_ APS_sw081_pedalPosition m81 : 48|7@1+ (1,0) [0|0] "" Vector__XXX
 SG_ APS_sw082_road_class m82 : 48|3@1+ (1,0) [0|0] "" Vector__XXX
 SG_ APS_sw083_Targ5_dz m83 : 48|6@1+ (0.25,-5) [0|0] "" Vector__XXX
 SG_ APS_sw086_ellipseAge m86 : 48|3@1+ (1,0) [0|0] "" Vector__XXX
 SG_ APS_sw103_distanceEllipse m103 : 48|8@1+ (0.5,0) [0|0] "" Vector__XXX
 SG_ APS_sw131_trapClass m131 : 48|3@1+ (1,0) [0|0] "" Vector__XXX
 SG_ APS_sw132_expectedHash m132 : 48|16@1+ (1,0) [0|0] "" Vector__XXX
 SG_ APS_sw134_timeSinceLastMsg m134 : 48|16@1+ (1,0) [0|0] "" Vector__XXX
 SG_ APS_sw138_gpsSetCfgNoAck m138 : 48|1@1+ (1,0) [0|0] "" Vector__XXX
 SG_ APS_sw160_expectedHash m160 : 48|16@1+ (1,0) [0|0] "" Vector__XXX
 SG_ APS_sw194_timeInHold m194 : 48|16@1+ (1,0) [0|0] "" Vector__XXX
 SG_ APS_sw201_viewRangeOAL m201 : 48|3@1+ (1,0) [0|0] "" Vector__XXX
 SG_ APS_sw204_frRightMiddle m204 : 48|8@1+ (1,0) [0|0] "" Vector__XXX
 SG_ APS_sw205_rrRight m205 : 48|8@1+ (1,0) [0|0] "" Vector__XXX
 SG_ APS_sw235_smsCanApHealthTimeout m235 : 48|1@1+ (1,0) [0|0] "" Vector__XXX
 SG_ APS_sw241_phy3Ch0ReadGateOffsetBug m241 : 48|1@1+ (1,0) [0|0] "" Vector__XXX
 SG_ APS_sw245_unknownMACAddrByte4 m245 : 48|8@1+ (1,0) [0|0] "" Vector__XXX
 SG_ APS_sw257_assertArgument m257 : 48|16@1+ (1,0) [0|0] "" Vector__XXX
 SG_ APS_sw258_sectorNumber m258 : 48|4@1+ (1,0) [0|0] "" Vector__XXX
 SG_ APS_sw261_vrmRail3FaultValues m261 : 48|8@1+ (1,0) [0|0] "" Vector__XXX
 SG_ APS_sw262_vrmRail3FaultValues m262 : 48|8@1+ (1,0) [0|0] "" Vector__XXX
 SG_ APS_sw263_vrmType m263 : 48|3@1+ (1,0) [0|0] "" Vector__XXX
 SG_ APS_sw268_wr_uncorrectable_crc6 m268 : 48|1@1+ (1,0) [0|0] "" Vector__XXX
 SG_ APS_sw292_arbitrationPhaseErrorCount m292 : 48|8@1+ (1,0) [0|0] "" Vector__XXX
 SG_ APS_sw293_arbitrationPhaseErrorCount m293 : 48|8@1+ (1,0) [0|0] "" Vector__XXX
 SG_ APS_sw294_arbitrationPhaseErrorCount m294 : 48|8@1+ (1,0) [0|0] "" Vector__XXX
 SG_ APS_sw295_arbitrationPhaseErrorCount m295 : 48|8@1+ (1,0) [0|0] "" Vector__XXX
 SG_ APS_sw296_wdogMonTaskTotalCheckinMisses m296 : 48|7@1+ (1,0) [0|0] "" Vector__XXX
 SG_ APS_sw300_messageRingVersion m300 : 48|4@1+ (1,0) [0|0] "" Vector__XXX
 SG_ APS_sw313_arbitrationPhaseErrorCount m313 : 48|8@1+ (1,0) [0|0] "" Vector__XXX
 SG_ APS_sw004_Splashes m4 : 49|1@1+ (1,0) [0|0] "" Vector__XXX
 SG_ APS_sw006_camObjHeader m6 : 49|1@1+ (1,0) [0|0] "" Vector__XXX
 SG_ APS_sw011_egoLeftOfCenter m11 : 49|1@1+ (1,0) [0|0] "" Vector__XXX
 SG_ APS_sw027_ESR1 m27 : 49|1@1+ (1,0) [0|0] "" Vector__XXX
 SG_ APS_sw042_cam_FullBlock m42 : 49|1@1+ (1,0) [0|0] "" Vector__XXX
 SG_ APS_sw053_a43yawOffValidity m53 : 49|1@1+ (1,0) [0|0] "" Vector__XXX
 SG_ APS_sw080_min_speed_check m80 : 49|1@1+ (1,0) [0|0] "" Vector__XXX
 SG_ APS_sw138_gpsReadCfgNoResponse m138 : 49|1@1+ (1,0) [0|0] "" Vector__XXX
 SG_ APS_sw199_internalState m199 : 49|4@1+ (1,0) [0|0] "" Vector__XXX
 SG_ APS_sw235_smsTaskWdtTimeout m235 : 49|1@1+ (1,0) [0|0] "" Vector__XXX
 SG_ APS_sw241_phy3Ch1ReadGateOffsetBug m241 : 49|1@1+ (1,0) [0|0] "" Vector__XXX
 SG_ APS_sw268_wr_correctable_crc6 m268 : 49|1@1+ (1,0) [0|0] "" Vector__XXX
 SG_ APS_sw004_BlurredImage m4 : 50|1@1+ (1,0) [0|0] "" Vector__XXX
 SG_ APS_sw006_camCommonMsg m6 : 50|1@1+ (1,0) [0|0] "" Vector__XXX
 SG_ APS_sw011_egoMovingLeft m11 : 50|1@1+ (1,0) [0|0] "" Vector__XXX
 SG_ APS_sw012_mespDDRTempStatus m12 : 50|3@1+ (1,0) [0|0] "" Vector__XXX
 SG_ APS_sw015_MainCameraLowLight m15 : 50|2@1+ (1,0) [0|0] "" Vector__XXX
 SG_ APS_sw026_mob_mean_utilization m26 : 50|7@1+ (1,0) [0|0] "" Vector__XXX
 SG_ APS_sw027_SW m27 : 50|1@1+ (1,0) [0|0] "" Vector__XXX
 SG_ APS_sw042_cam_SmearedHalos m42 : 50|1@1+ (1,0) [0|0] "" Vector__XXX
 SG_ APS_sw053_a44yawValidity m53 : 50|1@1+ (1,0) [0|0] "" Vector__XXX
 SG_ APS_sw080_cruise_lever_state m80 : 50|3@1+ (1,0) [0|0] "" Vector__XXX
 SG_ APS_sw138_ubxErrorReported m138 : 50|1@1+ (1,0) [0|0] "" Vector__XXX
 SG_ APS_sw241_phy3RdlvlReinitTrainingTimeout m241 : 50|1@1+ (1,0) [0|0] "" Vector__XXX
 SG_ APS_sw268_vendorIdMismatchMIF6 m268 : 50|1@1+ (1,0) [0|0] "" Vector__XXX
 SG_ APS_sw004_LowSun m4 : 51|1@1+ (1,0) [0|0] "" Vector__XXX
 SG_ APS_sw006_camFcwPcwMsg m6 : 51|1@1+ (1,0) [0|0] "" Vector__XXX
 SG_ APS_sw011_polyValid m11 : 51|1@1+ (1,0) [0|0] "" Vector__XXX
 SG_ APS_sw027_STM0 m27 : 51|1@1+ (1,0) [0|0] "" Vector__XXX
 SG_ APS_sw042_cam_FoggySpots m42 : 51|1@1+ (1,0) [0|0] "" Vector__XXX
 SG_ APS_sw053_a48steerAngOffSanity m53 : 51|1@1+ (1,0) [0|0] "" Vector__XXX
 SG_ APS_sw060_RadarAssociationAge m60 : 51|4@1+ (100,0) [0|0] "" Vector__XXX
 SG_ APS_sw086_activeBraking m86 : 51|1@1+ (1,0) [0|0] "" Vector__XXX
 SG_ APS_sw131_trapTIN m131 : 51|3@1+ (1,0) [0|0] "" Vector__XXX
 SG_ APS_sw241_phy3RdlvlReinitFailed m241 : 51|1@1+ (1,0) [0|0] "" Vector__XXX
 SG_ APS_sw268_rd_uncorrectable_crc7 m268 : 51|1@1+ (1,0) [0|0] "" Vector__XXX
 SG_ APS_sw297_wdogMonTaskMaxRecoveryInterval m297 : 51|11@1+ (1,0) [0|0] "" Vector__XXX
 SG_ APS_sw004_SmearedSpots m4 : 52|1@1+ (1,0) [0|0] "" Vector__XXX
 SG_ APS_sw006_longAccel m6 : 52|1@1+ (1,0) [0|0] "" Vector__XXX
 SG_ APS_sw011_egoCentered m11 : 52|1@1+ (1,0) [0|0] "" Vector__XXX
 SG_ APS_sw015_NarrowCameraLowLight m15 : 52|2@1+ (1,0) [0|0] "" Vector__XXX
 SG_ APS_sw027_STM1 m27 : 52|1@1+ (1,0) [0|0] "" Vector__XXX
 SG_ APS_sw042_cam_SelfGlare m42 : 52|1@1+ (1,0) [0|0] "" Vector__XXX
 SG_ APS_sw053_a49tireSizeSanity m53 : 52|1@1+ (1,0) [0|0] "" Vector__XXX
 SG_ APS_sw203_vehicleSkew m203 : 52|12@1+ (0.002,0) [0|0] "" Vector__XXX
 SG_ APS_sw241_phy3WdqlvlReinitTrainingTimeout m241 : 52|1@1+ (1,0) [0|0] "" Vector__XXX
 SG_ APS_sw258_flashReadError m258 : 52|1@1+ (1,0) [0|0] "" Vector__XXX
 SG_ APS_sw268_rd_correctable_crc7 m268 : 52|1@1+ (1,0) [0|0] "" Vector__XXX
 SG_ APS_sw269_RxPageCountPort3 m269 : 52|12@1+ (1,0) [0|0] "" Vector__XXX
 SG_ APS_sw270_RxPageCountPort7 m270 : 52|12@1+ (1,0) [0|0] "" Vector__XXX
 SG_ APS_sw300_canApShmAccessErrorCount m300 : 52|8@1+ (1,0) [0|0] "" Vector__XXX
 SG_ APS_sw004_PartialBlockage m4 : 53|1@1+ (1,0) [0|0] "" Vector__XXX
 SG_ APS_sw006_yawRate m6 : 53|1@1+ (1,0) [0|0] "" Vector__XXX
 SG_ APS_sw011_scaReasonEldw m11 : 53|1@1+ (1,0) [0|0] "" Vector__XXX
 SG_ APS_sw012_freescaleTemp m12 : 53|8@1- (1,0) [0|0] "" Vector__XXX
 SG_ APS_sw027_STM2 m27 : 53|1@1+ (1,0) [0|0] "" Vector__XXX
 SG_ APS_sw042_cam_OutofFocus m42 : 53|1@1+ (1,0) [0|0] "" Vector__XXX
 SG_ APS_sw053_a50velocitySanity m53 : 53|1@1+ (1,0) [0|0] "" Vector__XXX
 SG_ APS_sw080_cruise_speed_check m80 : 53|1@1+ (1,0) [0|0] "" Vector__XXX
 SG_ APS_sw085_freeSpaceC0Left m85 : 53|5@1+ (1,-15) [0|0] "" Vector__XXX
 SG_ APS_sw199_maxSpeed m199 : 53|7@1+ (0.2,-12.2) [0|0] "" Vector__XXX
 SG_ APS_sw231_targetIsACar m231 : 53|1@1+ (1,0) [0|0] "" Vector__XXX
 SG_ APS_sw241_phy3WdqlvlPhaseMarginOutOfRange m241 : 53|1@1+ (1,0) [0|0] "" Vector__XXX
 SG_ APS_sw268_wr_uncorrectable_crc7 m268 : 53|1@1+ (1,0) [0|0] "" Vector__XXX
 SG_ APS_sw004_AutofixOutOfCalib m4 : 54|1@1+ (1,0) [0|0] "" Vector__XXX
 SG_ APS_sw006_DIaebState_SNA m6 : 54|1@1+ (1,0) [0|0] "" Vector__XXX
 SG_ APS_sw015_MainCameraBadAssoc m15 : 54|2@1+ (1,0) [0|0] "" Vector__XXX
 SG_ APS_sw027_CBS_SYSTEM m27 : 54|1@1+ (1,0) [0|0] "" Vector__XXX
 SG_ APS_sw042_road_match m42 : 54|1@1+ (1,0) [0|0] "" Vector__XXX
 SG_ APS_sw053_a51yawSanity m53 : 54|1@1+ (1,0) [0|0] "" Vector__XXX
 SG_ APS_sw069_drivingLaneRight m69 : 54|8@1+ (1,0) [0|0] "" Vector__XXX
 SG_ APS_sw074_ipsowExist m74 : 54|5@1+ (1,0) [0|0] "" Vector__XXX
 SG_ APS_sw077_oocOffCourseDist_cm m77 : 54|10@1- (1,0) [0|0] "" Vector__XXX
 SG_ APS_sw083_Targ5_wObj m83 : 54|5@1+ (0.03125,0) [0|0] "" Vector__XXX
 SG_ APS_sw231_egoVehicleSpeed m231 : 54|5@1+ (5,0) [0|0] "" Vector__XXX
 SG_ APS_sw241_phy3WdqlvlReinitFailed m241 : 54|1@1+ (1,0) [0|0] "" Vector__XXX
 SG_ APS_sw268_wr_correctable_crc7 m268 : 54|1@1+ (1,0) [0|0] "" Vector__XXX
 SG_ APS_sw004_AutofixOutOfCalibHorzn m4 : 55|1@1+ (1,0) [0|0] "" Vector__XXX
 SG_ APS_sw006_DIaebStateUnavailable m6 : 55|1@1+ (1,0) [0|0] "" Vector__XXX
 SG_ APS_sw016_driverPressedAccelPed m16 : 55|1@1+ (1,0) [0|0] "" Vector__XXX
 SG_ APS_sw027_CBS_DEBUG m27 : 55|1@1+ (1,0) [0|0] "" Vector__XXX
 SG_ APS_sw042_controlled_access m42 : 55|1@1+ (1,0) [0|0] "" Vector__XXX
 SG_ APS_sw050_driverPressedAccelPed m50 : 55|1@1+ (1,0) [0|0] "" Vector__XXX
 SG_ APS_sw053_a53espmodValidity m53 : 55|1@1+ (1,0) [0|0] "" Vector__XXX
 SG_ APS_sw060_driverPressedBrakePed m60 : 55|1@1+ (1,0) [0|0] "" Vector__XXX
 SG_ APS_sw076_driverPressedAccelPed m76 : 55|1@1+ (1,0) [0|0] "" Vector__XXX
 SG_ APS_sw268_vendorIdMismatchMIF7 m268 : 55|1@1+ (1,0) [0|0] "" Vector__XXX
 SG_ APS_sw004_AutofixOutOfCalibYaw m4 : 56|1@1+ (1,0) [0|0] "" Vector__XXX
 SG_ APS_sw006_brakeLights m6 : 56|1@1+ (1,0) [0|0] "" Vector__XXX
 SG_ APS_sw011_laneWidth m11 : 56|8@1+ (0.025,0) [0|0] "" Vector__XXX
 SG_ APS_sw015_NarrowCameraBadAssoc m15 : 56|2@1+ (1,0) [0|0] "" Vector__XXX
 SG_ APS_sw016_driverPressedBrakePed m16 : 56|1@1+ (1,0) [0|0] "" Vector__XXX
 SG_ APS_sw027_CBS_APP m27 : 56|1@1+ (1,0) [0|0] "" Vector__XXX
 SG_ APS_sw040_view_range m40 : 56|8@1+ (1,0) [0|0] "" Vector__XXX
 SG_ APS_sw042_road_class m42 : 56|3@1+ (1,0) [0|0] "" Vector__XXX
 SG_ APS_sw047_edrLoggerBuffer m47 : 56|2@1+ (1,0) [0|0] "" Vector__XXX
 SG_ APS_sw050_driverPressedBrakePed m50 : 56|1@1+ (1,0) [0|0] "" Vector__XXX
 SG_ APS_sw053_a54gtwmodValidity m53 : 56|1@1+ (1,0) [0|0] "" Vector__XXX
 SG_ APS_sw060_overrideAccelPed m60 : 56|1@1+ (1,0) [0|0] "" Vector__XXX
 SG_ APS_sw063_detectedSubMinorVer m63 : 56|8@1+ (1,0) [0|0] "" Vector__XXX
 SG_ APS_sw067_offsetEstimator m67 : 56|8@1+ (0.1,-12.8) [0|0] "" Vector__XXX
 SG_ APS_sw071_activationType m71 : 56|2@1+ (1,0) [0|0] "" Vector__XXX
 SG_ APS_sw072_guidanceComplete m72 : 56|1@1+ (1,0) [0|0] "" Vector__XXX
 SG_ APS_sw073_freespaceLeftFarZ m73 : 56|4@1+ (4,0) [0|0] "" Vector__XXX
 SG_ APS_sw076_driverPressedBrakePed m76 : 56|1@1+ (1,0) [0|0] "" Vector__XXX
 SG_ APS_sw078_radarTarg1_VxRel m78 : 56|8@1+ (0.2,-25.6) [0|0] "" Vector__XXX
 SG_ APS_sw103_ipsoApproved m103 : 56|1@1+ (1,0) [0|0] "" Vector__XXX
 SG_ APS_sw129_powerSequnceError m129 : 56|1@1+ (1,0) [0|0] "" Vector__XXX
 SG_ APS_sw131_trapTaskPrio m131 : 56|8@1+ (1,0) [0|0] "" Vector__XXX
 SG_ APS_sw204_maxSpeed m204 : 56|8@1+ (0.1,-12.2) [0|0] "" Vector__XXX
 SG_ APS_sw205_rrRightMiddle m205 : 56|8@1+ (1,0) [0|0] "" Vector__XXX
 SG_ APS_sw245_unknownMACAddrByte5 m245 : 56|8@1+ (1,0) [0|0] "" Vector__XXX
 SG_ APS_sw261_vrmType m261 : 56|3@1+ (1,0) [0|0] "" Vector__XXX
 SG_ APS_sw262_vrmType m262 : 56|3@1+ (1,0) [0|0] "" Vector__XXX
 SG_ APS_sw292_dataPhaseErrorCount m292 : 56|8@1+ (1,0) [0|0] "" Vector__XXX
 SG_ APS_sw293_dataPhaseErrorCount m293 : 56|8@1+ (1,0) [0|0] "" Vector__XXX
 SG_ APS_sw294_dataPhaseErrorCount m294 : 56|8@1+ (1,0) [0|0] "" Vector__XXX
 SG_ APS_sw295_dataPhaseErrorCount m295 : 56|8@1+ (1,0) [0|0] "" Vector__XXX
 SG_ APS_sw313_dataPhaseErrorCount m313 : 56|8@1+ (1,0) [0|0] "" Vector__XXX
 SG_ APS_sw004_FullBlockage m4 : 57|1@1+ (1,0) [0|0] "" Vector__XXX
 SG_ APS_sw006_trailerMode m6 : 57|1@1+ (1,0) [0|0] "" Vector__XXX
 SG_ APS_sw016_overrideAccelPed m16 : 57|1@1+ (1,0) [0|0] "" Vector__XXX
 SG_ APS_sw026_veh_mean_utilization m26 : 57|7@1+ (1,0) [0|0] "" Vector__XXX
 SG_ APS_sw027_EVR13 m27 : 57|1@1+ (1,0) [0|0] "" Vector__XXX
 SG_ APS_sw050_overrideAccelPed m50 : 57|1@1+ (1,0) [0|0] "" Vector__XXX
 SG_ APS_sw053_a55stwmodValidity m53 : 57|1@1+ (1,0) [0|0] "" Vector__XXX
 SG_ APS_sw060_overrideBlinker m60 : 57|1@1+ (1,0) [0|0] "" Vector__XXX
 SG_ APS_sw072_guidanceRunaway m72 : 57|1@1+ (1,0) [0|0] "" Vector__XXX
 SG_ APS_sw076_overrideAccelPed m76 : 57|1@1+ (1,0) [0|0] "" Vector__XXX
 SG_ APS_sw103_constArea m103 : 57|2@1+ (1,0) [0|0] "" Vector__XXX
 SG_ APS_sw129_railControl m129 : 57|1@1+ (1,0) [0|0] "" Vector__XXX
 SG_ APS_sw004_SmearedHalos m4 : 58|1@1+ (1,0) [0|0] "" Vector__XXX
 SG_ APS_sw006_timeOfDay m6 : 58|2@1+ (1,0) [0|0] "" Vector__XXX
 SG_ APS_sw016_overrideBlinker m16 : 58|1@1+ (1,0) [0|0] "" Vector__XXX
 SG_ APS_sw027_EVR33 m27 : 58|1@1+ (1,0) [0|0] "" Vector__XXX
 SG_ APS_sw047_unused m47 : 58|6@1+ (1,0) [0|0] "" Vector__XXX
 SG_ APS_sw050_overrideBlinker m50 : 58|1@1+ (1,0) [0|0] "" Vector__XXX
 SG_ APS_sw053_a56bcmodValidity m53 : 58|1@1+ (1,0) [0|0] "" Vector__XXX
 SG_ APS_sw060_overrideBrake m60 : 58|1@1+ (1,0) [0|0] "" Vector__XXX
 SG_ APS_sw072_guidanceTimer m72 : 58|1@1+ (1,0) [0|0] "" Vector__XXX
 SG_ APS_sw076_overrideBlinker m76 : 58|1@1+ (1,0) [0|0] "" Vector__XXX
 SG_ APS_sw085_freeSpaceC0Right m85 : 58|5@1+ (1,-15) [0|0] "" Vector__XXX
 SG_ APS_sw129_railID m129 : 58|6@1+ (1,0) [0|0] "" Vector__XXX
 SG_ APS_sw004_FoggyLights m4 : 59|1@1+ (1,0) [0|0] "" Vector__XXX
 SG_ APS_sw016_overrideBrake m16 : 59|1@1+ (1,0) [0|0] "" Vector__XXX
 SG_ APS_sw027_SWD m27 : 59|1@1+ (1,0) [0|0] "" Vector__XXX
 SG_ APS_sw050_overrideBrake m50 : 59|1@1+ (1,0) [0|0] "" Vector__XXX
 SG_ APS_sw053_a57dimodValidity m53 : 59|1@1+ (1,0) [0|0] "" Vector__XXX
 SG_ APS_sw060_overrideSteer m60 : 59|1@1+ (1,0) [0|0] "" Vector__XXX
 SG_ APS_sw072_handlePress m72 : 59|1@1+ (1,0) [0|0] "" Vector__XXX
 SG_ APS_sw074_roadClass m74 : 59|3@1+ (1,0) [0|0] "" Vector__XXX
 SG_ APS_sw076_overrideBrake m76 : 59|1@1+ (1,0) [0|0] "" Vector__XXX
 SG_ APS_sw083_Targ5_wNonObj m83 : 59|5@1+ (0.03125,0) [0|0] "" Vector__XXX
 SG_ APS_sw103_radAlignment m103 : 59|5@1+ (0.015625,-0.2343) [0|0] "" Vector__XXX
 SG_ APS_sw231_steeringOverride m231 : 59|1@1+ (1,0) [0|0] "" Vector__XXX
 SG_ APS_sw004_SelfGlare m4 : 60|1@1+ (1,0) [0|0] "" Vector__XXX
 SG_ APS_sw013_numTransportErrors m13 : 60|4@1+ (1,0) [0|0] "" Vector__XXX
 SG_ APS_sw016_overrideSteer m16 : 60|1@1+ (1,0) [0|0] "" Vector__XXX
 SG_ APS_sw017_Any_Tsr_Msg_Recd m17 : 60|1@1+ (1,0) [0|0] "" Vector__XXX
 SG_ APS_sw027_STDBY_WDG m27 : 60|1@1+ (1,0) [0|0] "" Vector__XXX
 SG_ APS_sw050_overrideSteer m50 : 60|1@1+ (1,0) [0|0] "" Vector__XXX
 SG_ APS_sw053_a59drmiInvalidChkSm m53 : 60|1@1+ (1,0) [0|0] "" Vector__XXX
 SG_ APS_sw060_collisionWarningSource m60 : 60|3@1+ (1,0) [0|0] "" Vector__XXX
 SG_ APS_sw072_keyfobPress m72 : 60|1@1+ (1,0) [0|0] "" Vector__XXX
 SG_ APS_sw073_freespaceRightFarZ m73 : 60|4@1+ (4,0) [0|0] "" Vector__XXX
 SG_ APS_sw076_overrideSteer m76 : 60|1@1+ (1,0) [0|0] "" Vector__XXX
 SG_ APS_sw199_numShifts m199 : 60|4@1+ (1,0) [0|0] "" Vector__XXX
 SG_ APS_sw231_predOverlap m231 : 60|4@1+ (10,0) [0|0] "" Vector__XXX
 SG_ APS_sw300_canApShmAccessErrorDirection m300 : 60|2@1+ (1,0) [0|0] "" Vector__XXX
 SG_ APS_sw004_visionNotRunning m4 : 61|1@1+ (1,0) [0|0] "" Vector__XXX
 SG_ APS_sw016_fcmModeAtEvent m16 : 61|2@1+ (1,0) [0|0] "" Vector__XXX
 SG_ APS_sw017_Any_Hlb_Msg_Recd m17 : 61|1@1+ (1,0) [0|0] "" Vector__XXX
 SG_ APS_sw027_PORST m27 : 61|1@1+ (1,0) [0|0] "" Vector__XXX
 SG_ APS_sw050_fcmModeAtEvent m50 : 61|2@1+ (1,0) [0|0] "" Vector__XXX
 SG_ APS_sw053_a60drmiInvalidCount m53 : 61|1@1+ (1,0) [0|0] "" Vector__XXX
 SG_ APS_sw072_garageOpened m72 : 61|1@1+ (1,0) [0|0] "" Vector__XXX
 SG_ APS_sw076_fcmModeAtEvent m76 : 61|2@1+ (1,0) [0|0] "" Vector__XXX
 SG_ APS_sw017_Any_Common_Msg_Recd m17 : 62|1@1+ (1,0) [0|0] "" Vector__XXX
 SG_ APS_sw027_Unused_word m27 : 62|2@1+ (1,0) [0|0] "" Vector__XXX
 SG_ APS_sw053_a61radPositionMismatch m53 : 62|1@1+ (1,0) [0|0] "" Vector__XXX
 SG_ APS_sw072_userTimeout m72 : 62|1@1+ (1,0) [0|0] "" Vector__XXX
 SG_ APS_sw074_cruiseActive m74 : 62|1@1+ (1,0) [0|0] "" Vector__XXX
 SG_ APS_sw016_accActive m16 : 63|1@1+ (1,0) [0|0] "" Vector__XXX
 SG_ APS_sw017_Any_FCW_PCW_Msg_Recd m17 : 63|1@1+ (1,0) [0|0] "" Vector__XXX
 SG_ APS_sw050_accActive m50 : 63|1@1+ (1,0) [0|0] "" Vector__XXX
 SG_ APS_sw053_a62strRackMismatch m53 : 63|1@1+ (1,0) [0|0] "" Vector__XXX
 SG_ APS_sw060_accActive m60 : 63|1@1+ (1,0) [0|0] "" Vector__XXX
 SG_ APS_sw074_autopilotActive m74 : 63|1@1+ (1,0) [0|0] "" Vector__XXX
 SG_ APS_sw076_accActive m76 : 63|1@1+ (1,0) [0|0] "" Vector__XXX

BO_ 1486 PARK_alertLog: 8 Vector__XXX
 SG_ PARK_alertID M : 0|7@1+ (1,0) [0|0] "" Vector__XXX
 SG_ PARK_alertState : 15|1@1+ (1,0) [0|0] "" Vector__XXX
 SG_ PARK_sw001_sensorTemperature m1 : 16|16@1+ (0.1,-40) [0|0] "" Vector__XXX
 SG_ PARK_sw002_membraneDisconct m2 : 16|1@1+ (1,0) [0|0] "" Vector__XXX
 SG_ PARK_sw003_linError m3 : 16|1@1+ (1,0) [0|0] "" Vector__XXX
 SG_ PARK_sw004_reverbPeriod m4 : 16|16@1+ (1,0) [0|0] "" Vector__XXX
 SG_ PARK_sw005_placeHolder m5 : 16|1@1+ (1,0) [0|0] "" Vector__XXX
 SG_ PARK_sw006_sensorTemperature m6 : 16|16@1+ (0.1,-40) [0|0] "" Vector__XXX
 SG_ PARK_sw007_membraneDisconct m7 : 16|1@1+ (1,0) [0|0] "" Vector__XXX
 SG_ PARK_sw008_linError m8 : 16|1@1+ (1,0) [0|0] "" Vector__XXX
 SG_ PARK_sw009_reverbPeriod m9 : 16|16@1+ (1,0) [0|0] "" Vector__XXX
 SG_ PARK_sw010_placeHolder m10 : 16|1@1+ (1,0) [0|0] "" Vector__XXX
 SG_ PARK_sw011_sensorTemperature m11 : 16|16@1+ (0.1,-40) [0|0] "" Vector__XXX
 SG_ PARK_sw012_membraneDisconct m12 : 16|1@1+ (1,0) [0|0] "" Vector__XXX
 SG_ PARK_sw013_linError m13 : 16|1@1+ (1,0) [0|0] "" Vector__XXX
 SG_ PARK_sw014_reverbPeriod m14 : 16|16@1+ (1,0) [0|0] "" Vector__XXX
 SG_ PARK_sw015_placeHolder m15 : 16|1@1+ (1,0) [0|0] "" Vector__XXX
 SG_ PARK_sw016_sensorTemperature m16 : 16|16@1+ (0.1,-40) [0|0] "" Vector__XXX
 SG_ PARK_sw017_membraneDisconct m17 : 16|1@1+ (1,0) [0|0] "" Vector__XXX
 SG_ PARK_sw018_linError m18 : 16|1@1+ (1,0) [0|0] "" Vector__XXX
 SG_ PARK_sw019_reverbPeriod m19 : 16|16@1+ (1,0) [0|0] "" Vector__XXX
 SG_ PARK_sw020_placeHolder m20 : 16|1@1+ (1,0) [0|0] "" Vector__XXX
 SG_ PARK_sw021_sensorTemperature m21 : 16|16@1+ (0.1,-40) [0|0] "" Vector__XXX
 SG_ PARK_sw022_membraneDisconct m22 : 16|1@1+ (1,0) [0|0] "" Vector__XXX
 SG_ PARK_sw023_linError m23 : 16|1@1+ (1,0) [0|0] "" Vector__XXX
 SG_ PARK_sw024_reverbPeriod m24 : 16|16@1+ (1,0) [0|0] "" Vector__XXX
 SG_ PARK_sw025_placeHolder m25 : 16|1@1+ (1,0) [0|0] "" Vector__XXX
 SG_ PARK_sw026_sensorTemperature m26 : 16|16@1+ (0.1,-40) [0|0] "" Vector__XXX
 SG_ PARK_sw027_membraneDisconct m27 : 16|1@1+ (1,0) [0|0] "" Vector__XXX
 SG_ PARK_sw028_linError m28 : 16|1@1+ (1,0) [0|0] "" Vector__XXX
 SG_ PARK_sw029_reverbPeriod m29 : 16|16@1+ (1,0) [0|0] "" Vector__XXX
 SG_ PARK_sw030_placeHolder m30 : 16|1@1+ (1,0) [0|0] "" Vector__XXX
 SG_ PARK_sw031_sensorTemperature m31 : 16|16@1+ (0.1,-40) [0|0] "" Vector__XXX
 SG_ PARK_sw032_membraneDisconct m32 : 16|1@1+ (1,0) [0|0] "" Vector__XXX
 SG_ PARK_sw033_linError m33 : 16|1@1+ (1,0) [0|0] "" Vector__XXX
 SG_ PARK_sw034_reverbPeriod m34 : 16|16@1+ (1,0) [0|0] "" Vector__XXX
 SG_ PARK_sw035_placeHolder m35 : 16|1@1+ (1,0) [0|0] "" Vector__XXX
 SG_ PARK_sw036_sensorTemperature m36 : 16|16@1+ (0.1,-40) [0|0] "" Vector__XXX
 SG_ PARK_sw037_membraneDisconct m37 : 16|1@1+ (1,0) [0|0] "" Vector__XXX
 SG_ PARK_sw038_linError m38 : 16|1@1+ (1,0) [0|0] "" Vector__XXX
 SG_ PARK_sw039_reverbPeriod m39 : 16|16@1+ (1,0) [0|0] "" Vector__XXX
 SG_ PARK_sw040_placeHolder m40 : 16|1@1+ (1,0) [0|0] "" Vector__XXX
 SG_ PARK_sw041_sensorTemperature m41 : 16|16@1+ (0.1,-40) [0|0] "" Vector__XXX
 SG_ PARK_sw042_membraneDisconct m42 : 16|1@1+ (1,0) [0|0] "" Vector__XXX
 SG_ PARK_sw043_linError m43 : 16|1@1+ (1,0) [0|0] "" Vector__XXX
 SG_ PARK_sw044_reverbPeriod m44 : 16|16@1+ (1,0) [0|0] "" Vector__XXX
 SG_ PARK_sw045_placeHolder m45 : 16|1@1+ (1,0) [0|0] "" Vector__XXX
 SG_ PARK_sw046_sensorTemperature m46 : 16|16@1+ (0.1,-40) [0|0] "" Vector__XXX
 SG_ PARK_sw047_membraneDisconct m47 : 16|1@1+ (1,0) [0|0] "" Vector__XXX
 SG_ PARK_sw048_linError m48 : 16|1@1+ (1,0) [0|0] "" Vector__XXX
 SG_ PARK_sw049_reverbPeriod m49 : 16|16@1+ (1,0) [0|0] "" Vector__XXX
 SG_ PARK_sw050_placeHolder m50 : 16|1@1+ (1,0) [0|0] "" Vector__XXX
 SG_ PARK_sw051_sensorTemperature m51 : 16|16@1+ (0.1,-40) [0|0] "" Vector__XXX
 SG_ PARK_sw052_membraneDisconct m52 : 16|1@1+ (1,0) [0|0] "" Vector__XXX
 SG_ PARK_sw053_linError m53 : 16|1@1+ (1,0) [0|0] "" Vector__XXX
 SG_ PARK_sw054_reverbPeriod m54 : 16|16@1+ (1,0) [0|0] "" Vector__XXX
 SG_ PARK_sw055_placeHolder m55 : 16|1@1+ (1,0) [0|0] "" Vector__XXX
 SG_ PARK_sw056_sensorTemperature m56 : 16|16@1+ (0.1,-40) [0|0] "" Vector__XXX
 SG_ PARK_sw057_membraneDisconct m57 : 16|1@1+ (1,0) [0|0] "" Vector__XXX
 SG_ PARK_sw058_linError m58 : 16|1@1+ (1,0) [0|0] "" Vector__XXX
 SG_ PARK_sw059_reverbPeriod m59 : 16|16@1+ (1,0) [0|0] "" Vector__XXX
 SG_ PARK_sw060_placeHolder m60 : 16|1@1+ (1,0) [0|0] "" Vector__XXX
 SG_ PARK_sw061_voltage m61 : 16|16@1+ (0.1,0) [0|0] "" Vector__XXX
 SG_ PARK_sw062_voltage m62 : 16|16@1+ (0.1,0) [0|0] "" Vector__XXX
 SG_ PARK_sw063_voltage m63 : 16|16@1+ (0.1,0) [0|0] "" Vector__XXX
 SG_ PARK_sw064_faultCode m64 : 16|8@1+ (1,0) [0|0] "" Vector__XXX
 SG_ PARK_sw065_expectedCRC m65 : 16|16@1+ (1,0) [0|0] "" Vector__XXX
 SG_ PARK_sw066_placeHolder m66 : 16|1@1+ (1,0) [0|0] "" Vector__XXX
 SG_ PARK_sw067_placeHolder m67 : 16|1@1+ (1,0) [0|0] "" Vector__XXX
 SG_ PARK_sw068_placeHolder m68 : 16|1@1+ (1,0) [0|0] "" Vector__XXX
 SG_ PARK_sw069_messageID m69 : 16|16@1+ (1,0) [0|0] "" Vector__XXX
 SG_ PARK_sw070_messageID m70 : 16|16@1+ (1,0) [0|0] "" Vector__XXX
 SG_ PARK_sw071_messageID m71 : 16|16@1+ (1,0) [0|0] "" Vector__XXX
 SG_ PARK_sw072_messageID m72 : 16|16@1+ (1,0) [0|0] "" Vector__XXX
 SG_ PARK_sw073_messageID m73 : 16|16@1+ (1,0) [0|0] "" Vector__XXX
 SG_ PARK_sw074_messageID m74 : 16|16@1+ (1,0) [0|0] "" Vector__XXX
 SG_ PARK_sw075_messageID m75 : 16|16@1+ (1,0) [0|0] "" Vector__XXX
 SG_ PARK_sw076_messageID m76 : 16|16@1+ (1,0) [0|0] "" Vector__XXX
 SG_ PARK_sw077_errorExp m77 : 16|8@1+ (1,0) [0|0] "" Vector__XXX
 SG_ PARK_sw078_errorExp m78 : 16|8@1+ (1,0) [0|0] "" Vector__XXX
 SG_ PARK_sw079_errorExp m79 : 16|8@1+ (1,0) [0|0] "" Vector__XXX
 SG_ PARK_sw080_errorExp m80 : 16|8@1+ (1,0) [0|0] "" Vector__XXX
 SG_ PARK_sw081_errorExp m81 : 16|8@1+ (1,0) [0|0] "" Vector__XXX
 SG_ PARK_sw082_errorExp m82 : 16|8@1+ (1,0) [0|0] "" Vector__XXX
 SG_ PARK_sw083_errorExp m83 : 16|8@1+ (1,0) [0|0] "" Vector__XXX
 SG_ PARK_sw084_errorExp m84 : 16|8@1+ (1,0) [0|0] "" Vector__XXX
 SG_ PARK_sw086_writeRetryCounter m86 : 16|8@1+ (1,0) [0|0] "" Vector__XXX
 SG_ PARK_sw087_s1_sensorType m87 : 16|2@1+ (1,0) [0|0] "" Vector__XXX
 SG_ PARK_sw002_dampResistorFail m2 : 17|1@1+ (1,0) [0|0] "" Vector__XXX
 SG_ PARK_sw003_linBusError m3 : 17|1@1+ (1,0) [0|0] "" Vector__XXX
 SG_ PARK_sw007_dampResistorFail m7 : 17|1@1+ (1,0) [0|0] "" Vector__XXX
 SG_ PARK_sw008_linBusError m8 : 17|1@1+ (1,0) [0|0] "" Vector__XXX
 SG_ PARK_sw012_dampResistorFail m12 : 17|1@1+ (1,0) [0|0] "" Vector__XXX
 SG_ PARK_sw013_linBusError m13 : 17|1@1+ (1,0) [0|0] "" Vector__XXX
 SG_ PARK_sw017_dampResistorFail m17 : 17|1@1+ (1,0) [0|0] "" Vector__XXX
 SG_ PARK_sw018_linBusError m18 : 17|1@1+ (1,0) [0|0] "" Vector__XXX
 SG_ PARK_sw022_dampResistorFail m22 : 17|1@1+ (1,0) [0|0] "" Vector__XXX
 SG_ PARK_sw023_linBusError m23 : 17|1@1+ (1,0) [0|0] "" Vector__XXX
 SG_ PARK_sw027_dampResistorFail m27 : 17|1@1+ (1,0) [0|0] "" Vector__XXX
 SG_ PARK_sw028_linBusError m28 : 17|1@1+ (1,0) [0|0] "" Vector__XXX
 SG_ PARK_sw032_dampResistorFail m32 : 17|1@1+ (1,0) [0|0] "" Vector__XXX
 SG_ PARK_sw033_linBusError m33 : 17|1@1+ (1,0) [0|0] "" Vector__XXX
 SG_ PARK_sw037_dampResistorFail m37 : 17|1@1+ (1,0) [0|0] "" Vector__XXX
 SG_ PARK_sw038_linBusError m38 : 17|1@1+ (1,0) [0|0] "" Vector__XXX
 SG_ PARK_sw042_dampResistorFail m42 : 17|1@1+ (1,0) [0|0] "" Vector__XXX
 SG_ PARK_sw043_linBusError m43 : 17|1@1+ (1,0) [0|0] "" Vector__XXX
 SG_ PARK_sw047_dampResistorFail m47 : 17|1@1+ (1,0) [0|0] "" Vector__XXX
 SG_ PARK_sw048_linBusError m48 : 17|1@1+ (1,0) [0|0] "" Vector__XXX
 SG_ PARK_sw052_dampResistorFail m52 : 17|1@1+ (1,0) [0|0] "" Vector__XXX
 SG_ PARK_sw053_linBusError m53 : 17|1@1+ (1,0) [0|0] "" Vector__XXX
 SG_ PARK_sw057_dampResistorFail m57 : 17|1@1+ (1,0) [0|0] "" Vector__XXX
 SG_ PARK_sw058_linBusError m58 : 17|1@1+ (1,0) [0|0] "" Vector__XXX
 SG_ PARK_sw002_resonanceDrift m2 : 18|1@1+ (1,0) [0|0] "" Vector__XXX
 SG_ PARK_sw003_linFrameCountError m3 : 18|1@1+ (1,0) [0|0] "" Vector__XXX
 SG_ PARK_sw007_resonanceDrift m7 : 18|1@1+ (1,0) [0|0] "" Vector__XXX
 SG_ PARK_sw008_linFrameCountError m8 : 18|1@1+ (1,0) [0|0] "" Vector__XXX
 SG_ PARK_sw012_resonanceDrift m12 : 18|1@1+ (1,0) [0|0] "" Vector__XXX
 SG_ PARK_sw013_linFrameCountError m13 : 18|1@1+ (1,0) [0|0] "" Vector__XXX
 SG_ PARK_sw017_resonanceDrift m17 : 18|1@1+ (1,0) [0|0] "" Vector__XXX
 SG_ PARK_sw018_linFrameCountError m18 : 18|1@1+ (1,0) [0|0] "" Vector__XXX
 SG_ PARK_sw022_resonanceDrift m22 : 18|1@1+ (1,0) [0|0] "" Vector__XXX
 SG_ PARK_sw023_linFrameCountError m23 : 18|1@1+ (1,0) [0|0] "" Vector__XXX
 SG_ PARK_sw027_resonanceDrift m27 : 18|1@1+ (1,0) [0|0] "" Vector__XXX
 SG_ PARK_sw028_linFrameCountError m28 : 18|1@1+ (1,0) [0|0] "" Vector__XXX
 SG_ PARK_sw032_resonanceDrift m32 : 18|1@1+ (1,0) [0|0] "" Vector__XXX
 SG_ PARK_sw033_linFrameCountError m33 : 18|1@1+ (1,0) [0|0] "" Vector__XXX
 SG_ PARK_sw037_resonanceDrift m37 : 18|1@1+ (1,0) [0|0] "" Vector__XXX
 SG_ PARK_sw038_linFrameCountError m38 : 18|1@1+ (1,0) [0|0] "" Vector__XXX
 SG_ PARK_sw042_resonanceDrift m42 : 18|1@1+ (1,0) [0|0] "" Vector__XXX
 SG_ PARK_sw043_linFrameCountError m43 : 18|1@1+ (1,0) [0|0] "" Vector__XXX
 SG_ PARK_sw047_resonanceDrift m47 : 18|1@1+ (1,0) [0|0] "" Vector__XXX
 SG_ PARK_sw048_linFrameCountError m48 : 18|1@1+ (1,0) [0|0] "" Vector__XXX
 SG_ PARK_sw052_resonanceDrift m52 : 18|1@1+ (1,0) [0|0] "" Vector__XXX
 SG_ PARK_sw053_linFrameCountError m53 : 18|1@1+ (1,0) [0|0] "" Vector__XXX
 SG_ PARK_sw057_resonanceDrift m57 : 18|1@1+ (1,0) [0|0] "" Vector__XXX
 SG_ PARK_sw058_linFrameCountError m58 : 18|1@1+ (1,0) [0|0] "" Vector__XXX
 SG_ PARK_sw087_s2_sensorType m87 : 18|2@1+ (1,0) [0|0] "" Vector__XXX
 SG_ PARK_sw002_sensorCRC m2 : 19|1@1+ (1,0) [0|0] "" Vector__XXX
 SG_ PARK_sw007_sensorCRC m7 : 19|1@1+ (1,0) [0|0] "" Vector__XXX
 SG_ PARK_sw012_sensorCRC m12 : 19|1@1+ (1,0) [0|0] "" Vector__XXX
 SG_ PARK_sw017_sensorCRC m17 : 19|1@1+ (1,0) [0|0] "" Vector__XXX
 SG_ PARK_sw022_sensorCRC m22 : 19|1@1+ (1,0) [0|0] "" Vector__XXX
 SG_ PARK_sw027_sensorCRC m27 : 19|1@1+ (1,0) [0|0] "" Vector__XXX
 SG_ PARK_sw032_sensorCRC m32 : 19|1@1+ (1,0) [0|0] "" Vector__XXX
 SG_ PARK_sw037_sensorCRC m37 : 19|1@1+ (1,0) [0|0] "" Vector__XXX
 SG_ PARK_sw042_sensorCRC m42 : 19|1@1+ (1,0) [0|0] "" Vector__XXX
 SG_ PARK_sw047_sensorCRC m47 : 19|1@1+ (1,0) [0|0] "" Vector__XXX
 SG_ PARK_sw052_sensorCRC m52 : 19|1@1+ (1,0) [0|0] "" Vector__XXX
 SG_ PARK_sw057_sensorCRC m57 : 19|1@1+ (1,0) [0|0] "" Vector__XXX
 SG_ PARK_sw002_recieveFailure m2 : 20|1@1+ (1,0) [0|0] "" Vector__XXX
 SG_ PARK_sw007_recieveFailure m7 : 20|1@1+ (1,0) [0|0] "" Vector__XXX
 SG_ PARK_sw012_recieveFailure m12 : 20|1@1+ (1,0) [0|0] "" Vector__XXX
 SG_ PARK_sw017_recieveFailure m17 : 20|1@1+ (1,0) [0|0] "" Vector__XXX
 SG_ PARK_sw022_recieveFailure m22 : 20|1@1+ (1,0) [0|0] "" Vector__XXX
 SG_ PARK_sw027_recieveFailure m27 : 20|1@1+ (1,0) [0|0] "" Vector__XXX
 SG_ PARK_sw032_recieveFailure m32 : 20|1@1+ (1,0) [0|0] "" Vector__XXX
 SG_ PARK_sw037_recieveFailure m37 : 20|1@1+ (1,0) [0|0] "" Vector__XXX
 SG_ PARK_sw042_recieveFailure m42 : 20|1@1+ (1,0) [0|0] "" Vector__XXX
 SG_ PARK_sw047_recieveFailure m47 : 20|1@1+ (1,0) [0|0] "" Vector__XXX
 SG_ PARK_sw052_recieveFailure m52 : 20|1@1+ (1,0) [0|0] "" Vector__XXX
 SG_ PARK_sw057_recieveFailure m57 : 20|1@1+ (1,0) [0|0] "" Vector__XXX
 SG_ PARK_sw087_s3_sensorType m87 : 20|2@1+ (1,0) [0|0] "" Vector__XXX
 SG_ PARK_sw002_diagnosticTransferError m2 : 21|1@1+ (1,0) [0|0] "" Vector__XXX
 SG_ PARK_sw007_diagnosticTransferError m7 : 21|1@1+ (1,0) [0|0] "" Vector__XXX
 SG_ PARK_sw012_diagnosticTransferError m12 : 21|1@1+ (1,0) [0|0] "" Vector__XXX
 SG_ PARK_sw017_diagnosticTransferError m17 : 21|1@1+ (1,0) [0|0] "" Vector__XXX
 SG_ PARK_sw022_diagnosticTransferError m22 : 21|1@1+ (1,0) [0|0] "" Vector__XXX
 SG_ PARK_sw027_diagnosticTransferError m27 : 21|1@1+ (1,0) [0|0] "" Vector__XXX
 SG_ PARK_sw032_diagnosticTransferError m32 : 21|1@1+ (1,0) [0|0] "" Vector__XXX
 SG_ PARK_sw037_diagnosticTransferError m37 : 21|1@1+ (1,0) [0|0] "" Vector__XXX
 SG_ PARK_sw042_diagnosticTransferError m42 : 21|1@1+ (1,0) [0|0] "" Vector__XXX
 SG_ PARK_sw047_diagnosticTransferError m47 : 21|1@1+ (1,0) [0|0] "" Vector__XXX
 SG_ PARK_sw052_diagnosticTransferError m52 : 21|1@1+ (1,0) [0|0] "" Vector__XXX
 SG_ PARK_sw057_diagnosticTransferError m57 : 21|1@1+ (1,0) [0|0] "" Vector__XXX
 SG_ PARK_sw087_s4_sensorType m87 : 22|2@1+ (1,0) [0|0] "" Vector__XXX
 SG_ PARK_sw077_errorRx m77 : 24|8@1+ (1,0) [0|0] "" Vector__XXX
 SG_ PARK_sw078_errorRx m78 : 24|8@1+ (1,0) [0|0] "" Vector__XXX
 SG_ PARK_sw079_errorRx m79 : 24|8@1+ (1,0) [0|0] "" Vector__XXX
 SG_ PARK_sw080_errorRx m80 : 24|8@1+ (1,0) [0|0] "" Vector__XXX
 SG_ PARK_sw081_errorRx m81 : 24|8@1+ (1,0) [0|0] "" Vector__XXX
 SG_ PARK_sw082_errorRx m82 : 24|8@1+ (1,0) [0|0] "" Vector__XXX
 SG_ PARK_sw083_errorRx m83 : 24|8@1+ (1,0) [0|0] "" Vector__XXX
 SG_ PARK_sw084_errorRx m84 : 24|8@1+ (1,0) [0|0] "" Vector__XXX
 SG_ PARK_sw086_readRetryCounter m86 : 24|8@1+ (1,0) [0|0] "" Vector__XXX
 SG_ PARK_sw087_s5_sensorType m87 : 24|2@1+ (1,0) [0|0] "" Vector__XXX
 SG_ PARK_sw087_s6_sensorType m87 : 26|2@1+ (1,0) [0|0] "" Vector__XXX
 SG_ PARK_sw087_s7_sensorType m87 : 28|2@1+ (1,0) [0|0] "" Vector__XXX
 SG_ PARK_sw087_s8_sensorType m87 : 30|2@1+ (1,0) [0|0] "" Vector__XXX
 SG_ PARK_sw004_reverbTime m4 : 32|16@1+ (1,0) [0|0] "" Vector__XXX
 SG_ PARK_sw009_reverbTime m9 : 32|16@1+ (1,0) [0|0] "" Vector__XXX
 SG_ PARK_sw014_reverbTime m14 : 32|16@1+ (1,0) [0|0] "" Vector__XXX
 SG_ PARK_sw019_reverbTime m19 : 32|16@1+ (1,0) [0|0] "" Vector__XXX
 SG_ PARK_sw024_reverbTime m24 : 32|16@1+ (1,0) [0|0] "" Vector__XXX
 SG_ PARK_sw029_reverbTime m29 : 32|16@1+ (1,0) [0|0] "" Vector__XXX
 SG_ PARK_sw034_reverbTime m34 : 32|16@1+ (1,0) [0|0] "" Vector__XXX
 SG_ PARK_sw039_reverbTime m39 : 32|16@1+ (1,0) [0|0] "" Vector__XXX
 SG_ PARK_sw044_reverbTime m44 : 32|16@1+ (1,0) [0|0] "" Vector__XXX
 SG_ PARK_sw049_reverbTime m49 : 32|16@1+ (1,0) [0|0] "" Vector__XXX
 SG_ PARK_sw054_reverbTime m54 : 32|16@1+ (1,0) [0|0] "" Vector__XXX
 SG_ PARK_sw059_reverbTime m59 : 32|16@1+ (1,0) [0|0] "" Vector__XXX
 SG_ PARK_sw065_calculatedCRC m65 : 32|16@1+ (1,0) [0|0] "" Vector__XXX
 SG_ PARK_sw077_messageID m77 : 32|12@1+ (1,0) [0|0] "" Vector__XXX
 SG_ PARK_sw078_messageID m78 : 32|12@1+ (1,0) [0|0] "" Vector__XXX
 SG_ PARK_sw079_messageID m79 : 32|12@1+ (1,0) [0|0] "" Vector__XXX
 SG_ PARK_sw080_messageID m80 : 32|12@1+ (1,0) [0|0] "" Vector__XXX
 SG_ PARK_sw081_messageID m81 : 32|12@1+ (1,0) [0|0] "" Vector__XXX
 SG_ PARK_sw082_messageID m82 : 32|12@1+ (1,0) [0|0] "" Vector__XXX
 SG_ PARK_sw083_messageID m83 : 32|12@1+ (1,0) [0|0] "" Vector__XXX
 SG_ PARK_sw084_messageID m84 : 32|12@1+ (1,0) [0|0] "" Vector__XXX
 SG_ PARK_sw086_currentErrorCode m86 : 32|8@1+ (1,0) [0|0] "" Vector__XXX
 SG_ PARK_sw087_s9_sensorType m87 : 32|2@1+ (1,0) [0|0] "" Vector__XXX
 SG_ PARK_sw087_s10_sensorType m87 : 34|2@1+ (1,0) [0|0] "" Vector__XXX
 SG_ PARK_sw087_s11_sensorType m87 : 36|2@1+ (1,0) [0|0] "" Vector__XXX
 SG_ PARK_sw087_s12_sensorType m87 : 38|2@1+ (1,0) [0|0] "" Vector__XXX
 SG_ PARK_sw077_errorType m77 : 44|3@1+ (1,0) [0|0] "" Vector__XXX
 SG_ PARK_sw078_errorType m78 : 44|3@1+ (1,0) [0|0] "" Vector__XXX
 SG_ PARK_sw079_errorType m79 : 44|3@1+ (1,0) [0|0] "" Vector__XXX
 SG_ PARK_sw080_errorType m80 : 44|3@1+ (1,0) [0|0] "" Vector__XXX
 SG_ PARK_sw081_errorType m81 : 44|3@1+ (1,0) [0|0] "" Vector__XXX
 SG_ PARK_sw082_errorType m82 : 44|3@1+ (1,0) [0|0] "" Vector__XXX
 SG_ PARK_sw083_errorType m83 : 44|3@1+ (1,0) [0|0] "" Vector__XXX
 SG_ PARK_sw084_errorType m84 : 44|3@1+ (1,0) [0|0] "" Vector__XXX
 SG_ PARK_sw004_highAttenTime m4 : 48|1@1+ (1,0) [0|0] "" Vector__XXX
 SG_ PARK_sw009_highAttenTime m9 : 48|1@1+ (1,0) [0|0] "" Vector__XXX
 SG_ PARK_sw014_highAttenTime m14 : 48|1@1+ (1,0) [0|0] "" Vector__XXX
 SG_ PARK_sw019_highAttenTime m19 : 48|1@1+ (1,0) [0|0] "" Vector__XXX
 SG_ PARK_sw024_highAttenTime m24 : 48|1@1+ (1,0) [0|0] "" Vector__XXX
 SG_ PARK_sw029_highAttenTime m29 : 48|1@1+ (1,0) [0|0] "" Vector__XXX
 SG_ PARK_sw034_highAttenTime m34 : 48|1@1+ (1,0) [0|0] "" Vector__XXX
 SG_ PARK_sw039_highAttenTime m39 : 48|1@1+ (1,0) [0|0] "" Vector__XXX
 SG_ PARK_sw044_highAttenTime m44 : 48|1@1+ (1,0) [0|0] "" Vector__XXX
 SG_ PARK_sw049_highAttenTime m49 : 48|1@1+ (1,0) [0|0] "" Vector__XXX
 SG_ PARK_sw054_highAttenTime m54 : 48|1@1+ (1,0) [0|0] "" Vector__XXX
 SG_ PARK_sw059_highAttenTime m59 : 48|1@1+ (1,0) [0|0] "" Vector__XXX
 SG_ PARK_sw004_closeConstEcho m4 : 49|1@1+ (1,0) [0|0] "" Vector__XXX
 SG_ PARK_sw009_closeConstEcho m9 : 49|1@1+ (1,0) [0|0] "" Vector__XXX
 SG_ PARK_sw014_closeConstEcho m14 : 49|1@1+ (1,0) [0|0] "" Vector__XXX
 SG_ PARK_sw019_closeConstEcho m19 : 49|1@1+ (1,0) [0|0] "" Vector__XXX
 SG_ PARK_sw024_closeConstEcho m24 : 49|1@1+ (1,0) [0|0] "" Vector__XXX
 SG_ PARK_sw029_closeConstEcho m29 : 49|1@1+ (1,0) [0|0] "" Vector__XXX
 SG_ PARK_sw034_closeConstEcho m34 : 49|1@1+ (1,0) [0|0] "" Vector__XXX
 SG_ PARK_sw039_closeConstEcho m39 : 49|1@1+ (1,0) [0|0] "" Vector__XXX
 SG_ PARK_sw044_closeConstEcho m44 : 49|1@1+ (1,0) [0|0] "" Vector__XXX
 SG_ PARK_sw049_closeConstEcho m49 : 49|1@1+ (1,0) [0|0] "" Vector__XXX
 SG_ PARK_sw054_closeConstEcho m54 : 49|1@1+ (1,0) [0|0] "" Vector__XXX
 SG_ PARK_sw059_closeConstEcho m59 : 49|1@1+ (1,0) [0|0] "" Vector__XXX
 SG_ PARK_sw004_lowAttenTime m4 : 50|1@1+ (1,0) [0|0] "" Vector__XXX
 SG_ PARK_sw009_lowAttenTime m9 : 50|1@1+ (1,0) [0|0] "" Vector__XXX
 SG_ PARK_sw014_lowAttenTime m14 : 50|1@1+ (1,0) [0|0] "" Vector__XXX
 SG_ PARK_sw019_lowAttenTime m19 : 50|1@1+ (1,0) [0|0] "" Vector__XXX
 SG_ PARK_sw024_lowAttenTime m24 : 50|1@1+ (1,0) [0|0] "" Vector__XXX
 SG_ PARK_sw029_lowAttenTime m29 : 50|1@1+ (1,0) [0|0] "" Vector__XXX
 SG_ PARK_sw034_lowAttenTime m34 : 50|1@1+ (1,0) [0|0] "" Vector__XXX
 SG_ PARK_sw039_lowAttenTime m39 : 50|1@1+ (1,0) [0|0] "" Vector__XXX
 SG_ PARK_sw044_lowAttenTime m44 : 50|1@1+ (1,0) [0|0] "" Vector__XXX
 SG_ PARK_sw049_lowAttenTime m49 : 50|1@1+ (1,0) [0|0] "" Vector__XXX
 SG_ PARK_sw054_lowAttenTime m54 : 50|1@1+ (1,0) [0|0] "" Vector__XXX
 SG_ PARK_sw059_lowAttenTime m59 : 50|1@1+ (1,0) [0|0] "" Vector__XXX
 SG_ PARK_sw004_attenTimeJitter m4 : 51|1@1+ (1,0) [0|0] "" Vector__XXX
 SG_ PARK_sw009_attenTimeJitter m9 : 51|1@1+ (1,0) [0|0] "" Vector__XXX
 SG_ PARK_sw014_attenTimeJitter m14 : 51|1@1+ (1,0) [0|0] "" Vector__XXX
 SG_ PARK_sw019_attenTimeJitter m19 : 51|1@1+ (1,0) [0|0] "" Vector__XXX
 SG_ PARK_sw024_attenTimeJitter m24 : 51|1@1+ (1,0) [0|0] "" Vector__XXX
 SG_ PARK_sw029_attenTimeJitter m29 : 51|1@1+ (1,0) [0|0] "" Vector__XXX
 SG_ PARK_sw034_attenTimeJitter m34 : 51|1@1+ (1,0) [0|0] "" Vector__XXX
 SG_ PARK_sw039_attenTimeJitter m39 : 51|1@1+ (1,0) [0|0] "" Vector__XXX
 SG_ PARK_sw044_attenTimeJitter m44 : 51|1@1+ (1,0) [0|0] "" Vector__XXX
 SG_ PARK_sw049_attenTimeJitter m49 : 51|1@1+ (1,0) [0|0] "" Vector__XXX
 SG_ PARK_sw054_attenTimeJitter m54 : 51|1@1+ (1,0) [0|0] "" Vector__XXX
 SG_ PARK_sw059_attenTimeJitter m59 : 51|1@1+ (1,0) [0|0] "" Vector__XXX
 SG_ PARK_sw004_reverbFreqJitter m4 : 52|1@1+ (1,0) [0|0] "" Vector__XXX
 SG_ PARK_sw009_reverbFreqJitter m9 : 52|1@1+ (1,0) [0|0] "" Vector__XXX
 SG_ PARK_sw014_reverbFreqJitter m14 : 52|1@1+ (1,0) [0|0] "" Vector__XXX
 SG_ PARK_sw019_reverbFreqJitter m19 : 52|1@1+ (1,0) [0|0] "" Vector__XXX
 SG_ PARK_sw024_reverbFreqJitter m24 : 52|1@1+ (1,0) [0|0] "" Vector__XXX
 SG_ PARK_sw029_reverbFreqJitter m29 : 52|1@1+ (1,0) [0|0] "" Vector__XXX
 SG_ PARK_sw034_reverbFreqJitter m34 : 52|1@1+ (1,0) [0|0] "" Vector__XXX
 SG_ PARK_sw039_reverbFreqJitter m39 : 52|1@1+ (1,0) [0|0] "" Vector__XXX
 SG_ PARK_sw044_reverbFreqJitter m44 : 52|1@1+ (1,0) [0|0] "" Vector__XXX
 SG_ PARK_sw049_reverbFreqJitter m49 : 52|1@1+ (1,0) [0|0] "" Vector__XXX
 SG_ PARK_sw054_reverbFreqJitter m54 : 52|1@1+ (1,0) [0|0] "" Vector__XXX
 SG_ PARK_sw059_reverbFreqJitter m59 : 52|1@1+ (1,0) [0|0] "" Vector__XXX

BO_ 1487 APS_vbatVoltage: 8 Vector__XXX
 SG_ APS_A_vbatVoltage : 0|12@1+ (0.005689,0) [0|0] "" Vector__XXX
 SG_ APS_B_vbatVoltage : 12|12@1+ (0.005689,0) [0|0] "" Vector__XXX

BO_ 1497 DAS_carLog: 8 Vector__XXX
 SG_ DAS_carLogMultiplexer M : 0|4@1+ (1,0) [0|0] "" Vector__XXX
 SG_ DAS_autosteerUnavailableReason m0 : 4|7@1+ (1,0) [0|0] "" Vector__XXX
 SG_ DAS_closestInLaneTargetDx m4 : 4|12@1+ (0.0625,0) [0|0] "" Vector__XXX
 SG_ DAS_mobileyeVehAebFlag m2 : 4|1@1+ (1,0) [0|0] "" Vector__XXX
 SG_ DAS_radarTarget5_dx m1 : 4|12@1+ (0.0625,0) [0|0] "" Vector__XXX
 SG_ DAS_mobileyePedAebFlag m2 : 5|1@1+ (1,0) [0|0] "" Vector__XXX
 SG_ DAS_mobileyeIPSOapproved m2 : 6|1@1+ (1,0) [0|0] "" Vector__XXX
 SG_ DAS_fcmSteeringOverride m2 : 7|1@1+ (1,0) [0|0] "" Vector__XXX
 SG_ DAS_fcmCollisionStage3Checks m2 : 8|8@1+ (1,0) [0|0] "" Vector__XXX
 SG_ DAS_alcBehaviorAbortReason m0 : 11|4@1+ (1,0) [0|0] "" Vector__XXX
 SG_ DAS_alcBehaviorState m0 : 15|3@1+ (1,0) [0|0] "" Vector__XXX
 SG_ DAS_desiredTarget_dx m3 : 16|8@1+ (0.5,0) [0|0] "" Vector__XXX
 SG_ DAS_fcmThreatAssesmentMode m2 : 16|3@1+ (1,0) [0|0] "" Vector__XXX
 SG_ DAS_secondInLaneTargetDx m4 : 16|12@1+ (0.0625,0) [0|0] "" Vector__XXX
 SG_ DAS_constructionArea m2 : 19|2@1+ (1,0) [0|0] "" Vector__XXX
 SG_ DAS_restrictionLowSpeedTraffic m2 : 21|1@1+ (1,0) [0|0] "" Vector__XXX
 SG_ DAS_associated_rad_object m2 : 22|2@1+ (1,0) [0|0] "" Vector__XXX
 SG_ DAS_LC_handsOnReason m2 : 24|6@1+ (1,0) [0|0] "" Vector__XXX
 SG_ DAS_radarTarget1_dx m1 : 24|12@1+ (0.0625,0) [0|0] "" Vector__XXX
 SG_ DAS_radarTarget2_dx m3 : 24|12@1+ (0.0625,0) [0|0] "" Vector__XXX
 SG_ DAS_closestLeftLaneTargetDx m4 : 28|12@1+ (0.0625,0) [0|0] "" Vector__XXX
 SG_ DAS_ACC_camStatus m2 : 30|2@1+ (1,0) [0|0] "" Vector__XXX
 SG_ DAS_aeb_not_activating_reason m2 : 32|5@1+ (1,0) [0|0] "" Vector__XXX
 SG_ DAS_radarTarget1_VxRel m1 : 36|8@1+ (0.2,-25.6) [0|0] "" Vector__XXX
 SG_ DAS_radarTarget3_dx m3 : 36|12@1+ (0.0625,0) [0|0] "" Vector__XXX
 SG_ DAS_handsOnDetected m2 : 38|2@1+ (1,0) [0|0] "" Vector__XXX
 SG_ DAS_closestRightLaneTargetDx m4 : 40|12@1+ (0.0625,0) [0|0] "" Vector__XXX
 SG_ DAS_driveOnNavUnavailableReason m2 : 40|5@1+ (1,0) [0|0] "" Vector__XXX
 SG_ DAS_accUnavailableReason m2 : 46|7@1+ (1,0) [0|0] "" Vector__XXX
 SG_ DAS_radarTarget4_dx m3 : 48|12@1+ (0.0625,0) [0|0] "" Vector__XXX
 SG_ DAS_closestInLaneTargetVxRel m4 : 52|10@1+ (0.1,-51.1) [0|0] "" Vector__XXX
 SG_ DAS_pmmNotActivatingReason m2 : 53|5@1+ (1,0) [0|0] "" Vector__XXX

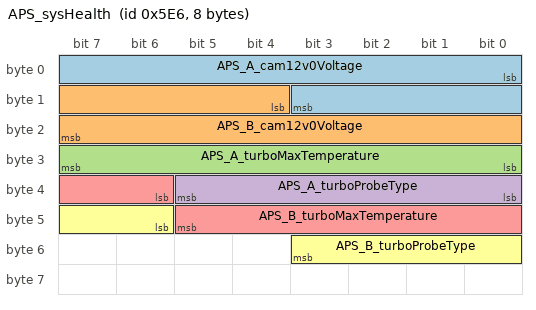
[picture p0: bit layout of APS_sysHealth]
BO_ 1510 APS_sysHealth: 8 Vector__XXX
 SG_ APS_A_cam12v0Voltage : 0|12@1+ (0.0048,0) [0|0] "" Vector__XXX
 SG_ APS_B_cam12v0Voltage : 12|12@1+ (0.0048,0) [0|0] "" Vector__XXX
 SG_ APS_A_turboMaxTemperature : 24|8@1- (1,0) [0|0] "" Vector__XXX
 SG_ APS_A_turboProbeType : 32|6@1+ (1,0) [0|0] "" Vector__XXX
 SG_ APS_B_turboMaxTemperature : 38|8@1- (1,0) [0|0] "" Vector__XXX
 SG_ APS_B_turboProbeType : 46|6@1+ (1,0) [0|0] "" Vector__XXX

VAL_ 1469 IBST_alertID 0 "ALERT_DO_NOT_USE_ZERO" 1 "a001_DriverDoorOpen" 2 "a002_DoorOpen" 3 "a003_TrunkOpen" 4 "a004_FrunkOpen" 5 "a005_HeadlightsOnDoorOpen" 6 "a006_RemoteServiceAlert" 7 "a007_SoftPackConfigMismatch" 8 "a008_TouchScreenError" 9 "a009_SquashfsError" 10 "a010_MapsMissing" 11 "a011_IncorrectMap" 12 "a012_NotOnPrivateProperty" 13 "a013_TPMSHardWarning" 14 "a014_TPMSSoftWarning" 15 "a015_TPMSOverPressureWarning" 16 "a016_TPMSTemperatureWarning" 17 "a017_TPMSSystemFault" 18 "a018_SlipStartOn" 19 "a019_ParkBrakeFault" 20 "a020_SteeringReduced" 21 "a021_RearSeatbeltUnbuckled" 22 "a022_ApeFusesEtc" 23 "a023_CellInternetCheckFailed" 24 "a024_WifiInternetCheckFailed" 25 "a025_WifiOnlineCheckFailed" 26 "a026_ModemResetLoopDetected" 27 "a027_AutoSteerMIA" 28 "a028_FrontTrunkPopupClosed" 29 "a029_ModemMIA" 30 "a030_ModemVMCrash" 31 "a031_BrakeFluidLow" 32 "a032_CellModemRecoveryResets" 33 "a033_ApTrialExpired" 34 "a034_WakeupProblem" 35 "a035_AudioWatchdogKernelError" 36 "a036_AudioWatchdogHfpError" 37 "a037_AudioWatchdogXrunStormError" 38 "a038_AudioWatchdogA2bI2cLockupError" 39 "a039_AudioA2bNeedRediscovery" 40 "a040_HomelinkTransmit" 41 "a041_AudioDmesgXrun" 42 "a042_AudioDmesgRtThrottling" 43 "a043_InvalidMapDataOverride" 44 "a044_AudioDmesgDspException" 45 "a045_ECallNeedsService" 46 "a046_BackupCameraStreamError" 47 "a047_CellRoamingDisallowed" 48 "a048_AudioPremiumAmpCheckFailed" 49 "a049_BrakeShiftRequired" 50 "a050_BackupCameraIPUTimeout" 51 "a051_BackupCameraFrameTimeout" 52 "a052_KernelPanicReported" 53 "a053_QtCarExitError" 54 "a054_AudioBoostPowerBad" 55 "a055_ManualECallDisabled" 56 "a056_ManualECallButtonDisconnected" 57 "a057_CellAntennaDisconnected" 58 "a058_GPSAntennaDisconnected" 59 "a059_ECallSpeakerDisconnected" 60 "a060_ECallMicDisconnected" 61 "a061_SIMTestFailed" 62 "a062_ENSTestFailed" 63 "a063_CellularTestFailed" 64 "a064_ModemFirmwareTestFailed" 65 "a065_WiFiRecoveryReset" 66 "a066_GpuHangDetected" 67 "a067_WarnOnI915" 68 "a068_VideoUnexpectedExit" 69 "a069_VideoUDPTimeout" 70 "a070_VideoPipelineWarning" 71 "a071_VideoPipelineError" 72 "a072_ECallAnalogMicFailed" 73 "a073_ECallDigitalMicFailed" 74 "a074_EMMCHangDetected" 75 "a075_BackupCameraInitError" 76 "a076_NumFalseManualECalls" 77 "a077_AudioA2bMicChannelSwap" 78 "a078_DashcamUsbDriveUnmountable" 79 "a079_DashcamUsbDriveFull" 80 "a080_DashcamUsbDriveSlow" 81 "a081_CellModemSearchExpired" 82 "a082_NumModemRebootStuckInECall" 83 "a083_ECallProxyWatchdogTriggered" 84 "a084_SerializerError" 85 "a085_DeserializerError" 86 "a086_TouchEnumerationError" 87 "a087_BmpReset" 88 "a088_CellRemovableSimMissing" 89 "a089_RadioSoftResetError" 90 "a090_RadioPingFailError" 91 "a091_VehicleLinkStall" 92 "a092_updateStarted" 93 "a093_updateEnded" 94 "a094_ModemPowerOnFailure" 95 "a095_CidStorageRunningLow" 96 "a096_VideodPipelineIssueDetected" 97 "a097_AudiodRestarted" 98 "a098_DiskCheckFailure" 99 "a099_eMMCStatusError" 100 "a100_eMMCFTLError" 101 "a101_wifiStackProblem" 102 "a102_A2bDiscoveryFailed" 103 "a103_UsbHubNotEnumerating" 104 "a104_DashcamUsbDriveMissing" 105 "a105_firmwareReinstallRequested" 106 "a106_rebootBackstopTriggered" 107 "a107_DashcamUsbDriveTooBigForVfatFsck" 108 "a108_DashcamUsbDriveGettingFull" 109 "a109_DashcamUsbDriveTooSmall" 110 "a110_DashcamUsbDriveCorrupt" 111 "a111_DashcamUsbDriveWrongPort" 112 "a112_badUSBDevice" 113 "a113_DashcamHasOnboardSentryClips" ;
VAL_ 1469 IBST_alertState 0 "CLEARED" 1 "SET" ;
VAL_ 1481 APS_alertID 0 "ALERT_DO_NOT_USE_ZERO" 1 "a001_DriverDoorOpen" 2 "a002_DoorOpen" 3 "a003_TrunkOpen" 4 "a004_FrunkOpen" 5 "a005_HeadlightsOnDoorOpen" 6 "a006_RemoteServiceAlert" 7 "a007_SoftPackConfigMismatch" 8 "a008_TouchScreenError" 9 "a009_SquashfsError" 10 "a010_MapsMissing" 11 "a011_IncorrectMap" 12 "a012_NotOnPrivateProperty" 13 "a013_TPMSHardWarning" 14 "a014_TPMSSoftWarning" 15 "a015_TPMSOverPressureWarning" 16 "a016_TPMSTemperatureWarning" 17 "a017_TPMSSystemFault" 18 "a018_SlipStartOn" 19 "a019_ParkBrakeFault" 20 "a020_SteeringReduced" 21 "a021_RearSeatbeltUnbuckled" 22 "a022_ApeFusesEtc" 23 "a023_CellInternetCheckFailed" 24 "a024_WifiInternetCheckFailed" 25 "a025_WifiOnlineCheckFailed" 26 "a026_ModemResetLoopDetected" 27 "a027_AutoSteerMIA" 28 "a028_FrontTrunkPopupClosed" 29 "a029_ModemMIA" 30 "a030_ModemVMCrash" 31 "a031_BrakeFluidLow" 32 "a032_CellModemRecoveryResets" 33 "a033_ApTrialExpired" 34 "a034_WakeupProblem" 35 "a035_AudioWatchdogKernelError" 36 "a036_AudioWatchdogHfpError" 37 "a037_AudioWatchdogXrunStormError" 38 "a038_AudioWatchdogA2bI2cLockupError" 39 "a039_AudioA2bNeedRediscovery" 40 "a040_HomelinkTransmit" 41 "a041_AudioDmesgXrun" 42 "a042_AudioDmesgRtThrottling" 43 "a043_InvalidMapDataOverride" 44 "a044_AudioDmesgDspException" 45 "a045_ECallNeedsService" 46 "a046_BackupCameraStreamError" 47 "a047_CellRoamingDisallowed" 48 "a048_AudioPremiumAmpCheckFailed" 49 "a049_BrakeShiftRequired" 50 "a050_BackupCameraIPUTimeout" 51 "a051_BackupCameraFrameTimeout" 52 "a052_KernelPanicReported" 53 "a053_QtCarExitError" 54 "a054_AudioBoostPowerBad" 55 "a055_ManualECallDisabled" 56 "a056_ManualECallButtonDisconnected" 57 "a057_CellAntennaDisconnected" 58 "a058_GPSAntennaDisconnected" 59 "a059_ECallSpeakerDisconnected" 60 "a060_ECallMicDisconnected" 61 "a061_SIMTestFailed" 62 "a062_ENSTestFailed" 63 "a063_CellularTestFailed" 64 "a064_ModemFirmwareTestFailed" 65 "a065_WiFiRecoveryReset" 66 "a066_GpuHangDetected" 67 "a067_WarnOnI915" 68 "a068_VideoUnexpectedExit" 69 "a069_VideoUDPTimeout" 70 "a070_VideoPipelineWarning" 71 "a071_VideoPipelineError" 72 "a072_ECallAnalogMicFailed" 73 "a073_ECallDigitalMicFailed" 74 "a074_EMMCHangDetected" 75 "a075_BackupCameraInitError" 76 "a076_NumFalseManualECalls" 77 "a077_AudioA2bMicChannelSwap" 78 "a078_DashcamUsbDriveUnmountable" 79 "a079_DashcamUsbDriveFull" 80 "a080_DashcamUsbDriveSlow" 81 "a081_CellModemSearchExpired" 82 "a082_NumModemRebootStuckInECall" 83 "a083_ECallProxyWatchdogTriggered" 84 "a084_SerializerError" 85 "a085_DeserializerError" 86 "a086_TouchEnumerationError" 87 "a087_BmpReset" 88 "a088_CellRemovableSimMissing" 89 "a089_RadioSoftResetError" 90 "a090_RadioPingFailError" 91 "a091_VehicleLinkStall" 92 "a092_updateStarted" 93 "a093_updateEnded" 94 "a094_ModemPowerOnFailure" 95 "a095_CidStorageRunningLow" 96 "a096_VideodPipelineIssueDetected" 97 "a097_AudiodRestarted" 98 "a098_DiskCheckFailure" 99 "a099_eMMCStatusError" 100 "a100_eMMCFTLError" 101 "a101_wifiStackProblem" 102 "a102_A2bDiscoveryFailed" 103 "a103_UsbHubNotEnumerating" 104 "a104_DashcamUsbDriveMissing" 105 "a105_firmwareReinstallRequested" 106 "a106_rebootBackstopTriggered" 107 "a107_DashcamUsbDriveTooBigForVfatFsck" 108 "a108_DashcamUsbDriveGettingFull" 109 "a109_DashcamUsbDriveTooSmall" 110 "a110_DashcamUsbDriveCorrupt" 111 "a111_DashcamUsbDriveWrongPort" 112 "a112_badUSBDevice" 113 "a113_DashcamHasOnboardSentryClips" ;
VAL_ 1481 APS_alertState 0 "CLEARED" 1 "SET" ;
VAL_ 1481 APS_sw030_heaterState 0 "OFF_SNA" 1 "ON" ;
VAL_ 1481 APS_sw042_health_state 0 "STANDBY" 1 "DRIVE" 2 "SUPPORT" 3 "CHARGE" 4 "FEIM" 5 "CLEAR_FAULT" 6 "FAULT" 7 "WELD" 8 "TEST" 9 "SNA" 10 "DIAG" ;
VAL_ 1481 APS_sw043_mobileye_status 0 "DISABLED" 1 "ENABLED" 2 "TEMPORARY_FAILURE" 3 "SNA" ;
VAL_ 1481 APS_sw065_app_mobileye_status 0 "DISABLED" 1 "ENABLED" 2 "TEMPORARY_FAILURE" 3 "SNA" ;
VAL_ 1481 APS_sw066_app_mobileye_status 0 "DISABLED" 1 "ENABLED" 2 "TEMPORARY_FAILURE" 3 "SNA" ;
VAL_ 1481 APS_sw078_camCipv_dx 255 "SNA" ;
VAL_ 1481 APS_sw143_status 0 "DISABLED" 1 "ENABLED" 2 "TEMPORARY_FAILURE" 3 "SNA" ;
VAL_ 1481 APS_sw149_status 0 "DISABLED" 1 "ENABLED" 2 "TEMPORARY_FAILURE" 3 "SNA" ;
VAL_ 1481 APS_sw190_IBST_status 0 "DISABLED" 1 "ENABLED" 2 "TEMPORARY_FAILURE" 3 "SNA" ;
VAL_ 1481 APS_sw288_status 0 "DISABLED" 1 "ENABLED" 2 "TEMPORARY_FAILURE" 3 "SNA" ;
VAL_ 1481 APS_sw035_status 0 "DISABLED" 1 "ENABLED" 2 "TEMPORARY_FAILURE" 3 "SNA" ;
VAL_ 1481 APS_sw064_status 0 "DISABLED" 1 "ENABLED" 2 "TEMPORARY_FAILURE" 3 "SNA" ;
VAL_ 1481 APS_sw146_status 0 "DISABLED" 1 "ENABLED" 2 "TEMPORARY_FAILURE" 3 "SNA" ;
VAL_ 1481 APS_sw219_roadClass 0 "UNKNOWN_INVALID_SNA" 1 "CLASS_1_MAJOR" 2 "CLASS_2" 3 "CLASS_3" 4 "CLASS_4" 5 "CLASS_5" 6 "CLASS_6_MINOR" ;
VAL_ 1481 APS_sw220_roadClass 0 "UNKNOWN_INVALID_SNA" 1 "CLASS_1_MAJOR" 2 "CLASS_2" 3 "CLASS_3" 4 "CLASS_4" 5 "CLASS_5" 6 "CLASS_6_MINOR" ;
VAL_ 1481 APS_sw310_status 0 "DISABLED" 1 "ENABLED" 2 "TEMPORARY_FAILURE" 3 "SNA" ;
VAL_ 1481 APS_sw315_status 0 "DISABLED" 1 "ENABLED" 2 "TEMPORARY_FAILURE" 3 "SNA" ;
VAL_ 1481 APS_sw027_Unused_Bit_0 0 "0" 1 "1" 2 "2" 3 "3" 4 "4" 5 "5" 6 "6" 7 "7" 8 "8" 9 "9" 10 "10" 11 "11" 12 "12" 13 "13" 14 "14" 15 "15" 16 "16" 17 "17" 18 "18" 19 "19" 20 "20" 21 "21" 22 "22" 23 "23" 24 "24" 25 "25" 26 "26" 27 "27" 28 "28" 29 "29" 30 "30" 31 "31" ;
VAL_ 1481 APS_sw059_status 0 "DISABLED" 1 "ENABLED" 2 "TEMPORARY_FAILURE" 3 "SNA" ;
VAL_ 1481 APS_sw140_status 0 "DISABLED" 1 "ENABLED" 2 "TEMPORARY_FAILURE" 3 "SNA" ;
VAL_ 1481 APS_sw227_vehicleSpeed 8191 "SNA" ;
VAL_ 1481 APS_sw142_systemStatus 0 "UNKNOWN" 1 "RELEASED" 2 "PARKED" 3 "DYNAMIC" 4 "PARKING" 5 "RELEASING" 6 "FAULT" 7 "FAULT_SECURE" 8 "MISMATCH" ;
VAL_ 1481 APS_sw025_road_class 0 "SNA" 1 "SUPERCHARGER" 2 "URBANCHARGER" ;
VAL_ 1481 APS_sw047_roadClass 0 "UNKNOWN_INVALID_SNA" 1 "CLASS_1_MAJOR" 2 "CLASS_2" 3 "CLASS_3" 4 "CLASS_4" 5 "CLASS_5" 6 "CLASS_6_MINOR" ;
VAL_ 1481 APS_sw153_eacInternalState 0 "STATE_INIT" 1 "STATE_MOMENTARY" 2 "STATE_CONTINUOUS" 3 "STATE_AUTOPARK" 4 "STATE_INHIBIT" 5 "STATE_OVERRIDE" 6 "STATE_LSS" 7 "NUM_STATES" ;
VAL_ 1481 APS_sw219_vehicleSpeed 8191 "SNA" ;
VAL_ 1481 APS_sw220_vehicleSpeed 8191 "SNA" ;
VAL_ 1481 APS_sw069_eacStatus 0 "INHIBITED" 1 "AVAILABLE" 2 "ACTIVE" 3 "FAULT" 4 "LKA_ELK_AVAILABLE" 5 "LKA_ACTIVE" 6 "ELK_AVAILABLE" 7 "ELK_ACTIVE" ;
VAL_ 1481 APS_sw203_roadClass 0 "UNKNOWN_INVALID_SNA" 1 "CLASS_1_MAJOR" 2 "CLASS_2" 3 "CLASS_3" 4 "CLASS_4" 5 "CLASS_5" 6 "CLASS_6_MINOR" ;
VAL_ 1481 APS_sw004_accState 0 "ACC_CANCEL_GENERIC" 3 "ACC_HOLD" 4 "ACC_ON" 5 "APC_BACKWARD" 6 "APC_FORWARD" 7 "APC_COMPLETE" 8 "APC_ABORT" 9 "APC_PAUSE" 10 "APC_UNPARK_COMPLETE" 11 "APC_SELFPARK_START" 13 "ACC_CANCEL_GENERIC_SILENT" 15 "FAULT_SNA" ;
VAL_ 1481 APS_sw065_mobileye_main_state 0 "STANDBY" 1 "DRIVE" 2 "SUPPORT" 3 "CHARGE" 4 "FEIM" 5 "CLEAR_FAULT" 6 "FAULT" 7 "WELD" 8 "TEST" 9 "SNA" 10 "DIAG" ;
VAL_ 1481 APS_sw066_mobileye_main_state 0 "STANDBY" 1 "DRIVE" 2 "SUPPORT" 3 "CHARGE" 4 "FEIM" 5 "CLEAR_FAULT" 6 "FAULT" 7 "WELD" 8 "TEST" 9 "SNA" 10 "DIAG" ;
VAL_ 1481 APS_sw005_steeringAngle 16383 "SNA" ;
VAL_ 1481 APS_sw043_mesp_health_main_state 0 "STANDBY" 1 "DRIVE" 2 "SUPPORT" 3 "CHARGE" 4 "FEIM" 5 "CLEAR_FAULT" 6 "FAULT" 7 "WELD" 8 "TEST" 9 "SNA" 10 "DIAG" ;
VAL_ 1481 APS_sw078_radarTarg5_dx 255 "SNA" ;
VAL_ 1481 APS_sw083_Targ5_dx 255 "SNA" ;
VAL_ 1481 APS_sw085_roadClass 0 "UNKNOWN_INVALID_SNA" 1 "CLASS_1_MAJOR" 2 "CLASS_2" 3 "CLASS_3" 4 "CLASS_4" 5 "CLASS_5" 6 "CLASS_6_MINOR" ;
VAL_ 1481 APS_sw005_gear 0 "INVALID" 1 "P" 2 "R" 3 "N" 4 "D" 7 "SNA" ;
VAL_ 1481 APS_sw077_vehicleSpeed 8191 "SNA" ;
VAL_ 1481 APS_sw025_offsetSide 0 "NO_OFFSET" 1 "OFFSET_RIGHT_OBJECT" 2 "OFFSET_LEFT_OBJECT" 3 "OFFSET_BOTH_OBJECTS" ;
VAL_ 1481 APS_sw071_roadClass 0 "UNKNOWN_INVALID_SNA" 1 "CLASS_1_MAJOR" 2 "CLASS_2" 3 "CLASS_3" 4 "CLASS_4" 5 "CLASS_5" 6 "CLASS_6_MINOR" ;
VAL_ 1481 APS_sw078_radarTarg5_VxRel 0 "NO_TARGET" ;
VAL_ 1481 APS_sw080_road_class 0 "SNA" 1 "SUPERCHARGER" 2 "URBANCHARGER" ;
VAL_ 1481 APS_sw195_vehicleSpeed 8191 "SNA" ;
VAL_ 1481 APS_sw202_vehicleSpeed 8191 "SNA" ;
VAL_ 1481 APS_sw006_steeringAngle 16383 "SNA" ;
VAL_ 1481 APS_sw069_roadClass 0 "UNKNOWN_INVALID_SNA" 1 "CLASS_1_MAJOR" 2 "CLASS_2" 3 "CLASS_3" 4 "CLASS_4" 5 "CLASS_5" 6 "CLASS_6_MINOR" ;
VAL_ 1481 APS_sw006_gear 0 "INVALID" 1 "P" 2 "R" 3 "N" 4 "D" 7 "SNA" ;
VAL_ 1481 APS_sw071_airSuspension 0 "NONE" ;
VAL_ 1481 APS_sw025_torsionBarTorque 4094 "UNDEFINABLE_DATA" 4095 "SNA" ;
VAL_ 1481 APS_sw078_radarTarg1_dx 255 "SNA" ;
VAL_ 1481 APS_sw082_road_class 0 "SNA" 1 "SUPERCHARGER" 2 "URBANCHARGER" ;
VAL_ 1481 APS_sw199_internalState 0 "NO_MODE_ACTIVE" 1 "PRE_DRIVE_CHECK" 2 "LOCAL_BRAKE_REQUEST" 3 "EXTERNAL_BRAKE_REQUEST" 4 "DIAGNOSTIC" 5 "TRANSITION_TO_IDLE" 6 "POST_DRIVE_CHECK" ;
VAL_ 1481 APS_sw080_cruise_lever_state 0 "STANDBY" 1 "DRIVE" 2 "SUPPORT" 3 "CHARGE" 4 "FEIM" 5 "CLEAR_FAULT" 6 "FAULT" 7 "WELD" 8 "TEST" 9 "SNA" 10 "DIAG" ;
VAL_ 1481 APS_sw006_yawRate 4294934528 "SNA" ;
VAL_ 1481 APS_sw077_oocOffCourseDist_cm 255 "MAX_DOOR_HEIGHT_SNA" ;
VAL_ 1481 APS_sw042_road_class 0 "SNA" 1 "SUPERCHARGER" 2 "URBANCHARGER" ;
VAL_ 1481 APS_sw078_radarTarg1_VxRel 0 "NO_TARGET" ;
VAL_ 1481 APS_sw006_trailerMode 0 "OFF" 1 "ON" ;
VAL_ 1481 APS_sw074_roadClass 0 "UNKNOWN_INVALID_SNA" 1 "CLASS_1_MAJOR" 2 "CLASS_2" 3 "CLASS_3" 4 "CLASS_4" 5 "CLASS_5" 6 "CLASS_6_MINOR" ;
VAL_ 1486 PARK_alertID 0 "ALERT_DO_NOT_USE_ZERO" 1 "a001_DriverDoorOpen" 2 "a002_DoorOpen" 3 "a003_TrunkOpen" 4 "a004_FrunkOpen" 5 "a005_HeadlightsOnDoorOpen" 6 "a006_RemoteServiceAlert" 7 "a007_SoftPackConfigMismatch" 8 "a008_TouchScreenError" 9 "a009_SquashfsError" 10 "a010_MapsMissing" 11 "a011_IncorrectMap" 12 "a012_NotOnPrivateProperty" 13 "a013_TPMSHardWarning" 14 "a014_TPMSSoftWarning" 15 "a015_TPMSOverPressureWarning" 16 "a016_TPMSTemperatureWarning" 17 "a017_TPMSSystemFault" 18 "a018_SlipStartOn" 19 "a019_ParkBrakeFault" 20 "a020_SteeringReduced" 21 "a021_RearSeatbeltUnbuckled" 22 "a022_ApeFusesEtc" 23 "a023_CellInternetCheckFailed" 24 "a024_WifiInternetCheckFailed" 25 "a025_WifiOnlineCheckFailed" 26 "a026_ModemResetLoopDetected" 27 "a027_AutoSteerMIA" 28 "a028_FrontTrunkPopupClosed" 29 "a029_ModemMIA" 30 "a030_ModemVMCrash" 31 "a031_BrakeFluidLow" 32 "a032_CellModemRecoveryResets" 33 "a033_ApTrialExpired" 34 "a034_WakeupProblem" 35 "a035_AudioWatchdogKernelError" 36 "a036_AudioWatchdogHfpError" 37 "a037_AudioWatchdogXrunStormError" 38 "a038_AudioWatchdogA2bI2cLockupError" 39 "a039_AudioA2bNeedRediscovery" 40 "a040_HomelinkTransmit" 41 "a041_AudioDmesgXrun" 42 "a042_AudioDmesgRtThrottling" 43 "a043_InvalidMapDataOverride" 44 "a044_AudioDmesgDspException" 45 "a045_ECallNeedsService" 46 "a046_BackupCameraStreamError" 47 "a047_CellRoamingDisallowed" 48 "a048_AudioPremiumAmpCheckFailed" 49 "a049_BrakeShiftRequired" 50 "a050_BackupCameraIPUTimeout" 51 "a051_BackupCameraFrameTimeout" 52 "a052_KernelPanicReported" 53 "a053_QtCarExitError" 54 "a054_AudioBoostPowerBad" 55 "a055_ManualECallDisabled" 56 "a056_ManualECallButtonDisconnected" 57 "a057_CellAntennaDisconnected" 58 "a058_GPSAntennaDisconnected" 59 "a059_ECallSpeakerDisconnected" 60 "a060_ECallMicDisconnected" 61 "a061_SIMTestFailed" 62 "a062_ENSTestFailed" 63 "a063_CellularTestFailed" 64 "a064_ModemFirmwareTestFailed" 65 "a065_WiFiRecoveryReset" 66 "a066_GpuHangDetected" 67 "a067_WarnOnI915" 68 "a068_VideoUnexpectedExit" 69 "a069_VideoUDPTimeout" 70 "a070_VideoPipelineWarning" 71 "a071_VideoPipelineError" 72 "a072_ECallAnalogMicFailed" 73 "a073_ECallDigitalMicFailed" 74 "a074_EMMCHangDetected" 75 "a075_BackupCameraInitError" 76 "a076_NumFalseManualECalls" 77 "a077_AudioA2bMicChannelSwap" 78 "a078_DashcamUsbDriveUnmountable" 79 "a079_DashcamUsbDriveFull" 80 "a080_DashcamUsbDriveSlow" 81 "a081_CellModemSearchExpired" 82 "a082_NumModemRebootStuckInECall" 83 "a083_ECallProxyWatchdogTriggered" 84 "a084_SerializerError" 85 "a085_DeserializerError" 86 "a086_TouchEnumerationError" 87 "a087_BmpReset" 88 "a088_CellRemovableSimMissing" 89 "a089_RadioSoftResetError" 90 "a090_RadioPingFailError" 91 "a091_VehicleLinkStall" 92 "a092_updateStarted" 93 "a093_updateEnded" 94 "a094_ModemPowerOnFailure" 95 "a095_CidStorageRunningLow" 96 "a096_VideodPipelineIssueDetected" 97 "a097_AudiodRestarted" 98 "a098_DiskCheckFailure" 99 "a099_eMMCStatusError" 100 "a100_eMMCFTLError" 101 "a101_wifiStackProblem" 102 "a102_A2bDiscoveryFailed" 103 "a103_UsbHubNotEnumerating" 104 "a104_DashcamUsbDriveMissing" 105 "a105_firmwareReinstallRequested" 106 "a106_rebootBackstopTriggered" 107 "a107_DashcamUsbDriveTooBigForVfatFsck" 108 "a108_DashcamUsbDriveGettingFull" 109 "a109_DashcamUsbDriveTooSmall" 110 "a110_DashcamUsbDriveCorrupt" 111 "a111_DashcamUsbDriveWrongPort" 112 "a112_badUSBDevice" 113 "a113_DashcamHasOnboardSentryClips" ;
VAL_ 1486 PARK_alertState 0 "CLEARED" 1 "SET" ;
VAL_ 1486 PARK_sw087_s1_sensorType 0 "NONE" 1 "VALEO_HPFL" 2 "VALEO_HP" 3 "SNA" ;
VAL_ 1486 PARK_sw087_s2_sensorType 0 "NONE" 1 "VALEO_HPFL" 2 "VALEO_HP" 3 "SNA" ;
VAL_ 1486 PARK_sw087_s3_sensorType 0 "NONE" 1 "VALEO_HPFL" 2 "VALEO_HP" 3 "SNA" ;
VAL_ 1486 PARK_sw087_s4_sensorType 0 "NONE" 1 "VALEO_HPFL" 2 "VALEO_HP" 3 "SNA" ;
VAL_ 1486 PARK_sw087_s5_sensorType 0 "NONE" 1 "VALEO_HPFL" 2 "VALEO_HP" 3 "SNA" ;
VAL_ 1486 PARK_sw087_s6_sensorType 0 "NONE" 1 "VALEO_HPFL" 2 "VALEO_HP" 3 "SNA" ;
VAL_ 1486 PARK_sw087_s7_sensorType 0 "NONE" 1 "VALEO_HPFL" 2 "VALEO_HP" 3 "SNA" ;
VAL_ 1486 PARK_sw087_s8_sensorType 0 "NONE" 1 "VALEO_HPFL" 2 "VALEO_HP" 3 "SNA" ;
VAL_ 1486 PARK_sw087_s9_sensorType 0 "NONE" 1 "VALEO_HPFL" 2 "VALEO_HP" 3 "SNA" ;
VAL_ 1486 PARK_sw087_s10_sensorType 0 "NONE" 1 "VALEO_HPFL" 2 "VALEO_HP" 3 "SNA" ;
VAL_ 1486 PARK_sw087_s11_sensorType 0 "NONE" 1 "VALEO_HPFL" 2 "VALEO_HP" 3 "SNA" ;
VAL_ 1486 PARK_sw087_s12_sensorType 0 "NONE" 1 "VALEO_HPFL" 2 "VALEO_HP" 3 "SNA" ;
VAL_ 1497 DAS_carLogMultiplexer 0 "FEATURE_STATE" 1 "RADAR" 2 "FCM" 3 "PROFILER" ;
VAL_ 1497 DAS_closestInLaneTargetDx 0 "NO_TARGET" ;
VAL_ 1497 DAS_radarTarget5_dx 0 "NO_TARGET" ;
VAL_ 1497 DAS_desiredTarget_dx 255 "SNA" ;
VAL_ 1497 DAS_secondInLaneTargetDx 0 "NO_TARGET" ;
VAL_ 1497 DAS_radarTarget1_dx 0 "NO_TARGET" ;
VAL_ 1497 DAS_radarTarget2_dx 0 "NO_TARGET" ;
VAL_ 1497 DAS_closestLeftLaneTargetDx 0 "NO_TARGET" ;
VAL_ 1497 DAS_radarTarget1_VxRel 0 "NO_TARGET" ;
VAL_ 1497 DAS_radarTarget3_dx 0 "NO_TARGET" ;
VAL_ 1497 DAS_closestRightLaneTargetDx 0 "NO_TARGET" ;
VAL_ 1497 DAS_radarTarget4_dx 0 "NO_TARGET" ;
VAL_ 1497 DAS_closestInLaneTargetVxRel 0 "NO_TARGET" ;
